VERSION ""

NS_ :

BS_:

BU_: CVC_I MHU TBOX FCAM_I MRR SRR_RL SRR_RR SRR_FL SRR_FR DUMMY_ECU ADCU_I AMP HUD

BO_ 1866 FCAM_Arbitration_Result: 8 FCAM_I
 SG_ CRC_FCAM_Arbitration_Result : 7|8@0+ (1,0) [0|255] ""  MHU,ADCU_I
 SG_ ALIVE_FCAM_Arbitration_Result : 11|4@0+ (1,0) [0|15] ""  MHU,ADCU_I
 SG_ FCAM_Arbitration_Log_Result : 15|4@0+ (1,0) [0|15] ""  MHU,ADCU_I
 SG_ FCAM_Arbitration_Lat_Result : 23|4@0+ (1,0) [0|15] ""  MHU,ADCU_I
 SG_ FCAM_Arbi_Fb : 19|4@0+ (1,0) [0|15] ""  MHU,ADCU_I
 SG_ FCAM_Acore_Diag : 31|4@0+ (1,0) [0|15] ""  MHU,ADCU_I
 SG_ FCAM_Rcore_Diag : 27|4@0+ (1,0) [0|15] ""  MHU,ADCU_I
 SG_ FCAM_Feature_Diag : 39|4@0+ (1,0) [0|15] ""  MHU,ADCU_I
 SG_ FCAM_ErrFCAM_SnSr_Diag : 35|4@0+ (1,0) [0|15] ""  MHU,ADCU_I
 SG_ FCAM_ErrFCAM_Feature_Diag : 47|4@0+ (1,0) [0|15] ""  MHU,ADCU_I
 SG_ FCAM_AACC_Arbitrator_Result : 43|1@0+ (1,0) [0|1] ""  ADCU_I
 SG_ FCAM_AEB_Arbitrator_Result : 42|1@0+ (1,0) [0|1] ""  ADCU_I
 SG_ FCAM_FCTB_Arbitrator_Result : 41|1@0+ (1,0) [0|1] ""  ADCU_I
 SG_ FCAM_ACPE_Arbitrator_Result : 40|1@0+ (1,0) [0|1] ""  ADCU_I
 SG_ FCAM_LCC_Arbitrator_Result : 48|1@0+ (1,0) [0|1] ""  ADCU_I
 SG_ FCAM_NOP_Arbitrator_Result : 49|1@0+ (1,0) [0|1] ""  ADCU_I
 SG_ FCAM_HWAPlus_Arbitrator_Result : 50|1@0+ (1,0) [0|1] ""  ADCU_I
 SG_ FCAM_LKA_Arbitrator_Result : 51|1@0+ (1,0) [0|1] ""  ADCU_I
 SG_ FCAM_ELKA_Arbitrator_Result : 52|1@0+ (1,0) [0|1] ""  ADCU_I
 SG_ FCAM_ESA_Arbitrator_Result : 53|1@0+ (1,0) [0|1] ""  ADCU_I
 SG_ FCAM_Arbitrator_Reserve_1 : 54|1@0+ (1,0) [0|1] ""  ADCU_I
 SG_ FCAM_Arbitrator_Reserve_2 : 55|1@0+ (1,0) [0|1] ""  ADCU_I

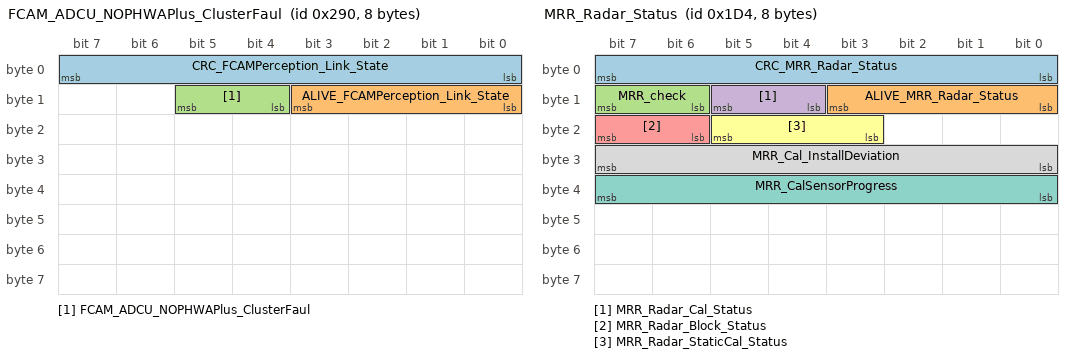
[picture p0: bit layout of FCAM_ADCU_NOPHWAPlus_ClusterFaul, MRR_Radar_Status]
BO_ 656 FCAM_ADCU_NOPHWAPlus_ClusterFaul: 8 FCAM_I
 SG_ CRC_FCAMPerception_Link_State : 7|8@0+ (1,0) [0|255] ""  MHU,ADCU_I
 SG_ ALIVE_FCAMPerception_Link_State : 11|4@0+ (1,0) [0|15] ""  MHU,ADCU_I
 SG_ FCAM_ADCU_NOPHWAPlus_ClusterFaul : 13|2@0+ (1,0) [0|3] ""  MHU,ADCU_I

BO_ 1970 FCAM_Synchronization_Req: 8 FCAM_I
 SG_ FCAM_I_Req_RandomData : 7|24@0+ (1,0) [0|16777215] ""  CVC_I
 SG_ FCAM_I_Req_MAC : 31|40@0+ (1,0) [0|1099511627775] ""  CVC_I

BO_ 468 MRR_Radar_Status: 8 MRR
 SG_ CRC_MRR_Radar_Status : 7|8@0+ (1,0) [0|255] ""  MHU,FCAM_I
 SG_ ALIVE_MRR_Radar_Status : 11|4@0+ (1,0) [0|15] ""  MHU,FCAM_I
 SG_ MRR_check : 15|2@0+ (1,0) [0|3] ""  MHU,FCAM_I
 SG_ MRR_Radar_Cal_Status : 13|2@0+ (1,0) [0|3] ""  MHU,FCAM_I
 SG_ MRR_Radar_Block_Status : 23|2@0+ (1,0) [0|3] ""  MHU,FCAM_I
 SG_ MRR_Radar_StaticCal_Status : 21|3@0+ (1,0) [0|7] ""  MHU,FCAM_I
 SG_ MRR_CalSensorProgress : 39|8@0+ (0.4,0) [0|100] "%"  MHU,FCAM_I
 SG_ MRR_Cal_InstallDeviation : 31|8@0+ (0.1,-12.8) [-12.8|12.7] "deg"  MHU,FCAM_I

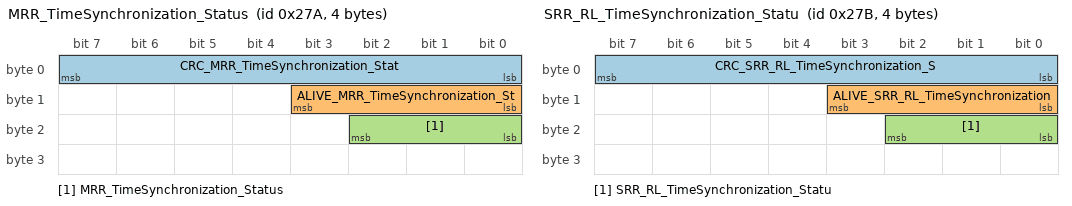
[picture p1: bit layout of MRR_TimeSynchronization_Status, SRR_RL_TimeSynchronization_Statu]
BO_ 634 MRR_TimeSynchronization_Status: 4 MRR
 SG_ CRC_MRR_TimeSynchronization_Stat : 7|8@0+ (1,0) [0|255] ""  FCAM_I,SRR_RL,SRR_RR,SRR_FL,SRR_FR,ADCU_I
 SG_ ALIVE_MRR_TimeSynchronization_St : 11|4@0+ (1,0) [0|15] ""  FCAM_I,SRR_RL,SRR_RR,SRR_FL,SRR_FR,ADCU_I
 SG_ MRR_TimeSynchronization_Status : 18|3@0+ (1,0) [0|4] ""  FCAM_I,SRR_RL,SRR_RR,SRR_FL,SRR_FR,ADCU_I

BO_ 635 SRR_RL_TimeSynchronization_Statu: 4 SRR_RL
 SG_ CRC_SRR_RL_TimeSynchronization_S : 7|8@0+ (1,0) [0|255] ""  FCAM_I,MRR,SRR_RR,SRR_FL,SRR_FR,ADCU_I
 SG_ ALIVE_SRR_RL_TimeSynchronization : 11|4@0+ (1,0) [0|15] ""  FCAM_I,MRR,SRR_RR,SRR_FL,SRR_FR,ADCU_I
 SG_ SRR_RL_TimeSynchronization_Statu : 18|3@0+ (1,0) [0|4] ""  FCAM_I,MRR,SRR_RR,SRR_FL,SRR_FR,ADCU_I

BO_ 831 SRR_RL_ObjList: 64 SRR_RL
 SG_ CRC_SRR_RL_ObjList : 7|8@0+ (1,0) [0|255] ""  MHU
 SG_ ALIVE_SRR_RL_ObjList : 11|4@0+ (1,0) [0|15] ""  MHU
 SG_ RL_Devtimestamp : 23|32@0+ (1,0) [0|4294967295] ""  MHU
 SG_ RL_Obj1_ID : 55|8@0+ (1,0) [0|255] ""  MHU
 SG_ RL_Obj1_DistLong : 63|13@0+ (0.2,-500) [-500|1138.2] ""  MHU
 SG_ RL_Obj1_DislLat : 66|11@0+ (0.2,-204.6) [-204.6|204.8] ""  MHU
 SG_ RL_Obj1_VrelLong : 87|10@0+ (0.25,-128) [-128|127.75] ""  MHU
 SG_ RL_Ob1j_DynProp : 93|3@0+ (1,0) [0|7] ""  MHU
 SG_ RL_Obj1_VrelLat : 90|9@0+ (0.25,-64) [-64|63.75] ""  MHU
 SG_ RL_Obj1_RCS : 97|8@0+ (0.5,-64) [-64|63.5] ""  MHU
 SG_ RL_Obj1_MeasState : 105|3@0+ (1,0) [0|7] ""  MHU
 SG_ RL_Obj1_ProbOfExist : 118|3@0+ (1,0) [0|7] ""  MHU
 SG_ RL_Obj1_ArelLong : 115|11@0+ (0.01,-10) [-10|10.47] ""  MHU
 SG_ RL_Obj1j_Class : 120|3@0+ (1,0) [0|7] ""  MHU
 SG_ RL_Obj1_ArelLat : 133|9@0+ (0.01,-2.5) [-2.5|2.61] ""  MHU
 SG_ RL_Obj1_Length : 151|8@0+ (0.2,0) [0|51] ""  MHU
 SG_ RL_Obj1_Width : 159|8@0+ (0.2,0) [0|51] ""  MHU
 SG_ RL_Obj2_ID : 167|8@0+ (1,0) [0|255] ""  MHU
 SG_ RL_Obj2_DistLong : 175|13@0+ (0.2,-500) [-500|1138.2] ""  MHU
 SG_ RL_Obj2_DislLat : 178|11@0+ (0.2,-204.6) [-204.6|204.8] ""  MHU
 SG_ RL_Obj2_VrelLong : 199|10@0+ (0.25,-128) [-128|127.75] ""  MHU
 SG_ RL_Obj2_DynProp : 205|3@0+ (1,0) [0|7] ""  MHU
 SG_ RL_Obj2_VrelLat : 202|9@0+ (0.25,-64) [-64|63.75] ""  MHU
 SG_ RL_Obj2_RCS : 223|8@0+ (0.5,-64) [-64|63.5] ""  MHU
 SG_ RL_Obj2_MeasState : 231|3@0+ (1,0) [0|7] ""  MHU
 SG_ RL_Obj2_ProbOfExist : 228|3@0+ (1,0) [0|7] ""  MHU
 SG_ RL_Obj2_ArelLong : 225|11@0+ (0.01,-10) [-10|10.47] ""  MHU
 SG_ RL_Obj2j_Class : 246|3@0+ (1,0) [0|7] ""  MHU
 SG_ RL_Obj2_ArelLat : 243|9@0+ (0.01,-2.5) [-2.5|2.61] ""  MHU
 SG_ RL_Obj2_Length : 263|8@0+ (0.2,0) [0|51] ""  MHU
 SG_ RL_Obj2_Width : 271|8@0+ (0.2,0) [0|51] ""  MHU
 SG_ RL_Obj3_ID : 279|8@0+ (1,0) [0|255] ""  MHU
 SG_ RL_Obj3_DistLong : 287|13@0+ (0.2,-500) [-500|1138.2] ""  MHU
 SG_ RL_Obj3_DislLat : 290|11@0+ (0.2,-204.6) [-204.6|204.8] ""  MHU
 SG_ RL_Obj3_VrelLong : 311|10@0+ (0.25,-128) [-128|127.75] ""  MHU
 SG_ RL_Obj3_DynProp : 250|3@0+ (1,0) [0|7] ""  MHU
 SG_ RL_Obj3_VrelLat : 327|9@0+ (0.25,-64) [-64|63.75] ""  MHU
 SG_ RL_Obj3_RCS : 359|8@0+ (0.5,-64) [-64|63.5] ""  MHU
 SG_ RL_Obj3_MeasState : 317|3@0+ (1,0) [0|7] ""  MHU
 SG_ RL_Obj3_ProbOfExist : 314|3@0+ (1,0) [0|7] ""  MHU
 SG_ RL_Obj3_ArelLong : 334|11@0+ (0.01,-10) [-10|10.47] ""  MHU
 SG_ RL_Obj3j_Class : 339|3@0+ (1,0) [0|7] ""  MHU
 SG_ RL_Obj3_ArelLat : 336|9@0+ (0.01,-2.5) [-2.5|2.61] ""  MHU
 SG_ RL_Obj3_Length : 367|8@0+ (0.2,0) [0|51] ""  MHU
 SG_ RL_Obj3_Width : 375|8@0+ (0.2,0) [0|51] ""  MHU
 SG_ RL_Obj4_ID : 383|8@0+ (1,0) [0|255] ""  MHU
 SG_ RL_Obj4_DistLong : 391|13@0+ (0.2,-500) [-500|1138.2] ""  MHU
 SG_ RL_Obj4_DislLat : 394|11@0+ (0.2,-204.6) [-204.6|204.8] ""  MHU
 SG_ RL_Obj4_VrelLong : 415|10@0+ (0.25,-128) [-128|127.75] ""  MHU
 SG_ RL_Obj4_DynProp : 421|3@0+ (1,0) [0|7] ""  MHU
 SG_ RL_Obj4_VrelLat : 418|9@0+ (0.25,-64) [-64|63.75] ""  MHU
 SG_ RL_Obj4_RCS : 439|8@0+ (0.5,-64) [-64|63.5] ""  MHU
 SG_ RL_Obj4_MeasState : 447|3@0+ (1,0) [0|7] ""  MHU
 SG_ RL_Obj4_ProbOfExist : 444|3@0+ (1,0) [0|7] ""  MHU
 SG_ RL_Obj4_ArelLong : 441|11@0+ (0.01,-10) [-10|10.47] ""  MHU
 SG_ RL_Obj4j_Class : 462|3@0+ (1,0) [0|7] ""  MHU
 SG_ RL_Obj4_ArelLat : 459|9@0+ (0.01,-2.5) [-2.5|2.61] ""  MHU
 SG_ RL_Obj4_Length : 479|8@0+ (0.2,0) [0|51] ""  MHU
 SG_ RL_Obj4_Width : 487|8@0+ (0.2,0) [0|51] ""  MHU

BO_ 307 SRR_RR_BSD_RCTA_DOW: 32 SRR_RR
 SG_ CRC_SRR_RR_BSD_RCTA_DOW : 7|8@0+ (1,0) [0|255] ""  CVC_I,MHU,FCAM_I,ADCU_I
 SG_ ALIVE_SRR_RR_BSD_RCTA_DOW : 11|4@0+ (1,0) [0|15] ""  CVC_I,MHU,FCAM_I,ADCU_I
 SG_ SRR_RR_BSD_check : 19|2@0+ (1,0) [0|3] ""  CVC_I,MHU,FCAM_I,ADCU_I
 SG_ SRR_RR_BSD_state : 22|3@0+ (1,0) [0|7] ""  CVC_I,MHU,FCAM_I,ADCU_I
 SG_ SRR_RR_BSD_AudChime_Feed : 23|1@0+ (1,0) [0|1] ""  CVC_I,MHU,FCAM_I,ADCU_I
 SG_ SRR_RR_BSD_IndLeft : 25|2@0+ (1,0) [0|3] ""  CVC_I,MHU,FCAM_I,ADCU_I
 SG_ SRR_RR_BSD_IndRight : 27|2@0+ (1,0) [0|3] ""  CVC_I,MHU,FCAM_I,ADCU_I
 SG_ SRR_RR_BSD_SndWarn : 29|2@0+ (1,0) [0|3] ""  CVC_I,MHU,FCAM_I,ADCU_I
 SG_ SRR_RR_BSD_Mode_Feed : 30|1@0+ (1,0) [0|1] ""  CVC_I,MHU,FCAM_I,ADCU_I
 SG_ SRR_RR_BSD_sens_Feed : 33|2@0+ (1,0) [0|3] ""  CVC_I,MHU,FCAM_I,ADCU_I
 SG_ SRR_RR_RCTA_IndRight : 39|2@0+ (1,0) [0|3] ""  CVC_I,MHU,FCAM_I,ADCU_I
 SG_ SRR_RR_RCTA_IndLeft : 17|2@0+ (1,0) [0|3] ""  CVC_I,MHU,FCAM_I,ADCU_I
 SG_ SRR_RR_RCTA_sens_Feed : 37|2@0+ (1,0) [0|3] ""  CVC_I,MHU,FCAM_I,ADCU_I
 SG_ SRR_RR_RCTA_state : 63|3@0+ (1,0) [0|7] ""  CVC_I,MHU,FCAM_I,ADCU_I
 SG_ SRR_RR_RCTA_SndWarn : 35|2@0+ (1,0) [0|3] ""  CVC_I,MHU,FCAM_I,ADCU_I
 SG_ SRR_RR_RCTA_Mode_Feed : 13|2@0+ (1,0) [0|3] ""  CVC_I,MHU,FCAM_I,ADCU_I
 SG_ SRR_RR_RCTA_check : 47|2@0+ (1,0) [0|3] ""  CVC_I,MHU,FCAM_I,ADCU_I
 SG_ SRR_RR_DOW_SndWarn : 50|2@0+ (1,0) [0|3] ""  CVC_I,MHU,FCAM_I,ADCU_I
 SG_ SRR_RR_DOW_WarnRight : 52|2@0+ (1,0) [0|3] ""  CVC_I,MHU,FCAM_I,ADCU_I
 SG_ SRR_RR_DOW_WarnLeft : 54|2@0+ (1,0) [0|3] ""  CVC_I,MHU,FCAM_I,ADCU_I
 SG_ SRR_RR_DOW_check : 40|2@0+ (1,0) [0|3] ""  CVC_I,MHU,FCAM_I,ADCU_I
 SG_ SRR_RR_DOW_state : 45|3@0+ (1,0) [0|7] ""  CVC_I,MHU,FCAM_I,ADCU_I
 SG_ SRR_RR_DOW_Mode_Feed : 42|2@0+ (1,0) [0|3] ""  CVC_I,MHU,FCAM_I,ADCU_I
 SG_ SRR_RR_Right_block : 15|2@0+ (1,0) [0|3] ""  CVC_I,MHU,FCAM_I,ADCU_I
 SG_ SRR_RR_Left_block : 60|2@0+ (1,0) [0|3] ""  CVC_I,MHU,FCAM_I,ADCU_I
 SG_ Obj_ID_RL : 71|8@0+ (1,0) [0|255] ""  CVC_I,MHU,FCAM_I,ADCU_I
 SG_ Obj_Class_RL : 79|3@0+ (1,0) [0|7] ""  CVC_I,MHU,FCAM_I,ADCU_I
 SG_ Obj_OrientationAngle_RL : 76|10@0+ (0.4,-180) [-180|229.2] "deg"  CVC_I,MHU,FCAM_I,ADCU_I
 SG_ Obj_DistLong_RL : 82|13@0+ (0.2,-500) [-500|1138.2] "m"  CVC_I,MHU,FCAM_I,ADCU_I
 SG_ Obj_DislLat_RL : 101|11@0+ (0.2,-204.6) [-204.6|204.8] "m"  CVC_I,MHU,FCAM_I,ADCU_I
 SG_ Obj_VrelLong_RL : 106|10@0+ (0.25,-128) [-128|127.75] "m/s"  CVC_I,MHU,FCAM_I,ADCU_I
 SG_ Obj_VrelLat_RL : 112|9@0+ (0.25,-64) [-64|63.75] "m/s"  CVC_I,MHU,FCAM_I,ADCU_I
 SG_ Obj_ID_RR : 135|8@0+ (1,0) [0|255] ""  CVC_I,MHU,FCAM_I,ADCU_I
 SG_ Obj_Class_RR : 143|3@0+ (1,0) [0|7] ""  CVC_I,MHU,FCAM_I,ADCU_I
 SG_ Obj_OrientationAngle_RR : 140|10@0+ (0.4,-180) [-180|229.2] "deg"  CVC_I,MHU,FCAM_I,ADCU_I
 SG_ Obj_DistLong_RR : 146|13@0+ (0.2,-500) [-500|1138.2] "m"  CVC_I,MHU,FCAM_I,ADCU_I
 SG_ Obj_DislLat_RR : 165|11@0+ (0.2,-204.6) [-204.6|204.8] "m"  CVC_I,MHU,FCAM_I,ADCU_I
 SG_ Obj_VrelLong_RR : 170|10@0+ (0.25,-128) [-128|127.75] "m/s"  CVC_I,MHU,FCAM_I,ADCU_I
 SG_ Obj_VrelLat_RR : 176|9@0+ (0.25,-64) [-64|63.75] "m/s"  CVC_I,MHU,FCAM_I,ADCU_I
 SG_ SRR_RR_RCTB_Mode_Feed : 193|2@0+ (1,0) [0|3] ""  CVC_I,MHU,FCAM_I,ADCU_I,HUD
 SG_ SRR_RR_RCTB_State : 58|3@0+ (1,0) [0|7] ""  CVC_I,MHU,FCAM_I,ADCU_I,HUD
 SG_ SRR_RR_RCTB_Check : 197|2@0+ (1,0) [0|3] ""  CVC_I,MHU,FCAM_I,ADCU_I,HUD
 SG_ SRR_RR_RCTB_Braking_Flag : 199|2@0+ (1,0) [0|3] ""  CVC_I,MHU,FCAM_I,ADCU_I,HUD
 SG_ SRR_RR_RCTB_Braking_Deceleration : 215|8@0+ (0.1,-6.5) [-6.5|6.5] "m/s2"  CVC_I,MHU,FCAM_I,ADCU_I,HUD
 SG_ SRR_RR_CollisionObjID : 223|8@0+ (1,0) [0|255] ""  CVC_I,MHU,FCAM_I,ADCU_I

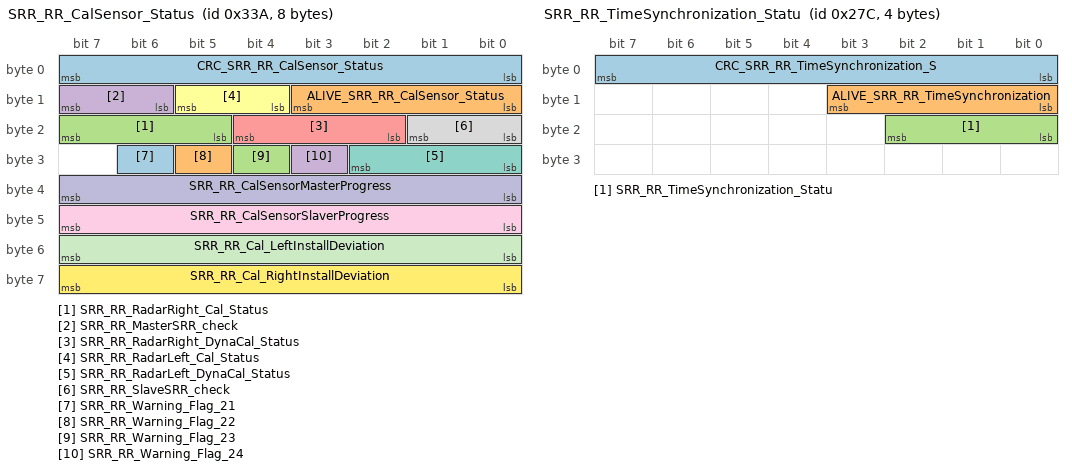
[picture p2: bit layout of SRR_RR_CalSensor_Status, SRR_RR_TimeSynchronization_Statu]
BO_ 826 SRR_RR_CalSensor_Status: 8 SRR_RR
 SG_ CRC_SRR_RR_CalSensor_Status : 7|8@0+ (1,0) [0|255] ""  CVC_I,MHU,FCAM_I,ADCU_I
 SG_ ALIVE_SRR_RR_CalSensor_Status : 11|4@0+ (1,0) [0|15] ""  CVC_I,MHU,FCAM_I,ADCU_I
 SG_ SRR_RR_RadarRight_Cal_Status : 23|3@0+ (1,0) [0|7] ""  CVC_I,MHU,FCAM_I,ADCU_I
 SG_ SRR_RR_MasterSRR_check : 15|2@0+ (1,0) [0|3] ""  CVC_I,MHU,FCAM_I,ADCU_I
 SG_ SRR_RR_RadarRight_DynaCal_Status : 20|3@0+ (1,0) [0|7] ""  CVC_I,MHU,ADCU_I
 SG_ SRR_RR_RadarLeft_Cal_Status : 13|2@0+ (1,0) [0|3] ""  CVC_I,MHU,FCAM_I,ADCU_I
 SG_ SRR_RR_RadarLeft_DynaCal_Status : 26|3@0+ (1,0) [0|7] ""  CVC_I,MHU,ADCU_I
 SG_ SRR_RR_SlaveSRR_check : 17|2@0+ (1,0) [0|3] ""  CVC_I,MHU,ADCU_I
 SG_ SRR_RR_CalSensorSlaverProgress : 47|8@0+ (0.4,0) [0|100] "%"  CVC_I,MHU,ADCU_I
 SG_ SRR_RR_CalSensorMasterProgress : 39|8@0+ (0.4,0) [0|100] "%"  CVC_I,MHU,ADCU_I
 SG_ SRR_RR_Cal_LeftInstallDeviation : 55|8@0+ (0.1,-12.8) [-12.8|12.7] "deg"  CVC_I,MHU,ADCU_I
 SG_ SRR_RR_Cal_RightInstallDeviation : 63|8@0+ (0.1,-12.8) [-12.8|12.7] "deg"  CVC_I,MHU,ADCU_I
 SG_ SRR_RR_Warning_Flag_21 : 30|1@0+ (1,0) [0|1] ""  CVC_I,MHU
 SG_ SRR_RR_Warning_Flag_22 : 29|1@0+ (1,0) [0|1] ""  CVC_I,MHU
 SG_ SRR_RR_Warning_Flag_23 : 28|1@0+ (1,0) [0|1] ""  CVC_I,MHU
 SG_ SRR_RR_Warning_Flag_24 : 27|1@0+ (1,0) [0|1] ""  CVC_I,MHU

BO_ 636 SRR_RR_TimeSynchronization_Statu: 4 SRR_RR
 SG_ CRC_SRR_RR_TimeSynchronization_S : 7|8@0+ (1,0) [0|255] ""  FCAM_I,MRR,SRR_RL,SRR_FL,SRR_FR,ADCU_I
 SG_ ALIVE_SRR_RR_TimeSynchronization : 11|4@0+ (1,0) [0|15] ""  FCAM_I,MRR,SRR_RL,SRR_FL,SRR_FR,ADCU_I
 SG_ SRR_RR_TimeSynchronization_Statu : 18|3@0+ (1,0) [0|4] ""  FCAM_I,MRR,SRR_RL,SRR_FL,SRR_FR,ADCU_I

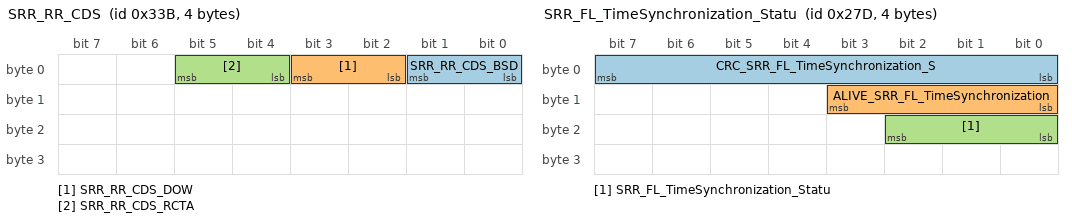
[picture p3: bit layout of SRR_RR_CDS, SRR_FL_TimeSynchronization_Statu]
BO_ 827 SRR_RR_CDS: 4 SRR_RR
 SG_ SRR_RR_CDS_BSD : 1|2@0+ (1,0) [0|3] ""  MHU,FCAM_I,ADCU_I
 SG_ SRR_RR_CDS_DOW : 3|2@0+ (1,0) [0|3] ""  MHU,FCAM_I,ADCU_I
 SG_ SRR_RR_CDS_RCTA : 5|2@0+ (1,0) [0|3] ""  MHU,FCAM_I,ADCU_I

BO_ 830 SRR_RR_ObjList: 64 SRR_RR
 SG_ CRC_SRR_RR_ObjList : 7|8@0+ (1,0) [0|255] ""  MHU
 SG_ ALIVE_SRR_RR_ObjList : 11|4@0+ (1,0) [0|15] ""  MHU
 SG_ RR_Devtimestamp : 23|32@0+ (1,0) [0|4294967295] ""  MHU
 SG_ RR_Obj1_ID : 55|8@0+ (1,0) [0|255] ""  MHU
 SG_ RR_Obj1_DistLong : 63|13@0+ (0.2,-500) [-500|1138.2] ""  MHU
 SG_ RR_Obj1_DislLat : 66|11@0+ (0.2,-204.6) [-204.6|204.8] ""  MHU
 SG_ RR_Obj1_VrelLong : 87|10@0+ (0.25,-128) [-128|127.75] ""  MHU
 SG_ RR_Obj1_DynProp : 93|3@0+ (1,0) [0|7] ""  MHU
 SG_ RR_Obj1_VrelLat : 90|9@0+ (0.25,-64) [-64|63.75] ""  MHU
 SG_ RR_Obj1_RCS : 97|8@0+ (0.5,-64) [-64|63.5] ""  MHU
 SG_ RR_Obj1_MeasState : 105|3@0+ (1,0) [0|7] ""  MHU
 SG_ RR_Obj1_ProbOfExist : 118|3@0+ (1,0) [0|7] ""  MHU
 SG_ RR_Obj1_ArelLong : 115|11@0+ (0.01,-10) [-10|10.47] ""  MHU
 SG_ RR_Obj1j_Class : 120|3@0+ (1,0) [0|7] ""  MHU
 SG_ RR_Obj1_ArelLat : 133|9@0+ (0.01,-2.5) [-2.5|2.61] ""  MHU
 SG_ RR_Obj1_Length : 151|8@0+ (0.2,0) [0|51] ""  MHU
 SG_ RR_Obj1_Width : 159|8@0+ (0.2,0) [0|51] ""  MHU
 SG_ RR_Obj2_ID : 167|8@0+ (1,0) [0|255] ""  MHU
 SG_ RR_Obj2_DistLong : 175|13@0+ (0.2,-500) [-500|1138.2] ""  MHU
 SG_ RR_Obj2_DislLat : 178|11@0+ (0.2,-204.6) [-204.6|204.8] ""  MHU
 SG_ RR_Obj2_VrelLong : 199|10@0+ (0.25,-128) [-128|127.75] ""  MHU
 SG_ RR_Obj2_DynProp : 205|3@0+ (1,0) [0|7] ""  MHU
 SG_ RR_Obj2_VrelLat : 202|9@0+ (0.25,-64) [-64|63.75] ""  MHU
 SG_ RR_Obj2_RCS : 223|8@0+ (0.5,-64) [-64|63.5] ""  MHU
 SG_ RR_Obj2_MeasState : 231|3@0+ (1,0) [0|7] ""  MHU
 SG_ RR_Obj2_ProbOfExist : 228|3@0+ (1,0) [0|7] ""  MHU
 SG_ RR_Obj2_ArelLong : 225|11@0+ (0.01,-10) [-10|10.47] ""  MHU
 SG_ RR_Obj2j_Class : 246|3@0+ (1,0) [0|7] ""  MHU
 SG_ RR_Obj2_ArelLat : 243|9@0+ (0.01,-2.5) [-2.5|2.61] ""  MHU
 SG_ RR_Obj2_Length : 263|8@0+ (0.2,0) [0|51] ""  MHU
 SG_ RR_Obj2_Width : 271|8@0+ (0.2,0) [0|51] ""  MHU
 SG_ RR_Obj3_ID : 279|8@0+ (1,0) [0|255] ""  MHU
 SG_ RR_Obj3_DistLong : 287|13@0+ (0.2,-500) [-500|1138.2] ""  MHU
 SG_ RR_Obj3_DislLat : 290|11@0+ (0.2,-204.6) [-204.6|204.8] ""  MHU
 SG_ RR_Obj3_VrelLong : 311|10@0+ (0.25,-128) [-128|127.75] ""  MHU
 SG_ RR_Obj3_DynProp : 250|3@0+ (1,0) [0|7] ""  MHU
 SG_ RR_Obj3_VrelLat : 327|9@0+ (0.25,-64) [-64|63.75] ""  MHU
 SG_ RR_Obj3_RCS : 359|8@0+ (0.5,-64) [-64|63.5] ""  MHU
 SG_ RR_Obj3_MeasState : 317|3@0+ (1,0) [0|7] ""  MHU
 SG_ RR_Obj3_ProbOfExist : 314|3@0+ (1,0) [0|7] ""  MHU
 SG_ RR_Obj3_ArelLong : 334|11@0+ (0.01,-10) [-10|10.47] ""  MHU
 SG_ RR_Obj3j_Class : 339|3@0+ (1,0) [0|7] ""  MHU
 SG_ RR_Obj3_ArelLat : 336|9@0+ (0.01,-2.5) [-2.5|2.61] ""  MHU
 SG_ RR_Obj3_Length : 367|8@0+ (0.2,0) [0|51] ""  MHU
 SG_ RR_Obj3_Width : 375|8@0+ (0.2,0) [0|51] ""  MHU
 SG_ RR_Obj4_ID : 383|8@0+ (1,0) [0|255] ""  MHU
 SG_ RR_Obj4_DistLong : 391|13@0+ (0.2,-500) [-500|1138.2] ""  MHU
 SG_ RR_Obj4_DislLat : 394|11@0+ (0.2,-204.6) [-204.6|204.8] ""  MHU
 SG_ RR_Obj4_VrelLong : 415|10@0+ (0.25,-128) [-128|127.75] ""  MHU
 SG_ RR_Obj4_DynProp : 421|3@0+ (1,0) [0|7] ""  MHU
 SG_ RR_Obj4_VrelLat : 418|9@0+ (0.25,-64) [-64|63.75] ""  MHU
 SG_ RR_Obj4_RCS : 439|8@0+ (0.5,-64) [-64|63.5] ""  MHU
 SG_ RR_Obj4_MeasState : 447|3@0+ (1,0) [0|7] ""  MHU
 SG_ RR_Obj4_ProbOfExist : 444|3@0+ (1,0) [0|7] ""  MHU
 SG_ RR_Obj4_ArelLong : 441|11@0+ (0.01,-10) [-10|10.47] ""  MHU
 SG_ RR_Obj4j_Class : 462|3@0+ (1,0) [0|7] ""  MHU
 SG_ RR_Obj4_ArelLat : 459|9@0+ (0.01,-2.5) [-2.5|2.61] ""  MHU
 SG_ RR_Obj4_Length : 479|8@0+ (0.2,0) [0|51] ""  MHU
 SG_ RR_Obj4_Width : 487|8@0+ (0.2,0) [0|51] ""  MHU

BO_ 637 SRR_FL_TimeSynchronization_Statu: 4 SRR_FL
 SG_ CRC_SRR_FL_TimeSynchronization_S : 7|8@0+ (1,0) [0|255] ""  FCAM_I,MRR,SRR_RL,SRR_RR,SRR_FR,ADCU_I
 SG_ ALIVE_SRR_FL_TimeSynchronization : 11|4@0+ (1,0) [0|15] ""  FCAM_I,MRR,SRR_RL,SRR_RR,SRR_FR,ADCU_I
 SG_ SRR_FL_TimeSynchronization_Statu : 18|3@0+ (1,0) [0|4] ""  FCAM_I,MRR,SRR_RL,SRR_RR,SRR_FR,ADCU_I

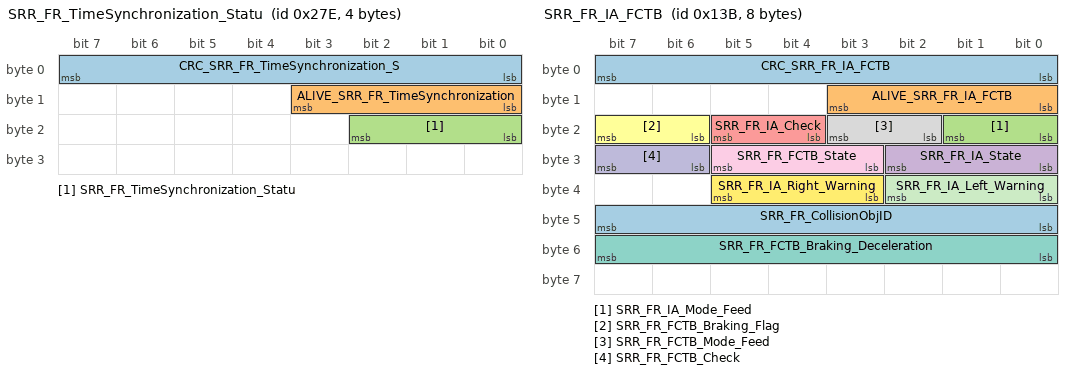
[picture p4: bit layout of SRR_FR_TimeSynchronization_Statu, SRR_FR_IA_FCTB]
BO_ 638 SRR_FR_TimeSynchronization_Statu: 4 SRR_FR
 SG_ CRC_SRR_FR_TimeSynchronization_S : 7|8@0+ (1,0) [0|255] ""  FCAM_I,MRR,SRR_RL,SRR_RR,SRR_FL,ADCU_I
 SG_ ALIVE_SRR_FR_TimeSynchronization : 11|4@0+ (1,0) [0|15] ""  FCAM_I,MRR,SRR_RL,SRR_RR,SRR_FL,ADCU_I
 SG_ SRR_FR_TimeSynchronization_Statu : 18|3@0+ (1,0) [0|4] ""  FCAM_I,MRR,SRR_RL,SRR_RR,SRR_FL,ADCU_I

BO_ 315 SRR_FR_IA_FCTB: 8 SRR_FR
 SG_ CRC_SRR_FR_IA_FCTB : 7|8@0+ (1,0) [0|255] ""  CVC_I,MHU,FCAM_I,ADCU_I,HUD
 SG_ ALIVE_SRR_FR_IA_FCTB : 11|4@0+ (1,0) [0|15] ""  CVC_I,MHU,FCAM_I,ADCU_I,HUD
 SG_ SRR_FR_IA_Mode_Feed : 17|2@0+ (1,0) [0|3] ""  CVC_I,MHU,FCAM_I,ADCU_I,HUD
 SG_ SRR_FR_IA_State : 26|3@0+ (1,0) [0|7] ""  CVC_I,MHU,FCAM_I,ADCU_I,HUD
 SG_ SRR_FR_IA_Check : 21|2@0+ (1,0) [0|3] ""  CVC_I,MHU,FCAM_I,ADCU_I,HUD
 SG_ SRR_FR_FCTB_Braking_Flag : 23|2@0+ (1,0) [0|3] ""  CVC_I,MHU,FCAM_I,ADCU_I,HUD
 SG_ SRR_FR_FCTB_Braking_Deceleration : 55|8@0+ (0.1,-6.5) [-6.5|6.5] "m/s2"  CVC_I,MHU,FCAM_I,ADCU_I,HUD
 SG_ SRR_FR_FCTB_Mode_Feed : 19|2@0+ (1,0) [0|3] ""  CVC_I,MHU,FCAM_I,ADCU_I,HUD
 SG_ SRR_FR_FCTB_State : 29|3@0+ (1,0) [0|7] ""  CVC_I,MHU,FCAM_I,ADCU_I,HUD
 SG_ SRR_FR_FCTB_Check : 31|2@0+ (1,0) [0|3] ""  CVC_I,MHU,FCAM_I,ADCU_I,HUD
 SG_ SRR_FR_IA_Left_Warning : 34|3@0+ (1,0) [0|7] ""  CVC_I,MHU,FCAM_I,ADCU_I,HUD
 SG_ SRR_FR_IA_Right_Warning : 37|3@0+ (1,0) [0|7] ""  CVC_I,MHU,FCAM_I,ADCU_I,HUD
 SG_ SRR_FR_CollisionObjID : 47|8@0+ (1,0) [0|255] ""  CVC_I,MHU,FCAM_I,ADCU_I,HUD

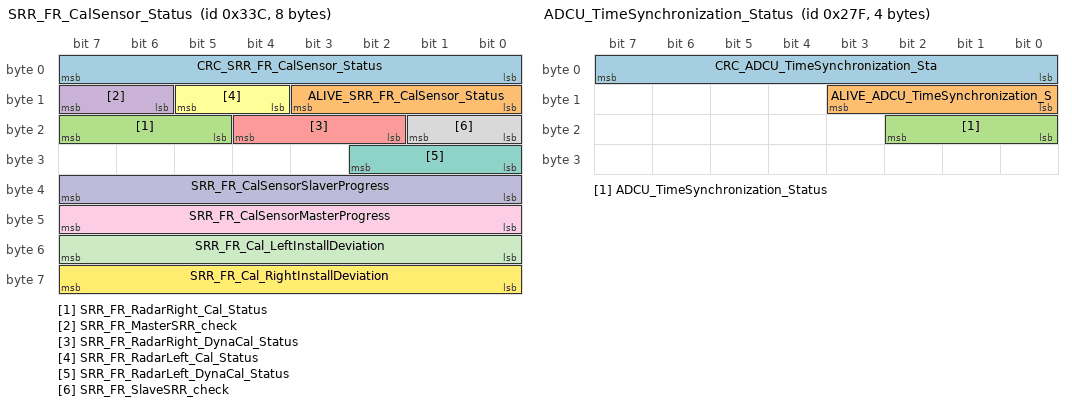
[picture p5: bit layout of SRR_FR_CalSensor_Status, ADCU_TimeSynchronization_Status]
BO_ 828 SRR_FR_CalSensor_Status: 8 SRR_FR
 SG_ CRC_SRR_FR_CalSensor_Status : 7|8@0+ (1,0) [0|255] ""  CVC_I,MHU,FCAM_I,ADCU_I
 SG_ ALIVE_SRR_FR_CalSensor_Status : 11|4@0+ (1,0) [0|15] ""  CVC_I,MHU,FCAM_I,ADCU_I
 SG_ SRR_FR_RadarRight_Cal_Status : 23|3@0+ (1,0) [0|7] ""  CVC_I,MHU,FCAM_I,ADCU_I
 SG_ SRR_FR_MasterSRR_check : 15|2@0+ (1,0) [0|3] ""  CVC_I,MHU,FCAM_I,ADCU_I
 SG_ SRR_FR_RadarRight_DynaCal_Status : 20|3@0+ (1,0) [0|7] ""  CVC_I,MHU,ADCU_I
 SG_ SRR_FR_RadarLeft_Cal_Status : 13|2@0+ (1,0) [0|3] ""  CVC_I,MHU,FCAM_I,ADCU_I
 SG_ SRR_FR_RadarLeft_DynaCal_Status : 26|3@0+ (1,0) [0|7] ""  CVC_I,MHU,ADCU_I
 SG_ SRR_FR_SlaveSRR_check : 17|2@0+ (1,0) [0|3] ""  CVC_I,MHU,ADCU_I
 SG_ SRR_FR_CalSensorMasterProgress : 47|8@0+ (0.4,0) [0|100] "%"  CVC_I,MHU,ADCU_I
 SG_ SRR_FR_CalSensorSlaverProgress : 39|8@0+ (0.4,0) [0|100] "%"  CVC_I,MHU,ADCU_I
 SG_ SRR_FR_Cal_LeftInstallDeviation : 55|8@0+ (0.1,-12.8) [-12.8|12.7] "deg"  CVC_I,MHU
 SG_ SRR_FR_Cal_RightInstallDeviation : 63|8@0+ (0.1,-12.8) [-12.8|12.7] "deg"  CVC_I,MHU

BO_ 639 ADCU_TimeSynchronization_Status: 4 ADCU_I
 SG_ CRC_ADCU_TimeSynchronization_Sta : 7|8@0+ (1,0) [0|255] ""  FCAM_I,MRR,SRR_RL,SRR_RR,SRR_FL,SRR_FR
 SG_ ALIVE_ADCU_TimeSynchronization_S : 11|4@0+ (1,0) [0|15] ""  FCAM_I,MRR,SRR_RL,SRR_RR,SRR_FL,SRR_FR
 SG_ ADCU_TimeSynchronization_Status : 18|3@0+ (1,0) [0|4] ""  FCAM_I,MRR,SRR_RL,SRR_RR,SRR_FL,SRR_FR

BO_ 543 ADCU_AEB_FCW: 12 ADCU_I
 SG_ CRC_ADCU_AEB_FCW : 7|8@0+ (1,0) [0|255] ""  MHU
 SG_ ALIVE_ADCU_AEB_FCW : 11|4@0+ (1,0) [0|15] ""  MHU
 SG_ ADCU_AEB_Warning : 13|2@0+ (1,0) [0|3] ""  MHU
 SG_ ADCU_AEB_State : 16|3@0+ (1,0) [0|7] ""  MHU
 SG_ ADCU_AEB_Mode_Feed : 23|2@0+ (1,0) [0|3] ""  MHU
 SG_ ADCU_AEB_check : 15|2@0+ (1,0) [0|3] ""  MHU
 SG_ ADCU_FCW_Mode_Feed : 21|1@0+ (1,0) [0|1] ""  MHU
 SG_ ADCU_FCW_Sens_Feed : 20|2@0+ (1,0) [0|3] ""  MHU
 SG_ ADCU_FCW_state : 18|2@0+ (1,0) [0|3] ""  MHU
 SG_ ADCU_FCW_check : 41|2@0+ (1,0) [0|3] ""  MHU
 SG_ ADCU_FCW_warning : 43|2@0+ (1,0) [0|3] ""  MHU
 SG_ ADCU_CV_AEB_Alert : 28|1@0+ (1,0) [0|1] ""  MHU
 SG_ ADCU_CV_FCW_Alert : 27|1@0+ (1,0) [0|1] ""  MHU
 SG_ ADCU_CV_PartialAEB_Alert : 26|1@0+ (1,0) [0|1] ""  MHU
 SG_ ADCU_CV_PreFill_Alert : 25|1@0+ (1,0) [0|1] ""  MHU
 SG_ ADCU_VD_AEB_Alert : 32|1@0+ (1,0) [0|1] ""  MHU
 SG_ ADCU_VD_DBS_Alert : 33|1@0+ (1,0) [0|1] ""  MHU
 SG_ ADCU_VD_EGOTAP_AEB_Alert : 34|1@0+ (1,0) [0|1] ""  MHU
 SG_ ADCU_VD_FCW_Alert : 35|1@0+ (1,0) [0|1] ""  MHU
 SG_ ADCU_VD_HeadOn_AEB_Alert : 36|1@0+ (1,0) [0|1] ""  MHU
 SG_ ADCU_VD_PartialAEB_Alert : 37|1@0+ (1,0) [0|1] ""  MHU
 SG_ ADCU_VD_Prefill_Alert : 38|1@0+ (1,0) [0|1] ""  MHU
 SG_ ADCU_VRU_AEB_Alert : 24|1@0+ (1,0) [0|1] ""  MHU
 SG_ ADCU_VRU_FCW_Alert : 39|1@0+ (1,0) [0|1] ""  MHU
 SG_ ADCU_VRU_PreFill_Alert : 29|1@0+ (1,0) [0|1] ""  MHU
 SG_ ADCU_Fusion_TTC : 55|16@0+ (1,0) [0|65535] "ms"  MHU
 SG_ ADCU_AB_TTC : 71|16@0+ (1,0) [0|65535] "ms"  MHU
 SG_ ADCU_AEB_Trigger_Source : 45|2@0+ (1,0) [0|3] ""  MHU
 SG_ ADCU_FCW_Trigger_Source : 47|2@0+ (1,0) [0|3] ""  MHU

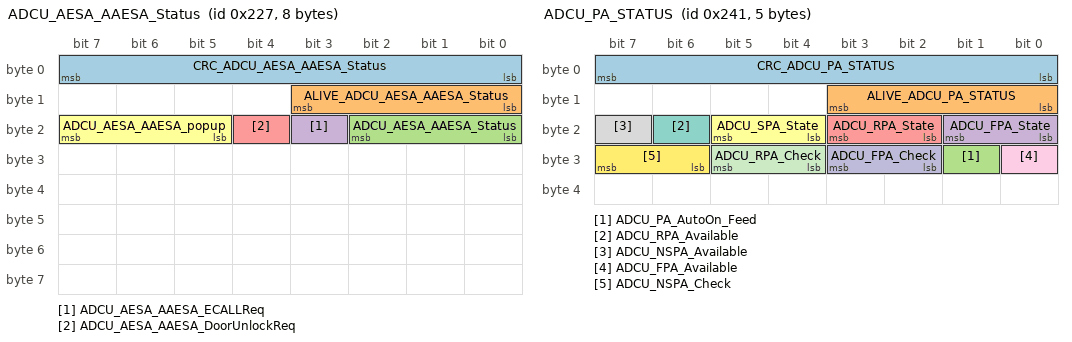
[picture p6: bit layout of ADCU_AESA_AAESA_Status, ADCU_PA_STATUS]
BO_ 551 ADCU_AESA_AAESA_Status: 8 ADCU_I
 SG_ CRC_ADCU_AESA_AAESA_Status : 7|8@0+ (1,0) [0|255] ""  CVC_I,MHU,TBOX
 SG_ ALIVE_ADCU_AESA_AAESA_Status : 11|4@0+ (1,0) [0|15] ""  CVC_I,MHU,TBOX
 SG_ ADCU_AESA_AAESA_Status : 18|3@0+ (1,0) [0|4] ""  CVC_I,MHU,TBOX
 SG_ ADCU_AESA_AAESA_ECALLReq : 19|1@0+ (1,0) [0|1] ""  CVC_I,MHU,TBOX
 SG_ ADCU_AESA_AAESA_DoorUnlockReq : 20|1@0+ (1,0) [0|1] ""  CVC_I,MHU,TBOX
 SG_ ADCU_AESA_AAESA_popup : 23|3@0+ (1,0) [0|6] ""  CVC_I,MHU,TBOX

BO_ 552 ADCU_ESA: 4 ADCU_I
 SG_ ESA_Freespace : 17|2@0+ (1,0) [0|3] ""  FCAM_I

BO_ 556 ADCU_FCAM_NOP_Status: 12 ADCU_I
 SG_ CRC_ADCU_FCAM_NOP_Status : 7|8@0+ (1,0) [0|255] ""  CVC_I,MHU,FCAM_I
 SG_ ALIVE_ADCU_FCAM_NOP_Status : 11|4@0+ (1,0) [0|15] ""  CVC_I,MHU,FCAM_I
 SG_ ADCU_FCAM_ALCA_state : 15|4@0+ (1,0) [0|15] ""  MHU,FCAM_I
 SG_ ADCU_NOP_check : 17|2@0+ (1,0) [0|3] ""  CVC_I,MHU,FCAM_I
 SG_ ADCU_NOP_state : 23|4@0+ (1,0) [0|15] ""  CVC_I,MHU,FCAM_I
 SG_ ADCU_NOP_ICON_Feed : 47|3@0+ (1,0) [0|7] ""  CVC_I,MHU,FCAM_I
 SG_ ADCU_NOP_txtpopup : 28|5@0+ (1,0) [0|31] ""  CVC_I,MHU,FCAM_I
 SG_ ADCU_NOP_Warning : 31|2@0+ (1,0) [0|3] ""  CVC_I,MHU,FCAM_I
 SG_ ADCU_NOP_AAESA_textpopup : 34|3@0+ (1,0) [0|7] ""  CVC_I,MHU,FCAM_I
 SG_ ADCU_NOP_TOR : 37|3@0+ (1,0) [0|7] ""  CVC_I,MHU,FCAM_I
 SG_ ADCU_eyesoff_Warning_Mode_2 : 42|3@0+ (1,0) [0|7] ""  CVC_I,MHU,FCAM_I
 SG_ ADCU_EOD : 43|1@0+ (1,0) [0|1] ""  CVC_I,MHU,FCAM_I
 SG_ ADCU_NOP_Mode_Feed : 19|2@0+ (1,0) [0|3] ""  CVC_I,MHU
 SG_ ADCU_NOP_Type_Feed : 39|2@0+ (1,0) [0|3] ""  CVC_I,MHU
 SG_ ADCU_DCA_Alert : 50|3@0+ (1,0) [0|7] ""  CVC_I,MHU
 SG_ ADCU_AAESA_Status : 53|3@0+ (1,0) [0|7] ""  CVC_I,MHU,FCAM_I
 SG_ ADCU_HWA_ALCA_Status : 63|4@0+ (1,0) [0|10] ""  CVC_I,MHU,FCAM_I
 SG_ ADCU_NOP_ALCA_Status : 59|4@0+ (1,0) [0|10] ""  CVC_I,MHU,FCAM_I
 SG_ ADCU_ALC_Mode_feed : 71|2@0+ (1,0) [0|3] ""  CVC_I,MHU,FCAM_I
 SG_ ADCU_ALC_txtpopup : 69|4@0+ (1,0) [0|15] ""  CVC_I,MHU,FCAM_I
 SG_ ADCU_AESA_popup : 65|3@0+ (1,0) [0|7] ""  CVC_I,MHU,FCAM_I
 SG_ ADCU_ALC_Mode_Gaze_Feed : 55|2@0+ (1,0) [0|3] ""  CVC_I,MHU,FCAM_I
 SG_ ADCU_ALC_Mode_Recommend_Feed : 78|2@0+ (1,0) [0|3] ""  CVC_I,MHU,FCAM_I
 SG_ ADCU_ALC_ICON_Feed : 76|4@0+ (1,0) [0|15] ""  CVC_I,MHU,FCAM_I
 SG_ ADCU_FCAM_NOP_ODD_Sts : 87|2@0+ (1,0) [0|3] ""  MHU,FCAM_I
 SG_ ADCU_FCAM_ALCA_TurnIndicatorReq : 85|3@0+ (1,0) [0|4] ""  CVC_I,MHU,FCAM_I
 SG_ ADCU_FCAM_ALCA_textpopup : 95|4@0+ (1,0) [0|15] ""  MHU,FCAM_I

BO_ 577 ADCU_PA_STATUS: 5 ADCU_I
 SG_ CRC_ADCU_PA_STATUS : 7|8@0+ (1,0) [0|255] ""  MHU
 SG_ ALIVE_ADCU_PA_STATUS : 11|4@0+ (1,0) [0|15] ""  MHU
 SG_ ADCU_PA_AutoOn_Feed : 25|1@0+ (1,0) [0|1] ""  MHU
 SG_ ADCU_FPA_State : 17|2@0+ (1,0) [0|3] ""  MHU
 SG_ ADCU_RPA_State : 19|2@0+ (1,0) [0|3] ""  MHU
 SG_ ADCU_SPA_State : 21|2@0+ (1,0) [0|3] ""  MHU
 SG_ ADCU_RPA_Available : 22|1@0+ (1,0) [0|1] ""  MHU
 SG_ ADCU_NSPA_Available : 23|1@0+ (1,0) [0|1] ""  MHU
 SG_ ADCU_FPA_Available : 24|1@0+ (1,0) [0|1] ""  MHU
 SG_ ADCU_FPA_Check : 27|2@0+ (1,0) [0|3] ""  MHU
 SG_ ADCU_RPA_Check : 29|2@0+ (1,0) [0|3] ""  MHU
 SG_ ADCU_NSPA_Check : 31|2@0+ (1,0) [0|3] ""  MHU

BO_ 579 ADCU_PA_FPA: 12 ADCU_I
 SG_ CRC_ADCU_PA_FPA : 7|8@0+ (1,0) [0|255] ""  MHU
 SG_ ALIVE_ADCU_PA_FPA : 11|4@0+ (1,0) [0|15] ""  MHU
 SG_ ADCU_FPA_AlertFIL : 18|3@0+ (1,0) [0|7] ""  MHU
 SG_ ADCU_FPA_AlertFOL : 21|3@0+ (1,0) [0|7] ""  MHU
 SG_ ADCU_FPA_AlertFIR : 26|3@0+ (1,0) [0|7] ""  MHU
 SG_ ADCU_FPA_AlertFOR : 29|3@0+ (1,0) [0|7] ""  MHU
 SG_ ADCU_FPA_AlertFSL : 34|3@0+ (1,0) [0|7] ""  MHU
 SG_ ADCU_FPA_AlertFSR : 37|3@0+ (1,0) [0|7] ""  MHU
 SG_ ADCU_FPA_DistFIL : 47|8@0+ (1,0) [0|255] ""  MHU
 SG_ ADCU_FPA_DistFOL : 55|8@0+ (1,0) [0|255] ""  MHU
 SG_ ADCU_FPA_DistFIR : 63|8@0+ (1,0) [0|255] ""  MHU
 SG_ ADCU_FPA_DistFOR : 71|8@0+ (1,0) [0|255] ""  MHU
 SG_ ADCU_FPA_DistFSL : 79|8@0+ (1,0) [0|255] ""  MHU
 SG_ ADCU_FPA_DistFSR : 87|8@0+ (1,0) [0|255] ""  MHU
 SG_ ADCU_FPA_ChimeReqFIL : 22|1@0+ (1,0) [0|1] ""  MHU
 SG_ ADCU_FPA_ChimeReqFOL : 23|1@0+ (1,0) [0|1] ""  MHU
 SG_ ADCU_FPA_ChimeReqFIR : 30|1@0+ (1,0) [0|1] ""  MHU
 SG_ ADCU_FPA_ChimeReqFOR : 31|1@0+ (1,0) [0|1] ""  MHU
 SG_ ADCU_FPA_ChimeReqFSL : 38|1@0+ (1,0) [0|1] ""  MHU
 SG_ ADCU_FPA_ChimeReqFSR : 39|1@0+ (1,0) [0|1] ""  MHU

BO_ 580 ADCU_PA_RPA: 12 ADCU_I
 SG_ CRC_ADCU_PA_RPA : 7|8@0+ (1,0) [0|255] ""  MHU
 SG_ ALIVE_ADCU_PA_RPA : 11|4@0+ (1,0) [0|15] ""  MHU
 SG_ ADCU_RPA_AlertRIL : 18|3@0+ (1,0) [0|7] ""  MHU
 SG_ ADCU_RPA_AlertROL : 21|3@0+ (1,0) [0|7] ""  MHU
 SG_ ADCU_RPA_AlertRIR : 26|3@0+ (1,0) [0|7] ""  MHU
 SG_ ADCU_RPA_AlertROR : 29|3@0+ (1,0) [0|7] ""  MHU
 SG_ ADCU_RPA_AlertRSL : 34|3@0+ (1,0) [0|7] ""  MHU
 SG_ ADCU_RPA_AlertRSR : 37|3@0+ (1,0) [0|7] ""  MHU
 SG_ ADCU_RPA_DistRIL : 47|8@0+ (1,0) [0|255] ""  MHU
 SG_ ADCU_RPA_DistROL : 55|8@0+ (1,0) [0|255] ""  MHU
 SG_ ADCU_RPA_DistRIR : 63|8@0+ (1,0) [0|255] ""  MHU
 SG_ ADCU_RPA_DistROR : 71|8@0+ (1,0) [0|255] ""  MHU
 SG_ ADCU_RPA_DistRSL : 79|8@0+ (1,0) [0|255] ""  MHU
 SG_ ADCU_RPA_DistRSR : 87|8@0+ (1,0) [0|255] ""  MHU
 SG_ ADCU_RPA_ChimeReqRIL : 22|1@0+ (1,0) [0|1] ""  MHU
 SG_ ADCU_RPA_ChimeReqROL : 23|1@0+ (1,0) [0|1] ""  MHU
 SG_ ADCU_RPA_ChimeReqRIR : 30|1@0+ (1,0) [0|1] ""  MHU
 SG_ ADCU_RPA_ChimeReqROR : 31|1@0+ (1,0) [0|1] ""  MHU
 SG_ ADCU_RPA_ChimeReqRSL : 38|1@0+ (1,0) [0|1] ""  MHU
 SG_ ADCU_RPA_ChimeReqRSR : 39|1@0+ (1,0) [0|1] ""  MHU

BO_ 582 ADCU_PA_NSPA: 16 ADCU_I
 SG_ CRC_ADCU_PA_NSPA : 7|8@0+ (1,0) [0|255] ""  MHU
 SG_ ALIVE_ADCU_PA_NSPA : 11|4@0+ (1,0) [0|15] ""  MHU
 SG_ ADCU_NSPA_AlertFSL1 : 18|3@0+ (1,0) [0|7] ""  MHU
 SG_ ADCU_NSPA_AlertFSL2 : 21|3@0+ (1,0) [0|7] ""  MHU
 SG_ ADCU_NSPA_AlertFSR1 : 26|3@0+ (1,0) [0|7] ""  MHU
 SG_ ADCU_NSPA_AlertFSR2 : 29|3@0+ (1,0) [0|7] ""  MHU
 SG_ ADCU_NSPA_AlertRSL1 : 34|3@0+ (1,0) [0|7] ""  MHU
 SG_ ADCU_NSPA_AlertRSL2 : 37|3@0+ (1,0) [0|7] ""  MHU
 SG_ ADCU_NSPA_AlertRSR1 : 42|3@0+ (1,0) [0|7] ""  MHU
 SG_ ADCU_NSPA_AlertRSR2 : 45|3@0+ (1,0) [0|7] ""  MHU
 SG_ ADCU_NSPA_DistFSL1 : 55|8@0+ (1,0) [0|255] ""  MHU
 SG_ ADCU_NSPA_DistFSL2 : 63|8@0+ (1,0) [0|255] ""  MHU
 SG_ ADCU_NSPA_DistFSR1 : 71|8@0+ (1,0) [0|255] ""  MHU
 SG_ ADCU_NSPA_DistFSR2 : 79|8@0+ (1,0) [0|255] ""  MHU
 SG_ ADCU_NSPA_DistRSL1 : 87|8@0+ (1,0) [0|255] ""  MHU
 SG_ ADCU_NSPA_DistRSL2 : 95|8@0+ (1,0) [0|255] ""  MHU
 SG_ ADCU_NSPA_DistRSR1 : 103|8@0+ (1,0) [0|255] ""  MHU
 SG_ ADCU_NSPA_DistRSR2 : 111|8@0+ (1,0) [0|255] ""  MHU
 SG_ ADCU_NSPA_ChimeReqFSL1 : 22|1@0+ (1,0) [0|1] ""  MHU
 SG_ ADCU_NSPA_ChimeReqFSL2 : 23|1@0+ (1,0) [0|1] ""  MHU
 SG_ ADCU_NSPA_ChimeReqFSR1 : 30|1@0+ (1,0) [0|1] ""  MHU
 SG_ ADCU_NSPA_ChimeReqFSR2 : 31|1@0+ (1,0) [0|1] ""  MHU
 SG_ ADCU_NSPA_ChimeReqRSL1 : 38|1@0+ (1,0) [0|1] ""  MHU
 SG_ ADCU_NSPA_ChimeReqRSL2 : 39|1@0+ (1,0) [0|1] ""  MHU
 SG_ ADCU_NSPA_ChimeReqRSR1 : 46|1@0+ (1,0) [0|1] ""  MHU
 SG_ ADCU_NSPA_ChimeReqRSR2 : 47|1@0+ (1,0) [0|1] ""  MHU

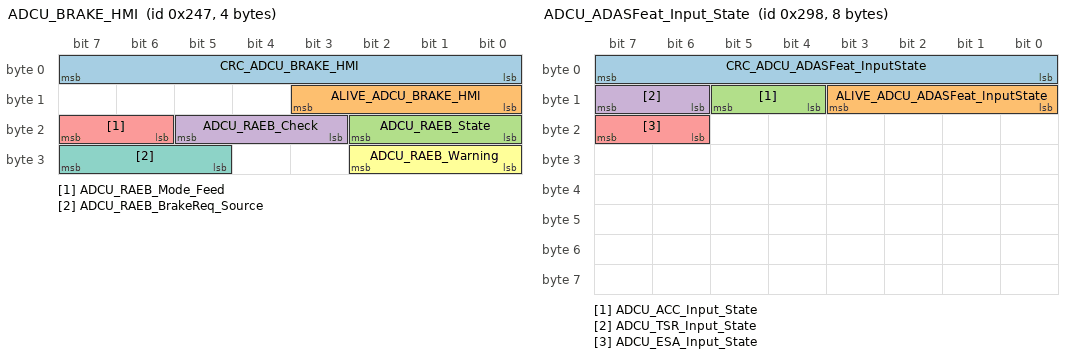
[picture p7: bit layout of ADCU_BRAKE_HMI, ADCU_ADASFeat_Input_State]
BO_ 583 ADCU_BRAKE_HMI: 4 ADCU_I
 SG_ CRC_ADCU_BRAKE_HMI : 7|8@0+ (1,0) [0|255] ""  CVC_I,MHU,FCAM_I
 SG_ ALIVE_ADCU_BRAKE_HMI : 11|4@0+ (1,0) [0|15] ""  CVC_I,MHU,FCAM_I
 SG_ ADCU_RAEB_State : 18|3@0+ (1,0) [0|7] ""  MHU
 SG_ ADCU_RAEB_Check : 21|3@0+ (1,0) [0|7] ""  MHU
 SG_ ADCU_RAEB_Mode_Feed : 23|2@0+ (1,0) [0|3] ""  MHU
 SG_ ADCU_RAEB_Warning : 26|3@0+ (1,0) [0|7] ""  MHU
 SG_ ADCU_RAEB_BrakeReq_Source : 31|3@0+ (1,0) [0|7] ""  CVC_I,MHU,FCAM_I

BO_ 605 ADCU_DrvPark_St: 8 ADCU_I
 SG_ ADCU_Driving_Parking_state : 23|4@0+ (1,0) [0|15] ""  FCAM_I

BO_ 664 ADCU_ADASFeat_Input_State: 8 ADCU_I
 SG_ CRC_ADCU_ADASFeat_InputState : 7|8@0+ (1,0) [0|255] ""  MHU,FCAM_I
 SG_ ALIVE_ADCU_ADASFeat_InputState : 11|4@0+ (1,0) [0|15] ""  MHU,FCAM_I
 SG_ ADCU_ACC_Input_State : 13|2@0+ (1,0) [0|3] ""  MHU,FCAM_I
 SG_ ADCU_TSR_Input_State : 15|2@0+ (1,0) [0|3] ""  MHU,FCAM_I
 SG_ ADCU_ESA_Input_State : 23|2@0+ (1,0) [0|3] ""  MHU,FCAM_I

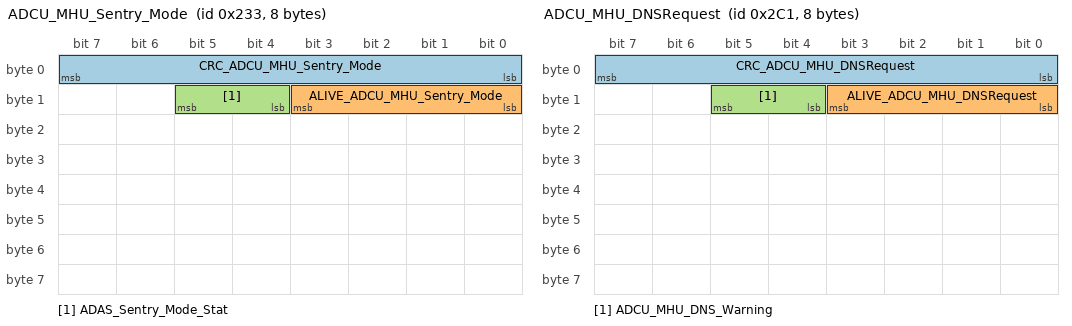
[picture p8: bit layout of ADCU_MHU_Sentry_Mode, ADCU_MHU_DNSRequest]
BO_ 563 ADCU_MHU_Sentry_Mode: 8 ADCU_I
 SG_ CRC_ADCU_MHU_Sentry_Mode : 7|8@0+ (1,0) [0|255] ""  MHU
 SG_ ALIVE_ADCU_MHU_Sentry_Mode : 11|4@0+ (1,0) [0|15] ""  MHU
 SG_ ADAS_Sentry_Mode_Stat : 13|2@0+ (1,0) [0|3] ""  MHU

BO_ 705 ADCU_MHU_DNSRequest: 8 ADCU_I
 SG_ CRC_ADCU_MHU_DNSRequest : 7|8@0+ (1,0) [0|255] ""  MHU
 SG_ ALIVE_ADCU_MHU_DNSRequest : 11|4@0+ (1,0) [0|15] ""  MHU
 SG_ ADCU_MHU_DNS_Warning : 13|2@0+ (1,0) [0|3] ""  MHU

BO_ 586 ADCU_ACPE_CMD: 16 ADCU_I
 SG_ CRC_ADCU_ACPE_CMD : 7|8@0+ (1,0) [0|255] ""  CVC_I,MHU,FCAM_I
 SG_ ALIVE_ADCU_ACPE_CMD : 11|4@0+ (1,0) [0|15] ""  CVC_I,MHU,FCAM_I
 SG_ ADCU_ACPE_PowerCommand : 18|3@0+ (1,0) [0|7] ""  CVC_I,MHU,FCAM_I
 SG_ ADCU_ACPE_BrakeCommand : 21|2@0+ (1,0) [0|3] ""  CVC_I,MHU,FCAM_I
 SG_ ADCU_ACPE_Available : 23|2@0+ (1,0) [0|3] ""  CVC_I,MHU,FCAM_I
 SG_ ADCU_ACPE_FuncActive : 19|1@0+ (1,0) [0|1] ""  CVC_I,MHU,FCAM_I
 SG_ ADCU_ACPE_HMICommand : 26|3@0+ (1,0) [0|7] ""  CVC_I,MHU,FCAM_I
 SG_ ADCU_ACPE_State : 29|3@0+ (1,0) [0|7] ""  CVC_I,MHU,FCAM_I
 SG_ ADCU_ACPE_Setting_Feed : 31|2@0+ (1,0) [0|3] ""  CVC_I,MHU,FCAM_I
 SG_ ADCU_ACPE_Sens_Feed : 33|2@0+ (1,0) [0|3] ""  CVC_I,MHU,FCAM_I
 SG_ ADCU_ACPE_Check : 36|3@0+ (1,0) [0|7] ""  CVC_I,MHU,FCAM_I
 SG_ ADCU_ACPE_TargetDeccel : 47|8@0+ (0.1,-6.5) [-6.5|6.5] "m/s2"  CVC_I,MHU,FCAM_I
 SG_ ACPE_FrontControler_Operate : 55|3@0+ (1,0) [0|7] ""  CVC_I,MHU,FCAM_I
 SG_ ACPE_RearControler_Operate : 52|3@0+ (1,0) [0|7] ""  CVC_I,MHU,FCAM_I

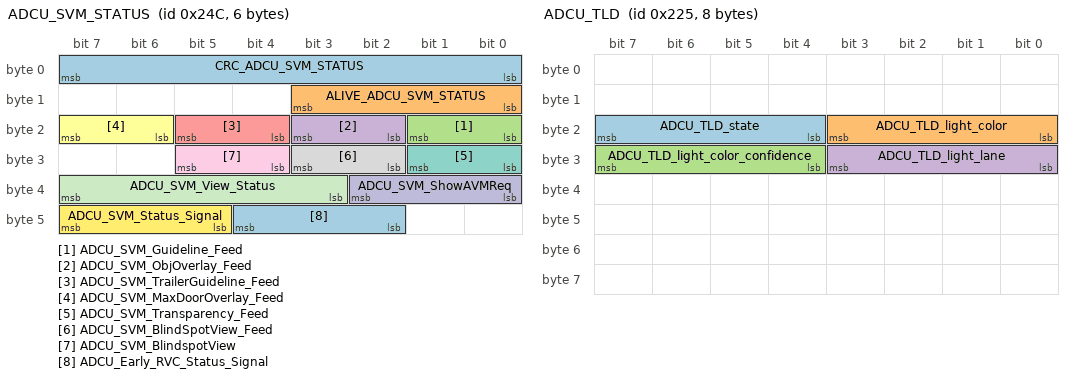
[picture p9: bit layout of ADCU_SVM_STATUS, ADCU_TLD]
BO_ 588 ADCU_SVM_STATUS: 6 ADCU_I
 SG_ CRC_ADCU_SVM_STATUS : 7|8@0+ (1,0) [0|255] ""  MHU
 SG_ ALIVE_ADCU_SVM_STATUS : 11|4@0+ (1,0) [0|14] ""  MHU
 SG_ ADCU_SVM_Guideline_Feed : 17|2@0+ (1,0) [0|3] ""  MHU
 SG_ ADCU_SVM_ObjOverlay_Feed : 19|2@0+ (1,0) [0|3] ""  MHU
 SG_ ADCU_SVM_TrailerGuideline_Feed : 21|2@0+ (1,0) [0|3] ""  MHU
 SG_ ADCU_SVM_MaxDoorOverlay_Feed : 23|2@0+ (1,0) [0|3] ""  MHU
 SG_ ADCU_SVM_Transparency_Feed : 25|2@0+ (1,0) [0|3] ""  MHU
 SG_ ADCU_SVM_BlindSpotView_Feed : 27|2@0+ (1,0) [0|3] ""  MHU
 SG_ ADCU_SVM_BlindspotView : 29|2@0+ (1,0) [0|3] ""  MHU
 SG_ ADCU_SVM_ShowAVMReq : 34|3@0+ (1,0) [0|7] ""  MHU
 SG_ ADCU_SVM_View_Status : 39|5@0+ (1,0) [0|31] ""  MHU
 SG_ ADCU_SVM_Status_Signal : 47|3@0+ (1,0) [0|7] ""  MHU
 SG_ ADCU_Early_RVC_Status_Signal : 44|3@0+ (1,0) [0|7] ""  MHU

BO_ 602 ADCU_SYS_HEALTH: 12 ADCU_I
 SG_ CRC_ADCU_SYS_HEALTH : 7|8@0+ (1,0) [0|255] ""  CVC_I,MHU,FCAM_I
 SG_ ALIVE_ADCU_SYS_HEALTH : 11|4@0+ (1,0) [0|15] ""  CVC_I,MHU,FCAM_I
 SG_ ADCU_SVM_FrontCam_Check : 17|2@0+ (1,0) [0|3] ""  CVC_I,MHU,FCAM_I
 SG_ ADCU_SVM_RearCam_Check : 19|2@0+ (1,0) [0|3] ""  CVC_I,MHU,FCAM_I
 SG_ ADCU_SVM_LeftCamera_Check : 21|2@0+ (1,0) [0|3] ""  CVC_I,MHU,FCAM_I
 SG_ ADCU_SVM_RightCamera_Check : 23|2@0+ (1,0) [0|3] ""  CVC_I,MHU,FCAM_I
 SG_ ADCU_TopRearCamera_Check : 25|2@0+ (1,0) [0|3] ""  CVC_I,MHU,FCAM_I
 SG_ ADCU_USS_FIL_Check : 27|2@0+ (1,0) [0|3] ""  CVC_I,MHU,FCAM_I
 SG_ ADCU_USS_FIR_Check : 29|2@0+ (1,0) [0|3] ""  CVC_I,MHU,FCAM_I
 SG_ ADCU_USS_FOL_Check : 31|2@0+ (1,0) [0|3] ""  CVC_I,MHU,FCAM_I
 SG_ ADCU_USS_FOR_Check : 33|2@0+ (1,0) [0|3] ""  CVC_I,MHU,FCAM_I
 SG_ ADCU_USS_FSL_Check : 35|2@0+ (1,0) [0|3] ""  CVC_I,MHU,FCAM_I
 SG_ ADCU_USS_FSR_Check : 37|2@0+ (1,0) [0|3] ""  CVC_I,MHU,FCAM_I
 SG_ ADCU_USS_RIL_Check : 39|2@0+ (1,0) [0|3] ""  CVC_I,MHU,FCAM_I
 SG_ ADCU_USS_RIR_Check : 41|2@0+ (1,0) [0|3] ""  CVC_I,MHU,FCAM_I
 SG_ ADCU_USS_ROL_Check : 43|2@0+ (1,0) [0|3] ""  CVC_I,MHU,FCAM_I
 SG_ ADCU_USS_ROR_Check : 45|2@0+ (1,0) [0|3] ""  CVC_I,MHU,FCAM_I
 SG_ ADCU_USS_RSL_Check : 47|2@0+ (1,0) [0|3] ""  CVC_I,MHU,FCAM_I
 SG_ ADCU_USS_RSR_Check : 49|2@0+ (1,0) [0|3] ""  CVC_I,MHU,FCAM_I
 SG_ ADCU_SVM_GMSL_Check : 51|2@0+ (1,0) [0|3] ""  CVC_I,MHU,FCAM_I
 SG_ ADCU_OS_Check : 54|3@0+ (1,0) [0|7] ""  CVC_I,MHU,FCAM_I
 SG_ ADCU_ERROR_CODE : 63|32@0+ (1,0) [0|4294967295] ""  CVC_I,MHU,FCAM_I
 SG_ ADCU_ErrFCAM_SnSr_Diag : 95|4@0+ (1,0) [0|15] ""  CVC_I,MHU,FCAM_I
 SG_ ADCU_ErrFCAM_Feature_Diag : 91|4@0+ (1,0) [0|15] ""  CVC_I,MHU,FCAM_I

BO_ 549 ADCU_TLD: 8 ADCU_I
 SG_ ADCU_TLD_state : 23|4@0+ (1,0) [0|15] ""  MHU,FCAM_I
 SG_ ADCU_TLD_light_color : 19|4@0+ (1,0) [0|15] ""  MHU,FCAM_I
 SG_ ADCU_TLD_light_color_confidence : 31|4@0+ (0.1,0) [0|1] ""  MHU,FCAM_I
 SG_ ADCU_TLD_light_lane : 27|4@0+ (1,0) [0|15] ""  MHU,FCAM_I

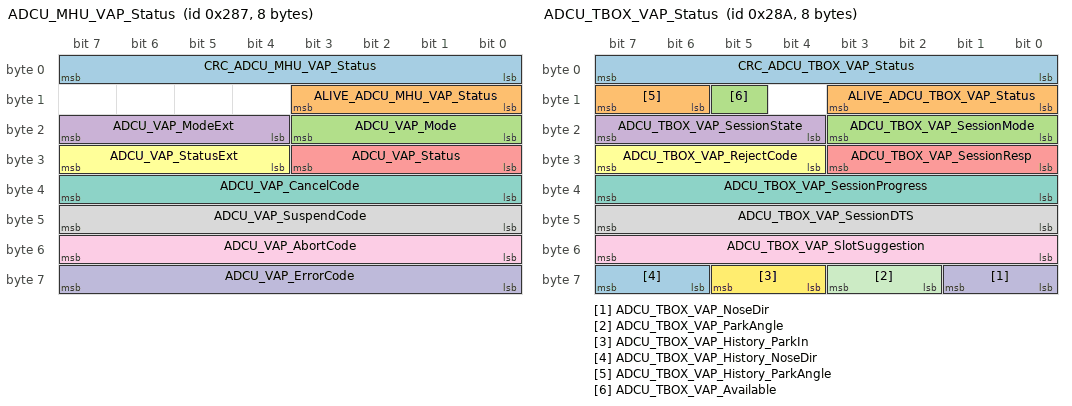
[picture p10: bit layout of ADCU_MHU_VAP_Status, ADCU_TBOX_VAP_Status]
BO_ 647 ADCU_MHU_VAP_Status: 8 ADCU_I
 SG_ CRC_ADCU_MHU_VAP_Status : 7|8@0+ (1,0) [0|255] ""  MHU,TBOX
 SG_ ALIVE_ADCU_MHU_VAP_Status : 11|4@0+ (1,0) [0|15] ""  MHU,TBOX
 SG_ ADCU_VAP_Mode : 19|4@0+ (1,0) [0|15] ""  MHU,TBOX
 SG_ ADCU_VAP_ModeExt : 23|4@0+ (1,0) [0|15] ""  MHU,TBOX
 SG_ ADCU_VAP_Status : 27|4@0+ (1,0) [0|15] ""  MHU,TBOX
 SG_ ADCU_VAP_StatusExt : 31|4@0+ (1,0) [0|15] ""  MHU,TBOX
 SG_ ADCU_VAP_CancelCode : 39|8@0+ (1,0) [0|255] ""  MHU,TBOX
 SG_ ADCU_VAP_SuspendCode : 47|8@0+ (1,0) [0|255] ""  MHU,TBOX
 SG_ ADCU_VAP_AbortCode : 55|8@0+ (1,0) [0|255] ""  MHU,TBOX
 SG_ ADCU_VAP_ErrorCode : 63|8@0+ (1,0) [0|255] ""  MHU,TBOX

BO_ 648 ADCU_MHU_VAP_ControlResp: 12 ADCU_I
 SG_ CRC_ADCU_MHU_VAP_ControlResp : 7|8@0+ (1,0) [0|255] ""  MHU
 SG_ ALIVE_ADCU_MHU_VAP_ControlResp : 11|4@0+ (1,0) [0|15] ""  MHU
 SG_ ADCU_MHU_VAP_SessionMode : 19|4@0+ (1,0) [0|15] ""  MHU
 SG_ ADCU_MHU_VAP_SessionState : 23|4@0+ (1,0) [0|15] ""  MHU
 SG_ ADCU_MHU_VAP_SessionResp : 27|4@0+ (1,0) [0|15] ""  MHU
 SG_ ADCU_MHU_VAP_RejectCode : 31|4@0+ (1,0) [0|15] ""  MHU
 SG_ ADCU_MHU_VAP_SessionProgress : 39|8@0+ (0.5,0) [0|100] "%"  MHU
 SG_ ADCU_MHU_VAP_SessionDTS : 47|8@0+ (5,0) [0|1275] "cm"  MHU
 SG_ ADCU_MHU_VAP_SlotSuggestion : 55|8@0+ (1,0) [0|255] ""  MHU
 SG_ ADCU_MHU_VAP_NoseDir : 57|2@0+ (1,0) [0|3] ""  MHU
 SG_ ADCU_MHU_VAP_ParkAngle : 59|2@0+ (1,0) [0|3] ""  MHU
 SG_ ADCU_MHU_VAP_History_ParkIn : 61|2@0+ (1,0) [0|3] ""  MHU
 SG_ ADCU_MHU_VAP_History_NoseDir : 63|2@0+ (1,0) [0|3] ""  MHU
 SG_ ADCU_MHU_VAP_History_ParkAngle : 83|2@0+ (1,0) [0|3] ""  MHU
 SG_ ADCU_MHU_VAP_History_DropOff : 71|10@0+ (1,0) [0|1023] ""  MHU
 SG_ ADCU_MHU_VAP_History_PathDist : 77|10@0+ (0.5,0) [0|511] "meter"  MHU
 SG_ ADCU_MHU_VAP_Available : 80|1@0+ (1,0) [0|1] ""  MHU

BO_ 650 ADCU_TBOX_VAP_Status: 8 ADCU_I
 SG_ CRC_ADCU_TBOX_VAP_Status : 7|8@0+ (1,0) [0|255] ""  TBOX
 SG_ ALIVE_ADCU_TBOX_VAP_Status : 11|4@0+ (1,0) [0|15] ""  TBOX
 SG_ ADCU_TBOX_VAP_SessionMode : 19|4@0+ (1,0) [0|15] ""  TBOX
 SG_ ADCU_TBOX_VAP_SessionState : 23|4@0+ (1,0) [0|15] ""  TBOX
 SG_ ADCU_TBOX_VAP_SessionResp : 27|4@0+ (1,0) [0|15] ""  TBOX
 SG_ ADCU_TBOX_VAP_RejectCode : 31|4@0+ (1,0) [0|15] ""  TBOX
 SG_ ADCU_TBOX_VAP_SessionProgress : 39|8@0+ (0.5,0) [0|100] "%"  TBOX
 SG_ ADCU_TBOX_VAP_SessionDTS : 47|8@0+ (5,0) [0|1275] "cm"  TBOX
 SG_ ADCU_TBOX_VAP_SlotSuggestion : 55|8@0+ (1,0) [0|255] ""  TBOX
 SG_ ADCU_TBOX_VAP_NoseDir : 57|2@0+ (1,0) [0|3] ""  TBOX
 SG_ ADCU_TBOX_VAP_ParkAngle : 59|2@0+ (1,0) [0|3] ""  TBOX
 SG_ ADCU_TBOX_VAP_History_ParkIn : 61|2@0+ (1,0) [0|3] ""  TBOX
 SG_ ADCU_TBOX_VAP_History_NoseDir : 63|2@0+ (1,0) [0|3] ""  TBOX
 SG_ ADCU_TBOX_VAP_History_ParkAngle : 15|2@0+ (1,0) [0|3] ""  TBOX
 SG_ ADCU_TBOX_VAP_Available : 13|1@0+ (1,0) [0|1] ""  TBOX

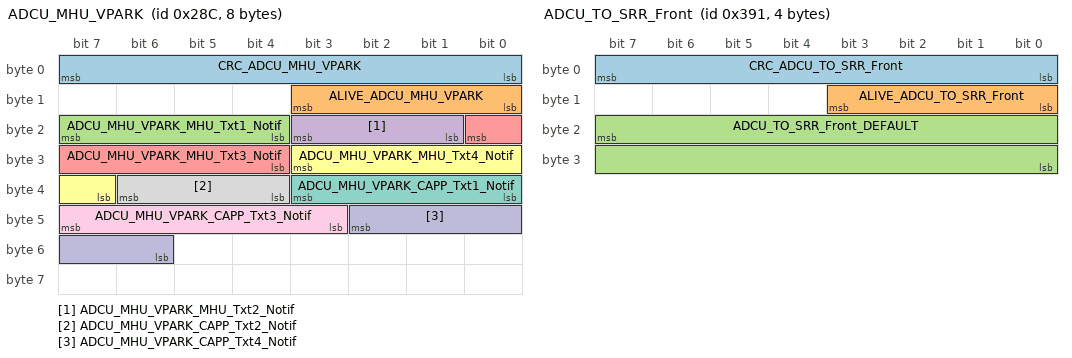
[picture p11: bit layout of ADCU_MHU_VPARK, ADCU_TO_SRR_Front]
BO_ 652 ADCU_MHU_VPARK: 8 ADCU_I
 SG_ CRC_ADCU_MHU_VPARK : 7|8@0+ (1,0) [0|255] ""  CVC_I,MHU
 SG_ ALIVE_ADCU_MHU_VPARK : 11|4@0+ (1,0) [0|15] ""  CVC_I,MHU
 SG_ ADCU_MHU_VPARK_MHU_Txt1_Notif : 23|4@0+ (1,0) [0|15] ""  CVC_I,MHU
 SG_ ADCU_MHU_VPARK_MHU_Txt2_Notif : 19|3@0+ (1,0) [0|7] ""  CVC_I,MHU
 SG_ ADCU_MHU_VPARK_MHU_Txt3_Notif : 16|5@0+ (1,0) [0|31] ""  CVC_I,MHU
 SG_ ADCU_MHU_VPARK_MHU_Txt4_Notif : 27|5@0+ (1,0) [0|31] ""  CVC_I,MHU
 SG_ ADCU_MHU_VPARK_CAPP_Txt1_Notif : 35|4@0+ (1,0) [0|15] ""  CVC_I,MHU
 SG_ ADCU_MHU_VPARK_CAPP_Txt2_Notif : 38|3@0+ (1,0) [0|7] ""  CVC_I,MHU
 SG_ ADCU_MHU_VPARK_CAPP_Txt3_Notif : 47|5@0+ (1,0) [0|31] ""  CVC_I,MHU
 SG_ ADCU_MHU_VPARK_CAPP_Txt4_Notif : 42|5@0+ (1,0) [0|31] ""  CVC_I,MHU

BO_ 913 ADCU_TO_SRR_Front: 4 ADCU_I
 SG_ CRC_ADCU_TO_SRR_Front : 7|8@0+ (1,0) [0|255] ""  SRR_FL,SRR_FR
 SG_ ALIVE_ADCU_TO_SRR_Front : 11|4@0+ (1,0) [0|15] ""  SRR_FL,SRR_FR
 SG_ ADCU_TO_SRR_Front_DEFAULT : 23|16@0+ (1,0) [0|65535] ""  SRR_FL,SRR_FR

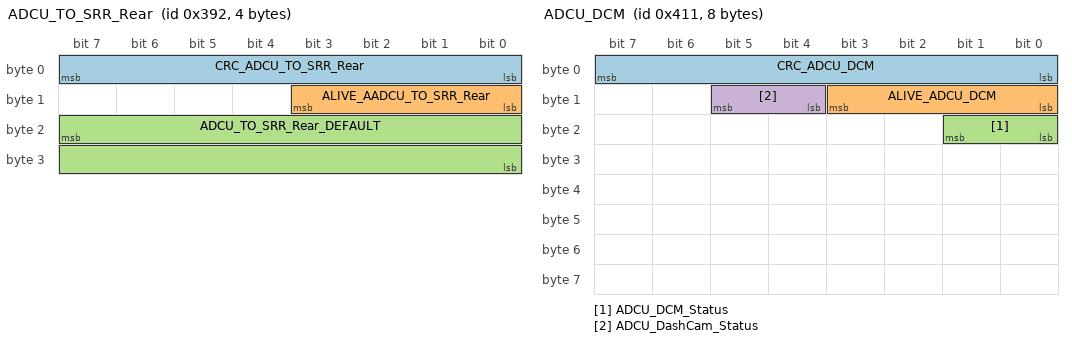
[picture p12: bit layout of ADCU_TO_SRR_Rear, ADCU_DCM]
BO_ 914 ADCU_TO_SRR_Rear: 4 ADCU_I
 SG_ CRC_ADCU_TO_SRR_Rear : 7|8@0+ (1,0) [0|255] ""  SRR_RL,SRR_RR
 SG_ ALIVE_AADCU_TO_SRR_Rear : 11|4@0+ (1,0) [0|15] ""  SRR_RL,SRR_RR
 SG_ ADCU_TO_SRR_Rear_DEFAULT : 23|16@0+ (1,0) [0|65535] ""  SRR_RL,SRR_RR

BO_ 1041 ADCU_DCM: 8 ADCU_I
 SG_ CRC_ADCU_DCM : 7|8@0+ (1,0) [0|255] ""  CVC_I,MHU
 SG_ ALIVE_ADCU_DCM : 11|4@0+ (1,0) [0|15] ""  CVC_I,MHU
 SG_ ADCU_DCM_Status : 17|2@0+ (1,0) [0|3] ""  CVC_I,MHU
 SG_ ADCU_DashCam_Status : 13|2@0+ (1,0) [0|3] ""  CVC_I

CM_ SG_ 1866 CRC_FCAM_Arbitration_Result "Checksum";
CM_ SG_ 1866 ALIVE_FCAM_Arbitration_Result "Alive Counter";
CM_ SG_ 1866 FCAM_Arbitration_Log_Result "longitudinal arbitration  result";
CM_ SG_ 1866 FCAM_Arbitration_Lat_Result "lateral arbitration result";
CM_ SG_ 1866 FCAM_Arbi_Fb "FCAM_Arbitrator_Feedback";
CM_ SG_ 1866 FCAM_Acore_Diag "A Core Diagnostics";
CM_ SG_ 1866 FCAM_Rcore_Diag "R Core Diagnostics";
CM_ SG_ 1866 FCAM_Feature_Diag "Error Signal Module";
CM_ SG_ 1866 FCAM_ErrFCAM_SnSr_Diag "FCAM (sensor related)";
CM_ SG_ 1866 FCAM_ErrFCAM_Feature_Diag "FCAM (feature related)";
CM_ SG_ 1866 FCAM_AACC_Arbitrator_Result "arbitrate output which feature's command";
CM_ SG_ 1866 FCAM_AEB_Arbitrator_Result "arbitrate output which feature's command";
CM_ SG_ 1866 FCAM_FCTB_Arbitrator_Result "arbitrate output which feature's command";
CM_ SG_ 1866 FCAM_ACPE_Arbitrator_Result "arbitrate output which feature's command";
CM_ SG_ 1866 FCAM_LCC_Arbitrator_Result "arbitrate output which feature's command";
CM_ SG_ 1866 FCAM_NOP_Arbitrator_Result "arbitrate output which feature's command";
CM_ SG_ 1866 FCAM_HWAPlus_Arbitrator_Result "arbitrate output which feature's command";
CM_ SG_ 1866 FCAM_LKA_Arbitrator_Result "arbitrate output which feature's command";
CM_ SG_ 1866 FCAM_ELKA_Arbitrator_Result "arbitrate output which feature's command";
CM_ SG_ 1866 FCAM_ESA_Arbitrator_Result "arbitrate output which feature's command";
CM_ SG_ 1866 FCAM_Arbitrator_Reserve_1 "reserved";
CM_ SG_ 1866 FCAM_Arbitrator_Reserve_2 "reserved";
CM_ SG_ 656 CRC_FCAMPerception_Link_State "Checksum";
CM_ SG_ 656 ALIVE_FCAMPerception_Link_State "Alive Counter";
CM_ SG_ 656 FCAM_ADCU_NOPHWAPlus_ClusterFaul "indicate fault";
CM_ SG_ 468 CRC_MRR_Radar_Status "Checksum";
CM_ SG_ 468 ALIVE_MRR_Radar_Status "Rolling_CounterRolling_Counter";
CM_ SG_ 468 MRR_check "Master Corner radar Check";
CM_ SG_ 468 MRR_Radar_Cal_Status "MRR calibration Status";
CM_ SG_ 468 MRR_Radar_Block_Status "MRR Block Status";
CM_ SG_ 468 MRR_Radar_StaticCal_Status "MRR static calibration status";
CM_ SG_ 468 MRR_CalSensorProgress "MRR radar calibration progress when get in";
CM_ SG_ 468 MRR_Cal_InstallDeviation "MRR radar install angle deviation  from auto calibration";
CM_ SG_ 634 CRC_MRR_TimeSynchronization_Stat "Checksum";
CM_ SG_ 634 ALIVE_MRR_TimeSynchronization_St "Rolling_Counter";
CM_ SG_ 634 MRR_TimeSynchronization_Status "MRR Radar TimeSynchronization_Status";
CM_ SG_ 635 CRC_SRR_RL_TimeSynchronization_S "Checksum";
CM_ SG_ 635 ALIVE_SRR_RL_TimeSynchronization "Rolling_Counter";
CM_ SG_ 635 SRR_RL_TimeSynchronization_Statu "SRR_RL Radar TimeSynchronization_Status";
CM_ SG_ 831 CRC_SRR_RL_ObjList "Checksum";
CM_ SG_ 831 RL_Devtimestamp "Latency";
CM_ SG_ 831 RL_Obj1_ID "This target ID - Rear Left SRR";
CM_ SG_ 831 RL_Obj1_DistLong "This ID target is a decomposition of the distance from the radar in the x-direction - Rear Left SRR";
CM_ SG_ 831 RL_Obj1_DislLat "Distance decomposition of this ID target from the radar in the y-direction - Rear Left SRR";
CM_ SG_ 831 RL_Obj1_VrelLong "This ID target distance radar x-direction velocity decomposition quantity - Rear Left SRR";
CM_ SG_ 831 RL_Ob1j_DynProp "Motion Status - Rear Left SRR";
CM_ SG_ 831 RL_Obj1_VrelLat "This ID target distance from the radar y-direction velocity decomposition quantity - Rear Left SRR";
CM_ SG_ 831 RL_Obj1_RCS "RCS of This Target ID - Rear Left SRR";
CM_ SG_ 831 RL_Obj1_MeasState "This Target ID is in Valid Tracking State - Rear Left SRR";
CM_ SG_ 831 RL_Obj1_ProbOfExist "Target Existence Probability (for this ID) - Rear Left SRR";
CM_ SG_ 831 RL_Obj1_ArelLong "Relative longitudinal acceleration, in m/s2  - Rear Left SRR";
CM_ SG_ 831 RL_Obj1j_Class "Estimated type of object - Rear Left SRR";
CM_ SG_ 831 RL_Obj1_ArelLat "Relative lateral acceleration in m/s2  - Rear Left SRR";
CM_ SG_ 831 RL_Obj1_Length "Size Length - Rear Left SRR";
CM_ SG_ 831 RL_Obj1_Width "Size Width - Rear Left SRR";
CM_ SG_ 831 RL_Obj2_ID "This target ID - Rear Left SRR";
CM_ SG_ 831 RL_Obj2_DistLong "This ID target is a decomposition of the distance from the radar in the x-direction - Rear Left SRR";
CM_ SG_ 831 RL_Obj2_DislLat "Distance decomposition of this ID target from the radar in the y-direction - Rear Left SRR";
CM_ SG_ 831 RL_Obj2_VrelLong "This ID target distance radar x-direction velocity decomposition quantity - Rear Left SRR";
CM_ SG_ 831 RL_Obj2_DynProp "Motion Status - Rear Left SRR";
CM_ SG_ 831 RL_Obj2_VrelLat "This ID target distance from the radar y-direction velocity decomposition quantity - Rear Left SRR";
CM_ SG_ 831 RL_Obj2_RCS "RCS of This Target ID - Rear Left SRR";
CM_ SG_ 831 RL_Obj2_MeasState "This Target ID is in Valid Tracking State - Rear Left SRR";
CM_ SG_ 831 RL_Obj2_ProbOfExist "Target Existence Probability (for this ID) - Rear Left SRR";
CM_ SG_ 831 RL_Obj2_ArelLong "Relative longitudinal acceleration, in m/s2  - Rear Left SRR";
CM_ SG_ 831 RL_Obj2j_Class "Estimated type of object - Rear Left SRR";
CM_ SG_ 831 RL_Obj2_ArelLat "Relative lateral acceleration in m/s2  - Rear Left SRR";
CM_ SG_ 831 RL_Obj2_Length "Size Length - Rear Left SRR";
CM_ SG_ 831 RL_Obj2_Width "Size Width - Rear Left SRR";
CM_ SG_ 831 RL_Obj3_ID "This target ID - Rear Left SRR";
CM_ SG_ 831 RL_Obj3_DistLong "This ID target is a decomposition of the distance from the radar in the x-direction - Rear Left SRR";
CM_ SG_ 831 RL_Obj3_DislLat "Distance decomposition of this ID target from the radar in the y-direction - Rear Left SRR";
CM_ SG_ 831 RL_Obj3_VrelLong "This ID target distance radar x-direction velocity decomposition quantity - Rear Left SRR";
CM_ SG_ 831 RL_Obj3_DynProp "Motion Status - Rear Left SRR";
CM_ SG_ 831 RL_Obj3_VrelLat "This ID target distance from the radar y-direction velocity decomposition quantity - Rear Left SRR";
CM_ SG_ 831 RL_Obj3_RCS "RCS of This Target ID - Rear Left SRR";
CM_ SG_ 831 RL_Obj3_MeasState "This Target ID is in Valid Tracking State - Rear Left SRR";
CM_ SG_ 831 RL_Obj3_ProbOfExist "Target Existence Probability (for this ID) - Rear Left SRR";
CM_ SG_ 831 RL_Obj3_ArelLong "Relative longitudinal acceleration, in m/s2  - Rear Left SRR";
CM_ SG_ 831 RL_Obj3j_Class "Estimated type of object - Rear Left SRR";
CM_ SG_ 831 RL_Obj3_ArelLat "Relative lateral acceleration in m/s2  - Rear Left SRR";
CM_ SG_ 831 RL_Obj3_Length "Size Length - Rear Left SRR";
CM_ SG_ 831 RL_Obj3_Width "Size Width - Rear Left SRR";
CM_ SG_ 831 RL_Obj4_ID "This target ID - Rear Left SRR";
CM_ SG_ 831 RL_Obj4_DistLong "This ID target is a decomposition of the distance from the radar in the x-direction - Rear Left SRR";
CM_ SG_ 831 RL_Obj4_DislLat "Distance decomposition of this ID target from the radar in the y-direction - Rear Left SRR";
CM_ SG_ 831 RL_Obj4_VrelLong "This ID target distance radar x-direction velocity decomposition quantity - Rear Left SRR";
CM_ SG_ 831 RL_Obj4_DynProp "Motion Status - Rear Left SRR";
CM_ SG_ 831 RL_Obj4_VrelLat "This ID target distance from the radar y-direction velocity decomposition quantity - Rear Left SRR";
CM_ SG_ 831 RL_Obj4_RCS "RCS of This Target ID - Rear Left SRR";
CM_ SG_ 831 RL_Obj4_MeasState "This Target ID is in Valid Tracking State - Rear Left SRR";
CM_ SG_ 831 RL_Obj4_ProbOfExist "Target Existence Probability (for this ID) - Rear Left SRR";
CM_ SG_ 831 RL_Obj4_ArelLong "Relative longitudinal acceleration, in m/s2  - Rear Left SRR";
CM_ SG_ 831 RL_Obj4j_Class "Estimated type of object - Rear Left SRR";
CM_ SG_ 831 RL_Obj4_ArelLat "Relative lateral acceleration in m/s2  - Rear Left SRR";
CM_ SG_ 831 RL_Obj4_Length "Size Length - Rear Left SRR";
CM_ SG_ 831 RL_Obj4_Width "Size Width - Rear Left SRR";
CM_ BO_ 307 "SRR_RR Blind Sport Detection";
CM_ SG_ 307 CRC_SRR_RR_BSD_RCTA_DOW "Checksum";
CM_ SG_ 307 ALIVE_SRR_RR_BSD_RCTA_DOW "Alive Counter";
CM_ SG_ 307 SRR_RR_BSD_check "Blind Sport Detection Check";
CM_ SG_ 307 SRR_RR_BSD_state "Blind Sport Detection State Feedback";
CM_ SG_ 307 SRR_RR_BSD_AudChime_Feed "Blind Sport Detection Audible Chime Feedback";
CM_ SG_ 307 SRR_RR_BSD_IndLeft "Left Blind Sport Detection Warning";
CM_ SG_ 307 SRR_RR_BSD_IndRight "Right Blind Sport Detection Warning";
CM_ SG_ 307 SRR_RR_BSD_SndWarn "Rear Blind Sport Detection warning sound en disable";
CM_ SG_ 307 SRR_RR_BSD_Mode_Feed "Blind Sport Detection On Off Feedback";
CM_ SG_ 307 SRR_RR_BSD_sens_Feed "Blind Sport Detection sensitivity Feedback";
CM_ SG_ 307 SRR_RR_RCTA_IndRight "Right Rear Cross Traffic Alert (RCTA) System Warning";
CM_ SG_ 307 SRR_RR_RCTA_IndLeft "Left Rear Cross Traffic Alert (RCTA) System Warning";
CM_ SG_ 307 SRR_RR_RCTA_sens_Feed "Rear Cross Traffic Alert  Warning Sensitivity Feedback";
CM_ SG_ 307 SRR_RR_RCTA_state "Rear Cross Traffic Alert  Warning State";
CM_ SG_ 307 SRR_RR_RCTA_SndWarn "Rear Cross Traffic Alert warning sound en disable";
CM_ SG_ 307 SRR_RR_RCTA_Mode_Feed "Rear Cross Traffic Alert  Warning On Off Feedback";
CM_ SG_ 307 SRR_RR_RCTA_check "Rear Cross Traffic Alert Check";
CM_ SG_ 307 SRR_RR_DOW_SndWarn "Door Open Sound Warning en disable";
CM_ SG_ 307 SRR_RR_DOW_WarnRight "Right Door Open Warning";
CM_ SG_ 307 SRR_RR_DOW_WarnLeft "Left Door Open Warning";
CM_ SG_ 307 SRR_RR_DOW_check "Door Opening Warning Check";
CM_ SG_ 307 SRR_RR_DOW_state "Door Open Warning State";
CM_ SG_ 307 SRR_RR_DOW_Mode_Feed "Door Open Warning Mode select Feedback";
CM_ SG_ 307 SRR_RR_Right_block "Rear Right Radar Blockage state";
CM_ SG_ 307 SRR_RR_Left_block "Rear Left Radar Blockage state";
CM_ SG_ 307 Obj_ID_RL "This target ID";
CM_ SG_ 307 Obj_Class_RL "Estimated type of object";
CM_ SG_ 307 Obj_OrientationAngle_RL "azimuth";
CM_ SG_ 307 Obj_DistLong_RL "This ID target is a decomposition of the distance from the radar in the x-direction.";
CM_ SG_ 307 Obj_DislLat_RL "Distance decomposition of this ID target from the radar in the y-direction.";
CM_ SG_ 307 Obj_VrelLong_RL "This ID target distance radar x-direction velocity decomposition quantity";
CM_ SG_ 307 Obj_VrelLat_RL "This ID target distance from the radar y-direction velocity decomposition quantity";
CM_ SG_ 307 Obj_ID_RR "This target ID";
CM_ SG_ 307 Obj_Class_RR "Estimated type of object";
CM_ SG_ 307 Obj_OrientationAngle_RR "azimuth";
CM_ SG_ 307 Obj_DistLong_RR "This ID target is a decomposition of the distance from the radar in the x-direction.";
CM_ SG_ 307 Obj_DislLat_RR "Distance decomposition of this ID target from the radar in the y-direction.";
CM_ SG_ 307 Obj_VrelLong_RR "This ID target distance radar x-direction velocity decomposition quantity";
CM_ SG_ 307 Obj_VrelLat_RR "This ID target distance from the radar y-direction velocity decomposition quantity";
CM_ SG_ 307 SRR_RR_RCTB_Mode_Feed "Intersection Assist State  Mode select";
CM_ SG_ 307 SRR_RR_RCTB_State "Intersection Assist State";
CM_ SG_ 307 SRR_RR_RCTB_Check "Intersection Assist State Check";
CM_ SG_ 307 SRR_RR_RCTB_Braking_Flag "RCTB brake request flag";
CM_ SG_ 307 SRR_RR_RCTB_Braking_Deceleration "RCTB brake request deceleration";
CM_ SG_ 307 SRR_RR_CollisionObjID "Rear radar collision object";
CM_ SG_ 826 CRC_SRR_RR_CalSensor_Status "Checksum";
CM_ SG_ 826 ALIVE_SRR_RR_CalSensor_Status "Rolling_Counter";
CM_ SG_ 826 SRR_RR_RadarRight_Cal_Status "SRR rear right calibration Status";
CM_ SG_ 826 SRR_RR_MasterSRR_check "Master Corner radar Check";
CM_ SG_ 826 SRR_RR_RadarRight_DynaCal_Status "SRR rear right dynamic calibration status";
CM_ SG_ 826 SRR_RR_RadarLeft_Cal_Status "SRR rear left calibration Status";
CM_ SG_ 826 SRR_RR_RadarLeft_DynaCal_Status "SRR rear left dynamic calibration status";
CM_ SG_ 826 SRR_RR_SlaveSRR_check "Slave Corner radar Check";
CM_ SG_ 826 SRR_RR_CalSensorSlaverProgress "Slaver(Left) radar calibration progress when get in";
CM_ SG_ 826 SRR_RR_CalSensorMasterProgress "Master(Right) radar calibration progress when get in";
CM_ SG_ 826 SRR_RR_Cal_LeftInstallDeviation "left radar install angle deviation  from auto calibration";
CM_ SG_ 826 SRR_RR_Cal_RightInstallDeviation "right radar install angle deviation  from auto calibration";
CM_ SG_ 636 CRC_SRR_RR_TimeSynchronization_S "Checksum";
CM_ SG_ 636 ALIVE_SRR_RR_TimeSynchronization "Rolling_Counter";
CM_ SG_ 636 SRR_RR_TimeSynchronization_Statu "SRR_RR Radar TimeSynchronization_Status";
CM_ SG_ 827 SRR_RR_CDS_BSD "Blind Spot Detection CDS";
CM_ SG_ 827 SRR_RR_CDS_DOW "Door Open Warning CDS";
CM_ SG_ 827 SRR_RR_CDS_RCTA "Rear Cross Traffic Alert CDS";
CM_ SG_ 830 CRC_SRR_RR_ObjList "Checksum";
CM_ SG_ 830 RR_Devtimestamp "Latency";
CM_ SG_ 830 RR_Obj1_ID "This target ID - Rear Left SRR";
CM_ SG_ 830 RR_Obj1_DistLong "This ID target is a decomposition of the distance from the radar in the x-direction - Rear Left SRR";
CM_ SG_ 830 RR_Obj1_DislLat "Distance decomposition of this ID target from the radar in the y-direction - Rear Left SRR";
CM_ SG_ 830 RR_Obj1_VrelLong "This ID target distance radar x-direction velocity decomposition quantity - Rear Left SRR";
CM_ SG_ 830 RR_Obj1_DynProp "Motion Status - Rear Left SRR";
CM_ SG_ 830 RR_Obj1_VrelLat "This ID target distance from the radar y-direction velocity decomposition quantity - Rear Left SRR";
CM_ SG_ 830 RR_Obj1_RCS "RCS of This Target ID - Rear Left SRR";
CM_ SG_ 830 RR_Obj1_MeasState "This Target ID is in Valid Tracking State - Rear Left SRR";
CM_ SG_ 830 RR_Obj1_ProbOfExist "Target Existence Probability (for this ID) - Rear Left SRR";
CM_ SG_ 830 RR_Obj1_ArelLong "Relative longitudinal acceleration, in m/s2  - Rear Left SRR";
CM_ SG_ 830 RR_Obj1j_Class "Estimated type of object - Rear Left SRR";
CM_ SG_ 830 RR_Obj1_ArelLat "Relative lateral acceleration in m/s2  - Rear Left SRR";
CM_ SG_ 830 RR_Obj1_Length "Size Length - Rear Left SRR";
CM_ SG_ 830 RR_Obj1_Width "Size Width - Rear Left SRR";
CM_ SG_ 830 RR_Obj2_ID "This target ID - Rear Left SRR";
CM_ SG_ 830 RR_Obj2_DistLong "This ID target is a decomposition of the distance from the radar in the x-direction - Rear Left SRR";
CM_ SG_ 830 RR_Obj2_DislLat "Distance decomposition of this ID target from the radar in the y-direction - Rear Left SRR";
CM_ SG_ 830 RR_Obj2_VrelLong "This ID target distance radar x-direction velocity decomposition quantity - Rear Left SRR";
CM_ SG_ 830 RR_Obj2_DynProp "Motion Status - Rear Left SRR";
CM_ SG_ 830 RR_Obj2_VrelLat "This ID target distance from the radar y-direction velocity decomposition quantity - Rear Left SRR";
CM_ SG_ 830 RR_Obj2_RCS "RCS of This Target ID - Rear Left SRR";
CM_ SG_ 830 RR_Obj2_MeasState "This Target ID is in Valid Tracking State - Rear Left SRR";
CM_ SG_ 830 RR_Obj2_ProbOfExist "Target Existence Probability (for this ID) - Rear Left SRR";
CM_ SG_ 830 RR_Obj2_ArelLong "Relative longitudinal acceleration, in m/s2  - Rear Left SRR";
CM_ SG_ 830 RR_Obj2j_Class "Estimated type of object - Rear Left SRR";
CM_ SG_ 830 RR_Obj2_ArelLat "Relative lateral acceleration in m/s2  - Rear Left SRR";
CM_ SG_ 830 RR_Obj2_Length "Size Length - Rear Left SRR";
CM_ SG_ 830 RR_Obj2_Width "Size Width - Rear Left SRR";
CM_ SG_ 830 RR_Obj3_ID "This target ID - Rear Left SRR";
CM_ SG_ 830 RR_Obj3_DistLong "This ID target is a decomposition of the distance from the radar in the x-direction - Rear Left SRR";
CM_ SG_ 830 RR_Obj3_DislLat "Distance decomposition of this ID target from the radar in the y-direction - Rear Left SRR";
CM_ SG_ 830 RR_Obj3_VrelLong "This ID target distance radar x-direction velocity decomposition quantity - Rear Left SRR";
CM_ SG_ 830 RR_Obj3_DynProp "Motion Status - Rear Left SRR";
CM_ SG_ 830 RR_Obj3_VrelLat "This ID target distance from the radar y-direction velocity decomposition quantity - Rear Left SRR";
CM_ SG_ 830 RR_Obj3_RCS "RCS of This Target ID - Rear Left SRR";
CM_ SG_ 830 RR_Obj3_MeasState "This Target ID is in Valid Tracking State - Rear Left SRR";
CM_ SG_ 830 RR_Obj3_ProbOfExist "Target Existence Probability (for this ID) - Rear Left SRR";
CM_ SG_ 830 RR_Obj3_ArelLong "Relative longitudinal acceleration, in m/s2  - Rear Left SRR";
CM_ SG_ 830 RR_Obj3j_Class "Estimated type of object - Rear Left SRR";
CM_ SG_ 830 RR_Obj3_ArelLat "Relative lateral acceleration in m/s2  - Rear Left SRR";
CM_ SG_ 830 RR_Obj3_Length "Size Length - Rear Left SRR";
CM_ SG_ 830 RR_Obj3_Width "Size Width - Rear Left SRR";
CM_ SG_ 830 RR_Obj4_ID "This target ID - Rear Left SRR";
CM_ SG_ 830 RR_Obj4_DistLong "This ID target is a decomposition of the distance from the radar in the x-direction - Rear Left SRR";
CM_ SG_ 830 RR_Obj4_DislLat "Distance decomposition of this ID target from the radar in the y-direction - Rear Left SRR";
CM_ SG_ 830 RR_Obj4_VrelLong "This ID target distance radar x-direction velocity decomposition quantity - Rear Left SRR";
CM_ SG_ 830 RR_Obj4_DynProp "Motion Status - Rear Left SRR";
CM_ SG_ 830 RR_Obj4_VrelLat "This ID target distance from the radar y-direction velocity decomposition quantity - Rear Left SRR";
CM_ SG_ 830 RR_Obj4_RCS "RCS of This Target ID - Rear Left SRR";
CM_ SG_ 830 RR_Obj4_MeasState "This Target ID is in Valid Tracking State - Rear Left SRR";
CM_ SG_ 830 RR_Obj4_ProbOfExist "Target Existence Probability (for this ID) - Rear Left SRR";
CM_ SG_ 830 RR_Obj4_ArelLong "Relative longitudinal acceleration, in m/s2  - Rear Left SRR";
CM_ SG_ 830 RR_Obj4j_Class "Estimated type of object - Rear Left SRR";
CM_ SG_ 830 RR_Obj4_ArelLat "Relative lateral acceleration in m/s2  - Rear Left SRR";
CM_ SG_ 830 RR_Obj4_Length "Size Length - Rear Left SRR";
CM_ SG_ 830 RR_Obj4_Width "Size Width - Rear Left SRR";
CM_ SG_ 637 CRC_SRR_FL_TimeSynchronization_S "Checksum";
CM_ SG_ 637 ALIVE_SRR_FL_TimeSynchronization "Rolling_Counter";
CM_ SG_ 637 SRR_FL_TimeSynchronization_Statu "SRR_FL Radar TimeSynchronization_Status";
CM_ SG_ 638 CRC_SRR_FR_TimeSynchronization_S "Checksum";
CM_ SG_ 638 ALIVE_SRR_FR_TimeSynchronization "Rolling_Counter";
CM_ SG_ 638 SRR_FR_TimeSynchronization_Statu "SRR_FR Radar TimeSynchronization_Status";
CM_ SG_ 315 CRC_SRR_FR_IA_FCTB "Checksum";
CM_ SG_ 315 ALIVE_SRR_FR_IA_FCTB "Rolling_Counter";
CM_ SG_ 315 SRR_FR_IA_Mode_Feed "Intersection Assist State  Mode select";
CM_ SG_ 315 SRR_FR_IA_State "Intersection Assist State";
CM_ SG_ 315 SRR_FR_IA_Check "Intersection Assist State Check";
CM_ SG_ 315 SRR_FR_FCTB_Braking_Flag "FCTB brake request flag";
CM_ SG_ 315 SRR_FR_FCTB_Braking_Deceleration "FCTB brake request deceleration";
CM_ SG_ 315 SRR_FR_FCTB_Mode_Feed "Intersection Assist State  Mode select";
CM_ SG_ 315 SRR_FR_FCTB_State "Intersection Assist State";
CM_ SG_ 315 SRR_FR_FCTB_Check "Intersection Assist State Check";
CM_ SG_ 315 SRR_FR_IA_Left_Warning "Intersecion assist left warning";
CM_ SG_ 315 SRR_FR_IA_Right_Warning "Intersecion assist right warning";
CM_ SG_ 315 SRR_FR_CollisionObjID "Front radar collision object";
CM_ SG_ 828 CRC_SRR_FR_CalSensor_Status "Checksum";
CM_ SG_ 828 ALIVE_SRR_FR_CalSensor_Status "Rolling_Counter";
CM_ SG_ 828 SRR_FR_RadarRight_Cal_Status "SRR rear right calibration Status";
CM_ SG_ 828 SRR_FR_MasterSRR_check "Master Corner radar Check";
CM_ SG_ 828 SRR_FR_RadarRight_DynaCal_Status "SRR rear right dynamic calibration status";
CM_ SG_ 828 SRR_FR_RadarLeft_Cal_Status "SRR rear left calibration Status";
CM_ SG_ 828 SRR_FR_RadarLeft_DynaCal_Status "SRR rear left dynamic calibration status";
CM_ SG_ 828 SRR_FR_SlaveSRR_check "Slave Corner radar Check";
CM_ SG_ 828 SRR_FR_CalSensorMasterProgress "Master(Right) radar calibration progress when get in";
CM_ SG_ 828 SRR_FR_CalSensorSlaverProgress "Slaver(Left) radar calibration progress when get in";
CM_ SG_ 828 SRR_FR_Cal_LeftInstallDeviation "left radar install angle deviation  from auto calibration";
CM_ SG_ 828 SRR_FR_Cal_RightInstallDeviation "right radar install angle deviation  from auto calibration";
CM_ SG_ 639 CRC_ADCU_TimeSynchronization_Sta "Checksum";
CM_ SG_ 639 ALIVE_ADCU_TimeSynchronization_S "Rolling_Counter";
CM_ SG_ 639 ADCU_TimeSynchronization_Status "ADCU Radar TimeSynchronization_Status";
CM_ BO_ 543 "For redundancy when ADCU controlling AEB when FCAM fail, or switching logic not work, and ADCU sending out AEB flag";
CM_ SG_ 543 CRC_ADCU_AEB_FCW "Checksum";
CM_ SG_ 543 ALIVE_ADCU_AEB_FCW "Alive Counter";
CM_ SG_ 543 ADCU_AEB_Warning "Automatic Emergency Brake Warning Mode";
CM_ SG_ 543 ADCU_AEB_State "Automatic Emergency Brake State";
CM_ SG_ 543 ADCU_AEB_Mode_Feed "AEB Mode feedback";
CM_ SG_ 543 ADCU_AEB_check "Automatic Emergency Brake Check";
CM_ SG_ 543 ADCU_FCW_Mode_Feed "FCW mode feedback";
CM_ SG_ 543 ADCU_FCW_Sens_Feed "FCW sensitivity feedback";
CM_ SG_ 543 ADCU_FCW_state "FCW status";
CM_ SG_ 543 ADCU_FCW_check "Forward Collision Warning Check";
CM_ SG_ 543 ADCU_FCW_warning "Forward Collision Warning Warning popup";
CM_ SG_ 543 ADCU_CV_AEB_Alert "Full AEB braking flag from Vision for crossing usecase";
CM_ SG_ 543 ADCU_CV_FCW_Alert "FCW flag from Visionfor crossing usecase";
CM_ SG_ 543 ADCU_CV_PartialAEB_Alert "Partial AEB braking flag from Visionfor crossing usecase";
CM_ SG_ 543 ADCU_CV_PreFill_Alert "Prefill flag from Visionfor crossing usecase";
CM_ SG_ 543 ADCU_VD_AEB_Alert "Full AEB braking flag from Visionfor preceding usecase";
CM_ SG_ 543 ADCU_VD_DBS_Alert "DBS/EBA flag from Visionforfor preceding usecase";
CM_ SG_ 543 ADCU_VD_EGOTAP_AEB_Alert "AEB flag from Visionfor turn across path use case";
CM_ SG_ 543 ADCU_VD_FCW_Alert "FCW flag from Visionfor for preceding usecase";
CM_ SG_ 543 ADCU_VD_HeadOn_AEB_Alert "Full AEB braking flag from Visionfor headon usecase";
CM_ SG_ 543 ADCU_VD_PartialAEB_Alert "Partial AEB braking flag from Visionfor preceding usecase";
CM_ SG_ 543 ADCU_VD_Prefill_Alert "Prefill flag from Visionfor preceding usecase";
CM_ SG_ 543 ADCU_VRU_AEB_Alert "AEB braking flag from Visionfor VRU usecase";
CM_ SG_ 543 ADCU_VRU_FCW_Alert "FCW flag from Vision for VRU usecase";
CM_ SG_ 543 ADCU_VRU_PreFill_Alert "Prefill flag from Vision for VRU usecase";
CM_ SG_ 543 ADCU_Fusion_TTC "Time to collision from Fusion";
CM_ SG_ 543 ADCU_AB_TTC "Time to collision from AB";
CM_ SG_ 543 ADCU_AEB_Trigger_Source "AEB trigger source (Vision or Fusion)";
CM_ SG_ 543 ADCU_FCW_Trigger_Source "FCW trigger source (Vision or Fusion)";
CM_ SG_ 551 ADCU_AESA_AAESA_Status "The signal will be used to indicate the MRM status";
CM_ SG_ 551 ADCU_AESA_AAESA_ECALLReq "The signal will be used to triggered the ECALL functionality once the AESA or AAESA control is done and the vehicle is brough to stop";
CM_ SG_ 551 ADCU_AESA_AAESA_DoorUnlockReq "The signal will be used to unlock the doors once the AESA or AAESA  control is done and the vehicle is brough to stop";
CM_ SG_ 551 ADCU_AESA_AAESA_popup "AESA_AAESA Popup";
CM_ SG_ 552 ESA_Freespace "This signal describes whether there are freespace in adjacent lane in ESA planned path, no collision risks with overtaking or oncoming vehicles or with VRU.";
CM_ SG_ 556 ADCU_FCAM_ALCA_state "ALCA State Status";
CM_ SG_ 556 ADCU_NOP_check "NOP error check";
CM_ SG_ 556 ADCU_NOP_state "NOP state";
CM_ SG_ 556 ADCU_NOP_ICON_Feed "NOP ICON";
CM_ SG_ 556 ADCU_NOP_txtpopup "NOP popup message";
CM_ SG_ 556 ADCU_NOP_Warning "NOP hauptic warning request";
CM_ SG_ 556 ADCU_NOP_AAESA_textpopup "AESA popup";
CM_ SG_ 556 ADCU_NOP_TOR "NOP take over request";
CM_ SG_ 556 ADCU_NOP_Mode_Feed "Settings Mode for NOP";
CM_ SG_ 556 ADCU_DCA_Alert "Direct Control Alert warning request for R171";
CM_ SG_ 556 ADCU_AAESA_Status "AASEA State";
CM_ SG_ 556 ADCU_HWA_ALCA_Status "HWA_ALCA_Status";
CM_ SG_ 556 ADCU_NOP_ALCA_Status "NOP_ALCA_Status";
CM_ SG_ 556 ADCU_ALC_Mode_feed "ALCA feedback status";
CM_ SG_ 556 ADCU_ALC_txtpopup "ALC Text Popups Based on system states- functional cases";
CM_ SG_ 556 ADCU_AESA_popup "AESA Popup";
CM_ SG_ 556 ADCU_ALC_Mode_Gaze_Feed "ALC subsetting activation via gaze to mirror";
CM_ SG_ 556 ADCU_ALC_Mode_Recommend_Feed "ALC subsetting activation system recommendation";
CM_ SG_ 556 ADCU_ALC_ICON_Feed "ICON Feedback Request for ALC function";
CM_ SG_ 556 ADCU_FCAM_NOP_ODD_Sts "NOP Operation Domain status";
CM_ SG_ 556 ADCU_FCAM_ALCA_TurnIndicatorReq "ALCA Turn Indicator Request";
CM_ SG_ 577 CRC_ADCU_PA_STATUS "Checksum";
CM_ SG_ 577 ALIVE_ADCU_PA_STATUS "Alive countre";
CM_ SG_ 577 ADCU_PA_AutoOn_Feed "This signal indicates the status of Auto Front Parking Assist setting in the Parking ECU";
CM_ SG_ 577 ADCU_FPA_State "State of Front Parking Assist function";
CM_ SG_ 577 ADCU_RPA_State "State of Rear Parking Assist function";
CM_ SG_ 577 ADCU_SPA_State "State of Near Side Parking Assist function";
CM_ SG_ 577 ADCU_RPA_Available "Indicates if Rear Parking Asist function is eqiupped/available or not";
CM_ SG_ 577 ADCU_NSPA_Available "Indicates if Near Side Parking Asist function is eqiupped/available or not";
CM_ SG_ 577 ADCU_FPA_Available "Indicates if Rear  Parking Asist function is eqiupped/available or not";
CM_ SG_ 577 ADCU_FPA_Check "Indicate the heath of Front parking assist function";
CM_ SG_ 577 ADCU_RPA_Check "Indicate the heath of Rear parking assist function";
CM_ SG_ 577 ADCU_NSPA_Check "Indicate the heath of Rear parking assist function";
CM_ SG_ 579 CRC_ADCU_PA_FPA "Checksum";
CM_ SG_ 579 ALIVE_ADCU_PA_FPA "Alive countre";
CM_ SG_ 579 ADCU_FPA_AlertFIL "Front Inner Left Parking Sensors Warnning Display";
CM_ SG_ 579 ADCU_FPA_AlertFOL "Front Outer Left Parking Sensors Warnning Display";
CM_ SG_ 579 ADCU_FPA_AlertFIR "Front Inner Right Parking Sensors Warnning Display";
CM_ SG_ 579 ADCU_FPA_AlertFOR "Front  Outer Right Parking Sensors Warnning Display";
CM_ SG_ 579 ADCU_FPA_AlertFSL "Front Side Left Parking Sensors Warnning Display";
CM_ SG_ 579 ADCU_FPA_AlertFSR "Front Sider Right Parking Sensors Warnning Display";
CM_ SG_ 579 ADCU_FPA_DistFIL "Distance to object";
CM_ SG_ 579 ADCU_FPA_DistFOL "Distance to object";
CM_ SG_ 579 ADCU_FPA_DistFIR "Distance to object";
CM_ SG_ 579 ADCU_FPA_DistFOR "Distance to object";
CM_ SG_ 579 ADCU_FPA_DistFSL "Distance to object";
CM_ SG_ 579 ADCU_FPA_DistFSR "Distance to object";
CM_ SG_ 579 ADCU_FPA_ChimeReqFIL "Request chime for FIL";
CM_ SG_ 579 ADCU_FPA_ChimeReqFOL "Request chime for FOL";
CM_ SG_ 579 ADCU_FPA_ChimeReqFIR "Request chime for FIR";
CM_ SG_ 579 ADCU_FPA_ChimeReqFOR "Request chime for FOR";
CM_ SG_ 579 ADCU_FPA_ChimeReqFSL "Request chime for FSL";
CM_ SG_ 579 ADCU_FPA_ChimeReqFSR "Request chime for FSR";
CM_ SG_ 580 CRC_ADCU_PA_RPA "Checksum";
CM_ SG_ 580 ALIVE_ADCU_PA_RPA "Alive countre";
CM_ SG_ 580 ADCU_RPA_AlertRIL "Rear Inner Left Parking Sensors Warnning Display";
CM_ SG_ 580 ADCU_RPA_AlertROL "Rear Outer Left Parking Sensors Warnning Display";
CM_ SG_ 580 ADCU_RPA_AlertRIR "Rear Inner Right Parking Sensors Warnning Display";
CM_ SG_ 580 ADCU_RPA_AlertROR "Rear  Outer Right Parking Sensors Warnning Display";
CM_ SG_ 580 ADCU_RPA_AlertRSL "Rear Side Left Parking Sensors Warnning Display";
CM_ SG_ 580 ADCU_RPA_AlertRSR "Rear Sider Right Parking Sensors Warnning Display";
CM_ SG_ 580 ADCU_RPA_DistRIL "Distance to object";
CM_ SG_ 580 ADCU_RPA_DistROL "Distance to object";
CM_ SG_ 580 ADCU_RPA_DistRIR "Distance to object";
CM_ SG_ 580 ADCU_RPA_DistROR "Distance to object";
CM_ SG_ 580 ADCU_RPA_DistRSL "Distance to object";
CM_ SG_ 580 ADCU_RPA_DistRSR "Distance to object";
CM_ SG_ 580 ADCU_RPA_ChimeReqRIL "Request chime for FIL";
CM_ SG_ 580 ADCU_RPA_ChimeReqROL "Request chime for FOL";
CM_ SG_ 580 ADCU_RPA_ChimeReqRIR "Request chime for FIR";
CM_ SG_ 580 ADCU_RPA_ChimeReqROR "Request chime for FOR";
CM_ SG_ 580 ADCU_RPA_ChimeReqRSL "Request chime for FSL";
CM_ SG_ 580 ADCU_RPA_ChimeReqRSR "Request chime for FSR";
CM_ SG_ 582 CRC_ADCU_PA_NSPA "Checksum";
CM_ SG_ 582 ALIVE_ADCU_PA_NSPA "Alive countre";
CM_ SG_ 582 ADCU_NSPA_AlertFSL1 "Front Side Left zone1 Parking Sensors Warnning Display";
CM_ SG_ 582 ADCU_NSPA_AlertFSL2 "Front-Side Left zone 2 Parking Sensors Warnning Display";
CM_ SG_ 582 ADCU_NSPA_AlertFSR1 "Front-Side-Right zone1 Parking Sensors Warnning Display";
CM_ SG_ 582 ADCU_NSPA_AlertFSR2 "Front-Side-Right zone 2 Parking Sensors Warnning Display";
CM_ SG_ 582 ADCU_NSPA_AlertRSL1 "Rear-Side-Left zone1 Parking Sensors Warnning Display";
CM_ SG_ 582 ADCU_NSPA_AlertRSL2 "Rear-Side-Left zone 2 Parking Sensors Warnning Display";
CM_ SG_ 582 ADCU_NSPA_AlertRSR1 "Rear-Side -Right zone1 Parking Sensors Warnning Display";
CM_ SG_ 582 ADCU_NSPA_AlertRSR2 "Rear-Side-Right zone 2 Parking Sensors Warnning Display";
CM_ SG_ 582 ADCU_NSPA_DistFSL1 "Distance to object";
CM_ SG_ 582 ADCU_NSPA_DistFSL2 "Distance to object";
CM_ SG_ 582 ADCU_NSPA_DistFSR1 "Distance to object";
CM_ SG_ 582 ADCU_NSPA_DistFSR2 "Distance to object";
CM_ SG_ 582 ADCU_NSPA_DistRSL1 "Distance to object";
CM_ SG_ 582 ADCU_NSPA_DistRSL2 "Distance to object";
CM_ SG_ 582 ADCU_NSPA_DistRSR1 "Distance to object";
CM_ SG_ 582 ADCU_NSPA_DistRSR2 "Distance to object";
CM_ SG_ 582 ADCU_NSPA_ChimeReqFSL1 "Request chime";
CM_ SG_ 582 ADCU_NSPA_ChimeReqFSL2 "Request chime";
CM_ SG_ 582 ADCU_NSPA_ChimeReqFSR1 "Request chime";
CM_ SG_ 582 ADCU_NSPA_ChimeReqFSR2 "Request chime";
CM_ SG_ 582 ADCU_NSPA_ChimeReqRSL1 "Request chime";
CM_ SG_ 582 ADCU_NSPA_ChimeReqRSL2 "Request chime";
CM_ SG_ 582 ADCU_NSPA_ChimeReqRSR1 "Request chime";
CM_ SG_ 582 ADCU_NSPA_ChimeReqRSR2 "Request chime";
CM_ SG_ 583 CRC_ADCU_BRAKE_HMI "Checksum";
CM_ SG_ 583 ALIVE_ADCU_BRAKE_HMI "Alive Counter";
CM_ SG_ 583 ADCU_RAEB_State "ADAS  Rear AEB State";
CM_ SG_ 583 ADCU_RAEB_Check "RAEB function heath check";
CM_ SG_ 583 ADCU_RAEB_Mode_Feed "Rear Automatic Emergency Brake Mode select.";
CM_ SG_ 583 ADCU_RAEB_Warning "Rear Automatic Emergency Brake warning.";
CM_ SG_ 583 ADCU_RAEB_BrakeReq_Source "Function request to trigger Brake request to FAEB ( Front ACPE, FCTB, FAEB)";
CM_ SG_ 605 ADCU_Driving_Parking_state "Driving or Parking status";
CM_ SG_ 664 CRC_ADCU_ADASFeat_InputState "Checksum";
CM_ SG_ 664 ALIVE_ADCU_ADASFeat_InputState "Alive Counter";
CM_ SG_ 664 ADCU_ACC_Input_State "indicate perception failure in ADCU for AACC on FCAM";
CM_ SG_ 664 ADCU_TSR_Input_State "indicate Navi map failure in ADCU for TSR on FCAM";
CM_ SG_ 664 ADCU_ESA_Input_State "indicate perception failure in ADCU for ESA on FCAM";
CM_ SG_ 563 CRC_ADCU_MHU_Sentry_Mode "Checksum";
CM_ SG_ 563 ALIVE_ADCU_MHU_Sentry_Mode "Alive Counter";
CM_ SG_ 563 ADAS_Sentry_Mode_Stat "Sentry mode setting status";
CM_ SG_ 705 CRC_ADCU_MHU_DNSRequest "Checksum";
CM_ SG_ 705 ALIVE_ADCU_MHU_DNSRequest "Alive Counter";
CM_ SG_ 705 ADCU_MHU_DNS_Warning "Departure Notification issued or not.";
CM_ SG_ 586 CRC_ADCU_ACPE_CMD "Checksum";
CM_ SG_ 586 ALIVE_ADCU_ACPE_CMD "Alive Counter";
CM_ SG_ 586 ADCU_ACPE_PowerCommand "ACPE Power control intervence command";
CM_ SG_ 586 ADCU_ACPE_BrakeCommand "ACPE Brake flag intervence to FAEB/Rear AEB ECU";
CM_ SG_ 586 ADCU_ACPE_Available "ACPE function avaibility in ADCU";
CM_ SG_ 586 ADCU_ACPE_FuncActive "ACPE function active state";
CM_ SG_ 586 ADCU_ACPE_HMICommand "ACPE HMI command request to display HMI alert to driver";
CM_ SG_ 586 ADCU_ACPE_State "ACPE State";
CM_ SG_ 586 ADCU_ACPE_Setting_Feed "ACPE Setting feedback from Vehicle ACPE setting request";
CM_ SG_ 586 ADCU_ACPE_Sens_Feed "ACPE Setting Sensitivsity feedback from Vehicle ACPE sensitivsity setting request";
CM_ SG_ 586 ADCU_ACPE_Check "ACPE function heath status";
CM_ SG_ 586 ADCU_ACPE_TargetDeccel "Target Deccel for the ACPE demand";
CM_ SG_ 586 ACPE_FrontControler_Operate "Front ACPE Active status";
CM_ SG_ 586 ACPE_RearControler_Operate "Rear  ACPE Active status";
CM_ SG_ 588 CRC_ADCU_SVM_STATUS "Checksum";
CM_ SG_ 588 ALIVE_ADCU_SVM_STATUS "Alive counter";
CM_ SG_ 588 ADCU_SVM_Guideline_Feed "SVM Dynamic guidline Setting feedback";
CM_ SG_ 588 ADCU_SVM_ObjOverlay_Feed "SVM 3D Obstacle overlay Setting feedback";
CM_ SG_ 588 ADCU_SVM_TrailerGuideline_Feed "SVM Trailer Guidline Setting Feedback";
CM_ SG_ 588 ADCU_SVM_MaxDoorOverlay_Feed "SVM Maximum Door openning overlay Setting feedback";
CM_ SG_ 588 ADCU_SVM_Transparency_Feed "SVM Car transparent Setting Feedback";
CM_ SG_ 588 ADCU_SVM_BlindSpotView_Feed "SVM Auto Blindspot camera  Setting Feedback";
CM_ SG_ 588 ADCU_SVM_BlindspotView "SVM Blindspot View Status/ Request";
CM_ SG_ 588 ADCU_SVM_ShowAVMReq "Request MHU Show SVM/RVC";
CM_ SG_ 588 ADCU_SVM_View_Status "SVM Current View Status/ Request";
CM_ SG_ 588 ADCU_SVM_Status_Signal "SVM Showing stattus/request from ADCU";
CM_ SG_ 588 ADCU_Early_RVC_Status_Signal "Early RVC current status";
CM_ SG_ 602 CRC_ADCU_SYS_HEALTH "Checksum";
CM_ SG_ 602 ALIVE_ADCU_SYS_HEALTH "Alive counter";
CM_ SG_ 602 ADCU_SVM_FrontCam_Check "Front SVM camera Heath";
CM_ SG_ 602 ADCU_SVM_RearCam_Check "Rear SVM camera Heath";
CM_ SG_ 602 ADCU_SVM_LeftCamera_Check "Left SVM camera Heath";
CM_ SG_ 602 ADCU_SVM_RightCamera_Check "Right SVM camera Heath";
CM_ SG_ 602 ADCU_TopRearCamera_Check "Top Rear camera Heath";
CM_ SG_ 602 ADCU_USS_FIL_Check "Front Inner Left USS Heath";
CM_ SG_ 602 ADCU_USS_FIR_Check "Front Inner Right USS Heath";
CM_ SG_ 602 ADCU_USS_FOL_Check "Front Outer Left USS Heath";
CM_ SG_ 602 ADCU_USS_FOR_Check "Front Outer Right USS Heath";
CM_ SG_ 602 ADCU_USS_FSL_Check "Front Side Left USS Heath";
CM_ SG_ 602 ADCU_USS_FSR_Check "Front Side Right USS Heath";
CM_ SG_ 602 ADCU_USS_RIL_Check "Rear Inner Left USS Heath";
CM_ SG_ 602 ADCU_USS_RIR_Check "Rear Inner Right USS Heath";
CM_ SG_ 602 ADCU_USS_ROL_Check "Rear Outer Left USS Heath";
CM_ SG_ 602 ADCU_USS_ROR_Check "Rear Outer Right USS Heath";
CM_ SG_ 602 ADCU_USS_RSL_Check "Rear Side Left USS Heath";
CM_ SG_ 602 ADCU_USS_RSR_Check "Rear Side Right USS Heath";
CM_ SG_ 602 ADCU_SVM_GMSL_Check "MHU ADCU GMSL Link Heath";
CM_ SG_ 602 ADCU_OS_Check "ADCU OS heath";
CM_ SG_ 602 ADCU_ERROR_CODE "ADCU ERROR Code";
CM_ SG_ 602 ADCU_ErrFCAM_SnSr_Diag "ADCU Sensor Error status";
CM_ SG_ 602 ADCU_ErrFCAM_Feature_Diag "ADCU Feature Error Status";
CM_ SG_ 647 CRC_ADCU_MHU_VAP_Status "Checksum";
CM_ SG_ 647 ALIVE_ADCU_MHU_VAP_Status "Alive counter";
CM_ SG_ 648 CRC_ADCU_MHU_VAP_ControlResp "Checksum";
CM_ SG_ 648 ALIVE_ADCU_MHU_VAP_ControlResp "Alive counter";
CM_ SG_ 650 CRC_ADCU_TBOX_VAP_Status "Checksum";
CM_ SG_ 650 ALIVE_ADCU_TBOX_VAP_Status "Alive counter";
CM_ SG_ 652 CRC_ADCU_MHU_VPARK "Checksum";
CM_ SG_ 652 ALIVE_ADCU_MHU_VPARK "Alive counter";
CM_ SG_ 913 CRC_ADCU_TO_SRR_Front "Checksum";
CM_ SG_ 913 ALIVE_ADCU_TO_SRR_Front "Alive Counter";
CM_ SG_ 913 ADCU_TO_SRR_Front_DEFAULT "Send Default value to classification for classification of Radar";
CM_ SG_ 914 CRC_ADCU_TO_SRR_Rear "Checksum";
CM_ SG_ 914 ALIVE_AADCU_TO_SRR_Rear "Alive Counter";
CM_ SG_ 914 ADCU_TO_SRR_Rear_DEFAULT "Send Default value to classification for classification of Radar";
CM_ SG_ 1041 CRC_ADCU_DCM "Checksum";
CM_ SG_ 1041 ALIVE_ADCU_DCM "Alive Counter";
CM_ SG_ 1041 ADCU_DCM_Status "Indicate if there is any fault related to DCM from ADCU";
BA_DEF_ BO_  "DiagRequest" ENUM  "No","Yes";
BA_DEF_ BO_  "DiagResponse" ENUM  "No","Yes";
BA_DEF_ BO_  "DiagState" ENUM  "No","Yes";
BA_DEF_ BO_  "GenMsgCycleTime" INT 0 65535;
BA_DEF_ BO_  "GenMsgCycleTimeFast" INT 0 65535;
BA_DEF_ BO_  "GenMsgDelayTime" INT 0 65535;
BA_DEF_ BO_  "GenMsgILSupport" ENUM  "No","Yes";
BA_DEF_ BO_  "GenMsgNrOfRepetition" INT 0 65535;
BA_DEF_ BO_  "GenMsgSendType" ENUM  "Cyclic","NoMsgSendType","NotUsed","NotUsed","NotUsed","NotUsed","NotUsed","IfActive","NoMsgSendType","NotUsed";
BA_DEF_ BO_  "NmAsrMessage" ENUM  "No","Yes";
BA_DEF_ BO_  "NmMessage" ENUM  "No","Yes";
BA_DEF_ SG_  "GenSigSendType" ENUM  "Cyclic","NoSigSendType","OnWriteWithRepetition","OnChange","OnChangeWithRepetition","IfActive","IfActiveWithRepetition","OnWrite","NotUsed","NotUsed","NotUsed","NotUsed","NotUsed";
BA_DEF_ SG_  "GenSigStartValue" INT 0 2147483647;
BA_DEF_ SG_  "GenSigTimeoutTime_ALL" INT 0 65535;
BA_DEF_ SG_  "InvalidValue" STRING ;
BA_DEF_ SG_  "GenSigInactiveValue" INT 0 2147483647;
BA_DEF_ BO_  "VFrameFormat" ENUM  "StandardCAN","ExtendedCAN","reserved","J1939PG","reserved","reserved","reserved","reserved","reserved","reserved","reserved","reserved","reserved","reserved","StandardCAN_FD","ExtendedCAN_FD";
BA_DEF_ BO_  "CANFD_BRS" ENUM  "0","1";
BA_DEF_ SG_  "SystemSignalLongSymbol" STRING ;
BA_DEF_ BO_  "SystemMessageLongSymbol" STRING ;
BA_DEF_DEF_  "DiagRequest" "No";
BA_DEF_DEF_  "DiagResponse" "No";
BA_DEF_DEF_  "DiagState" "No";
BA_DEF_DEF_  "GenMsgCycleTime" 0;
BA_DEF_DEF_  "GenMsgCycleTimeFast" 0;
BA_DEF_DEF_  "GenMsgDelayTime" 0;
BA_DEF_DEF_  "GenMsgILSupport" "Yes";
BA_DEF_DEF_  "GenMsgNrOfRepetition" 0;
BA_DEF_DEF_  "GenMsgSendType" "Cyclic";
BA_DEF_DEF_  "NmAsrMessage" "No";
BA_DEF_DEF_  "NmMessage" "No";
BA_DEF_DEF_  "GenSigSendType" "Cyclic";
BA_DEF_DEF_  "GenSigStartValue" 0;
BA_DEF_DEF_  "GenSigTimeoutTime_ALL" 0;
BA_DEF_DEF_  "InvalidValue" "";
BA_DEF_DEF_  "GenSigInactiveValue" 0;
BA_DEF_DEF_  "VFrameFormat" "StandardCAN_FD";
BA_DEF_DEF_  "CANFD_BRS" "1";
BA_DEF_DEF_  "SystemSignalLongSymbol" "";
BA_DEF_DEF_  "SystemMessageLongSymbol" "";
BA_ "GenMsgCycleTime" BO_ 1866 50;
BA_ "GenMsgCycleTime" BO_ 656 50;
BA_ "SystemMessageLongSymbol" BO_ 656 "FCAM_ADCU_NOPHWAPlus_ClusterFaultInfo";
BA_ "GenMsgCycleTimeFast" BO_ 1970 50;
BA_ "GenMsgNrOfRepetition" BO_ 1970 2;
BA_ "GenMsgSendType" BO_ 1970 1;
BA_ "GenMsgCycleTime" BO_ 468 100;
BA_ "GenMsgCycleTime" BO_ 634 50;
BA_ "GenMsgNrOfRepetition" BO_ 634 3;
BA_ "GenMsgCycleTime" BO_ 635 50;
BA_ "GenMsgNrOfRepetition" BO_ 635 3;
BA_ "SystemMessageLongSymbol" BO_ 635 "SRR_RL_TimeSynchronization_Status";
BA_ "GenMsgCycleTime" BO_ 831 50;
BA_ "GenMsgCycleTime" BO_ 307 50;
BA_ "GenMsgCycleTimeFast" BO_ 307 15;
BA_ "GenMsgNrOfRepetition" BO_ 307 3;
BA_ "GenMsgCycleTime" BO_ 826 50;
BA_ "GenMsgCycleTime" BO_ 636 50;
BA_ "GenMsgNrOfRepetition" BO_ 636 3;
BA_ "SystemMessageLongSymbol" BO_ 636 "SRR_RR_TimeSynchronization_Status";
BA_ "GenMsgCycleTime" BO_ 827 100;
BA_ "GenMsgNrOfRepetition" BO_ 827 2;
BA_ "GenMsgCycleTime" BO_ 830 50;
BA_ "GenMsgCycleTime" BO_ 637 50;
BA_ "GenMsgNrOfRepetition" BO_ 637 3;
BA_ "SystemMessageLongSymbol" BO_ 637 "SRR_FL_TimeSynchronization_Status";
BA_ "GenMsgCycleTime" BO_ 638 50;
BA_ "GenMsgNrOfRepetition" BO_ 638 3;
BA_ "SystemMessageLongSymbol" BO_ 638 "SRR_FR_TimeSynchronization_Status";
BA_ "GenMsgCycleTime" BO_ 315 20;
BA_ "GenMsgCycleTime" BO_ 828 50;
BA_ "GenMsgCycleTime" BO_ 639 50;
BA_ "GenMsgNrOfRepetition" BO_ 639 3;
BA_ "GenMsgCycleTime" BO_ 543 20;
BA_ "GenMsgCycleTime" BO_ 551 50;
BA_ "GenMsgCycleTime" BO_ 552 50;
BA_ "GenMsgCycleTime" BO_ 556 50;
BA_ "GenMsgCycleTime" BO_ 577 200;
BA_ "GenMsgCycleTime" BO_ 579 100;
BA_ "GenMsgCycleTimeFast" BO_ 579 30;
BA_ "GenMsgNrOfRepetition" BO_ 579 1;
BA_ "GenMsgCycleTime" BO_ 580 100;
BA_ "GenMsgCycleTimeFast" BO_ 580 30;
BA_ "GenMsgNrOfRepetition" BO_ 580 1;
BA_ "GenMsgCycleTime" BO_ 582 100;
BA_ "GenMsgCycleTimeFast" BO_ 582 30;
BA_ "GenMsgNrOfRepetition" BO_ 582 1;
BA_ "GenMsgCycleTime" BO_ 583 200;
BA_ "GenMsgCycleTimeFast" BO_ 583 30;
BA_ "GenMsgNrOfRepetition" BO_ 583 2;
BA_ "GenMsgCycleTime" BO_ 605 50;
BA_ "GenMsgCycleTime" BO_ 664 50;
BA_ "GenMsgCycleTime" BO_ 563 50;
BA_ "GenMsgCycleTime" BO_ 705 100;
BA_ "GenMsgCycleTime" BO_ 586 200;
BA_ "GenMsgCycleTimeFast" BO_ 586 30;
BA_ "GenMsgNrOfRepetition" BO_ 586 2;
BA_ "GenMsgCycleTime" BO_ 588 500;
BA_ "GenMsgCycleTime" BO_ 602 500;
BA_ "GenMsgCycleTime" BO_ 549 50;
BA_ "GenMsgCycleTime" BO_ 647 50;
BA_ "GenMsgCycleTime" BO_ 648 20;
BA_ "GenMsgCycleTime" BO_ 650 50;
BA_ "GenMsgCycleTime" BO_ 652 50;
BA_ "GenMsgCycleTime" BO_ 913 100;
BA_ "GenMsgCycleTime" BO_ 914 100;
BA_ "GenMsgCycleTime" BO_ 1041 20;
BA_ "GenSigTimeoutTime_ALL" SG_ 1866 CRC_FCAM_Arbitration_Result 250;
BA_ "InvalidValue" SG_ 1866 ALIVE_FCAM_Arbitration_Result "Fh";
BA_ "GenSigTimeoutTime_ALL" SG_ 1866 ALIVE_FCAM_Arbitration_Result 250;
BA_ "InvalidValue" SG_ 1866 FCAM_Arbitration_Log_Result "Fh";
BA_ "GenSigTimeoutTime_ALL" SG_ 1866 FCAM_Arbitration_Log_Result 250;
BA_ "InvalidValue" SG_ 1866 FCAM_Arbitration_Lat_Result "Fh";
BA_ "GenSigTimeoutTime_ALL" SG_ 1866 FCAM_Arbitration_Lat_Result 250;
BA_ "InvalidValue" SG_ 1866 FCAM_Arbi_Fb "0h";
BA_ "GenSigTimeoutTime_ALL" SG_ 1866 FCAM_Arbi_Fb 100;
BA_ "InvalidValue" SG_ 1866 FCAM_Acore_Diag "0h";
BA_ "GenSigTimeoutTime_ALL" SG_ 1866 FCAM_Acore_Diag 100;
BA_ "InvalidValue" SG_ 1866 FCAM_Rcore_Diag "0h";
BA_ "GenSigTimeoutTime_ALL" SG_ 1866 FCAM_Rcore_Diag 100;
BA_ "InvalidValue" SG_ 1866 FCAM_Feature_Diag "0h";
BA_ "GenSigTimeoutTime_ALL" SG_ 1866 FCAM_Feature_Diag 100;
BA_ "InvalidValue" SG_ 1866 FCAM_ErrFCAM_SnSr_Diag "0h";
BA_ "GenSigTimeoutTime_ALL" SG_ 1866 FCAM_ErrFCAM_SnSr_Diag 100;
BA_ "InvalidValue" SG_ 1866 FCAM_ErrFCAM_Feature_Diag "0h";
BA_ "GenSigTimeoutTime_ALL" SG_ 1866 FCAM_ErrFCAM_Feature_Diag 100;
BA_ "InvalidValue" SG_ 1866 FCAM_AACC_Arbitrator_Result "0h";
BA_ "GenSigTimeoutTime_ALL" SG_ 1866 FCAM_AACC_Arbitrator_Result 250;
BA_ "InvalidValue" SG_ 1866 FCAM_AEB_Arbitrator_Result "0h";
BA_ "GenSigTimeoutTime_ALL" SG_ 1866 FCAM_AEB_Arbitrator_Result 250;
BA_ "InvalidValue" SG_ 1866 FCAM_FCTB_Arbitrator_Result "0h";
BA_ "GenSigTimeoutTime_ALL" SG_ 1866 FCAM_FCTB_Arbitrator_Result 250;
BA_ "InvalidValue" SG_ 1866 FCAM_ACPE_Arbitrator_Result "0h";
BA_ "GenSigTimeoutTime_ALL" SG_ 1866 FCAM_ACPE_Arbitrator_Result 250;
BA_ "InvalidValue" SG_ 1866 FCAM_LCC_Arbitrator_Result "0h";
BA_ "GenSigTimeoutTime_ALL" SG_ 1866 FCAM_LCC_Arbitrator_Result 250;
BA_ "InvalidValue" SG_ 1866 FCAM_NOP_Arbitrator_Result "0h";
BA_ "GenSigTimeoutTime_ALL" SG_ 1866 FCAM_NOP_Arbitrator_Result 250;
BA_ "InvalidValue" SG_ 1866 FCAM_HWAPlus_Arbitrator_Result "0h";
BA_ "GenSigTimeoutTime_ALL" SG_ 1866 FCAM_HWAPlus_Arbitrator_Result 250;
BA_ "InvalidValue" SG_ 1866 FCAM_LKA_Arbitrator_Result "0h";
BA_ "GenSigTimeoutTime_ALL" SG_ 1866 FCAM_LKA_Arbitrator_Result 250;
BA_ "InvalidValue" SG_ 1866 FCAM_ELKA_Arbitrator_Result "0h";
BA_ "GenSigTimeoutTime_ALL" SG_ 1866 FCAM_ELKA_Arbitrator_Result 250;
BA_ "InvalidValue" SG_ 1866 FCAM_ESA_Arbitrator_Result "0h";
BA_ "GenSigTimeoutTime_ALL" SG_ 1866 FCAM_ESA_Arbitrator_Result 250;
BA_ "InvalidValue" SG_ 1866 FCAM_Arbitrator_Reserve_1 "0h";
BA_ "GenSigTimeoutTime_ALL" SG_ 1866 FCAM_Arbitrator_Reserve_1 250;
BA_ "InvalidValue" SG_ 1866 FCAM_Arbitrator_Reserve_2 "0h";
BA_ "GenSigTimeoutTime_ALL" SG_ 1866 FCAM_Arbitrator_Reserve_2 250;
BA_ "GenSigTimeoutTime_ALL" SG_ 656 CRC_FCAMPerception_Link_State 250;
BA_ "InvalidValue" SG_ 656 ALIVE_FCAMPerception_Link_State "Fh";
BA_ "GenSigTimeoutTime_ALL" SG_ 656 ALIVE_FCAMPerception_Link_State 250;
BA_ "InvalidValue" SG_ 656 FCAM_ADCU_NOPHWAPlus_ClusterFaul "3h";
BA_ "GenSigTimeoutTime_ALL" SG_ 656 FCAM_ADCU_NOPHWAPlus_ClusterFaul 250;
BA_ "SystemSignalLongSymbol" SG_ 656 FCAM_ADCU_NOPHWAPlus_ClusterFaul "FCAM_ADCU_NOPHWAPlus_ClusterFault";
BA_ "GenSigSendType" SG_ 1970 FCAM_I_Req_RandomData 2;
BA_ "GenSigSendType" SG_ 1970 FCAM_I_Req_MAC 2;
BA_ "GenSigTimeoutTime_ALL" SG_ 468 CRC_MRR_Radar_Status 5000;
BA_ "InvalidValue" SG_ 468 ALIVE_MRR_Radar_Status "Fh";
BA_ "GenSigTimeoutTime_ALL" SG_ 468 ALIVE_MRR_Radar_Status 5000;
BA_ "GenSigTimeoutTime_ALL" SG_ 468 MRR_check 5000;
BA_ "GenSigTimeoutTime_ALL" SG_ 468 MRR_Radar_Cal_Status 5000;
BA_ "GenSigTimeoutTime_ALL" SG_ 468 MRR_Radar_Block_Status 5000;
BA_ "GenSigTimeoutTime_ALL" SG_ 468 MRR_Radar_StaticCal_Status 5000;
BA_ "GenSigTimeoutTime_ALL" SG_ 468 MRR_CalSensorProgress 5000;
BA_ "GenSigTimeoutTime_ALL" SG_ 468 MRR_Cal_InstallDeviation 5000;
BA_ "GenSigTimeoutTime_ALL" SG_ 634 CRC_MRR_TimeSynchronization_Stat 250;
BA_ "SystemSignalLongSymbol" SG_ 634 CRC_MRR_TimeSynchronization_Stat "CRC_MRR_TimeSynchronization_Status";
BA_ "InvalidValue" SG_ 634 ALIVE_MRR_TimeSynchronization_St "Fh";
BA_ "GenSigTimeoutTime_ALL" SG_ 634 ALIVE_MRR_TimeSynchronization_St 250;
BA_ "SystemSignalLongSymbol" SG_ 634 ALIVE_MRR_TimeSynchronization_St "ALIVE_MRR_TimeSynchronization_Status";
BA_ "InvalidValue" SG_ 634 MRR_TimeSynchronization_Status "3h";
BA_ "GenSigTimeoutTime_ALL" SG_ 634 MRR_TimeSynchronization_Status 250;
BA_ "GenSigTimeoutTime_ALL" SG_ 635 CRC_SRR_RL_TimeSynchronization_S 250;
BA_ "SystemSignalLongSymbol" SG_ 635 CRC_SRR_RL_TimeSynchronization_S "CRC_SRR_RL_TimeSynchronization_Status";
BA_ "InvalidValue" SG_ 635 ALIVE_SRR_RL_TimeSynchronization "Fh";
BA_ "GenSigTimeoutTime_ALL" SG_ 635 ALIVE_SRR_RL_TimeSynchronization 250;
BA_ "SystemSignalLongSymbol" SG_ 635 ALIVE_SRR_RL_TimeSynchronization "ALIVE_SRR_RL_TimeSynchronization_Status";
BA_ "InvalidValue" SG_ 635 SRR_RL_TimeSynchronization_Statu "3h";
BA_ "GenSigTimeoutTime_ALL" SG_ 635 SRR_RL_TimeSynchronization_Statu 250;
BA_ "SystemSignalLongSymbol" SG_ 635 SRR_RL_TimeSynchronization_Statu "SRR_RL_TimeSynchronization_Status";
BA_ "GenSigTimeoutTime_ALL" SG_ 831 CRC_SRR_RL_ObjList 250;
BA_ "InvalidValue" SG_ 831 ALIVE_SRR_RL_ObjList "Fh";
BA_ "GenSigTimeoutTime_ALL" SG_ 831 ALIVE_SRR_RL_ObjList 250;
BA_ "GenSigTimeoutTime_ALL" SG_ 831 RL_Devtimestamp 250;
BA_ "GenSigStartValue" SG_ 831 RL_Obj1_ID 255;
BA_ "GenSigTimeoutTime_ALL" SG_ 831 RL_Obj1_ID 250;
BA_ "GenSigTimeoutTime_ALL" SG_ 831 RL_Obj1_DistLong 250;
BA_ "GenSigTimeoutTime_ALL" SG_ 831 RL_Obj1_DislLat 250;
BA_ "GenSigTimeoutTime_ALL" SG_ 831 RL_Obj1_VrelLong 250;
BA_ "GenSigStartValue" SG_ 831 RL_Ob1j_DynProp 4;
BA_ "GenSigTimeoutTime_ALL" SG_ 831 RL_Ob1j_DynProp 250;
BA_ "GenSigTimeoutTime_ALL" SG_ 831 RL_Obj1_VrelLat 250;
BA_ "GenSigTimeoutTime_ALL" SG_ 831 RL_Obj1_RCS 250;
BA_ "InvalidValue" SG_ 831 RL_Obj1_MeasState "7h";
BA_ "GenSigStartValue" SG_ 831 RL_Obj1_MeasState 7;
BA_ "GenSigTimeoutTime_ALL" SG_ 831 RL_Obj1_MeasState 250;
BA_ "GenSigTimeoutTime_ALL" SG_ 831 RL_Obj1_ProbOfExist 250;
BA_ "GenSigTimeoutTime_ALL" SG_ 831 RL_Obj1_ArelLong 250;
BA_ "InvalidValue" SG_ 831 RL_Obj1j_Class "7h";
BA_ "GenSigStartValue" SG_ 831 RL_Obj1j_Class 7;
BA_ "GenSigTimeoutTime_ALL" SG_ 831 RL_Obj1j_Class 250;
BA_ "InvalidValue" SG_ 831 RL_Obj1_ArelLat "7h";
BA_ "GenSigTimeoutTime_ALL" SG_ 831 RL_Obj1_ArelLat 250;
BA_ "InvalidValue" SG_ 831 RL_Obj1_Length "7h";
BA_ "GenSigTimeoutTime_ALL" SG_ 831 RL_Obj1_Length 250;
BA_ "InvalidValue" SG_ 831 RL_Obj1_Width "7h";
BA_ "GenSigTimeoutTime_ALL" SG_ 831 RL_Obj1_Width 250;
BA_ "GenSigStartValue" SG_ 831 RL_Obj2_ID 255;
BA_ "GenSigTimeoutTime_ALL" SG_ 831 RL_Obj2_ID 250;
BA_ "GenSigTimeoutTime_ALL" SG_ 831 RL_Obj2_DistLong 250;
BA_ "GenSigTimeoutTime_ALL" SG_ 831 RL_Obj2_DislLat 250;
BA_ "GenSigTimeoutTime_ALL" SG_ 831 RL_Obj2_VrelLong 250;
BA_ "GenSigStartValue" SG_ 831 RL_Obj2_DynProp 4;
BA_ "GenSigTimeoutTime_ALL" SG_ 831 RL_Obj2_DynProp 250;
BA_ "GenSigTimeoutTime_ALL" SG_ 831 RL_Obj2_VrelLat 250;
BA_ "GenSigTimeoutTime_ALL" SG_ 831 RL_Obj2_RCS 250;
BA_ "InvalidValue" SG_ 831 RL_Obj2_MeasState "7h";
BA_ "GenSigStartValue" SG_ 831 RL_Obj2_MeasState 7;
BA_ "GenSigTimeoutTime_ALL" SG_ 831 RL_Obj2_MeasState 250;
BA_ "GenSigTimeoutTime_ALL" SG_ 831 RL_Obj2_ProbOfExist 250;
BA_ "GenSigTimeoutTime_ALL" SG_ 831 RL_Obj2_ArelLong 250;
BA_ "InvalidValue" SG_ 831 RL_Obj2j_Class "7h";
BA_ "GenSigStartValue" SG_ 831 RL_Obj2j_Class 7;
BA_ "GenSigTimeoutTime_ALL" SG_ 831 RL_Obj2j_Class 250;
BA_ "InvalidValue" SG_ 831 RL_Obj2_ArelLat "7h";
BA_ "GenSigTimeoutTime_ALL" SG_ 831 RL_Obj2_ArelLat 250;
BA_ "InvalidValue" SG_ 831 RL_Obj2_Length "7h";
BA_ "GenSigTimeoutTime_ALL" SG_ 831 RL_Obj2_Length 250;
BA_ "InvalidValue" SG_ 831 RL_Obj2_Width "7h";
BA_ "GenSigTimeoutTime_ALL" SG_ 831 RL_Obj2_Width 250;
BA_ "GenSigStartValue" SG_ 831 RL_Obj3_ID 255;
BA_ "GenSigTimeoutTime_ALL" SG_ 831 RL_Obj3_ID 250;
BA_ "GenSigTimeoutTime_ALL" SG_ 831 RL_Obj3_DistLong 250;
BA_ "GenSigTimeoutTime_ALL" SG_ 831 RL_Obj3_DislLat 250;
BA_ "GenSigTimeoutTime_ALL" SG_ 831 RL_Obj3_VrelLong 250;
BA_ "GenSigStartValue" SG_ 831 RL_Obj3_DynProp 4;
BA_ "GenSigTimeoutTime_ALL" SG_ 831 RL_Obj3_DynProp 250;
BA_ "GenSigTimeoutTime_ALL" SG_ 831 RL_Obj3_VrelLat 250;
BA_ "GenSigTimeoutTime_ALL" SG_ 831 RL_Obj3_RCS 250;
BA_ "InvalidValue" SG_ 831 RL_Obj3_MeasState "7h";
BA_ "GenSigStartValue" SG_ 831 RL_Obj3_MeasState 7;
BA_ "GenSigTimeoutTime_ALL" SG_ 831 RL_Obj3_MeasState 250;
BA_ "GenSigTimeoutTime_ALL" SG_ 831 RL_Obj3_ProbOfExist 250;
BA_ "GenSigTimeoutTime_ALL" SG_ 831 RL_Obj3_ArelLong 250;
BA_ "InvalidValue" SG_ 831 RL_Obj3j_Class "7h";
BA_ "GenSigStartValue" SG_ 831 RL_Obj3j_Class 7;
BA_ "GenSigTimeoutTime_ALL" SG_ 831 RL_Obj3j_Class 250;
BA_ "InvalidValue" SG_ 831 RL_Obj3_ArelLat "7h";
BA_ "GenSigTimeoutTime_ALL" SG_ 831 RL_Obj3_ArelLat 250;
BA_ "InvalidValue" SG_ 831 RL_Obj3_Length "7h";
BA_ "GenSigTimeoutTime_ALL" SG_ 831 RL_Obj3_Length 250;
BA_ "InvalidValue" SG_ 831 RL_Obj3_Width "7h";
BA_ "GenSigTimeoutTime_ALL" SG_ 831 RL_Obj3_Width 250;
BA_ "GenSigStartValue" SG_ 831 RL_Obj4_ID 255;
BA_ "GenSigTimeoutTime_ALL" SG_ 831 RL_Obj4_ID 250;
BA_ "GenSigTimeoutTime_ALL" SG_ 831 RL_Obj4_DistLong 250;
BA_ "GenSigTimeoutTime_ALL" SG_ 831 RL_Obj4_DislLat 250;
BA_ "GenSigTimeoutTime_ALL" SG_ 831 RL_Obj4_VrelLong 250;
BA_ "GenSigStartValue" SG_ 831 RL_Obj4_DynProp 4;
BA_ "GenSigTimeoutTime_ALL" SG_ 831 RL_Obj4_DynProp 250;
BA_ "GenSigTimeoutTime_ALL" SG_ 831 RL_Obj4_VrelLat 250;
BA_ "GenSigTimeoutTime_ALL" SG_ 831 RL_Obj4_RCS 250;
BA_ "InvalidValue" SG_ 831 RL_Obj4_MeasState "7h";
BA_ "GenSigStartValue" SG_ 831 RL_Obj4_MeasState 7;
BA_ "GenSigTimeoutTime_ALL" SG_ 831 RL_Obj4_MeasState 250;
BA_ "GenSigTimeoutTime_ALL" SG_ 831 RL_Obj4_ProbOfExist 250;
BA_ "GenSigTimeoutTime_ALL" SG_ 831 RL_Obj4_ArelLong 250;
BA_ "InvalidValue" SG_ 831 RL_Obj4j_Class "7h";
BA_ "GenSigStartValue" SG_ 831 RL_Obj4j_Class 7;
BA_ "GenSigTimeoutTime_ALL" SG_ 831 RL_Obj4j_Class 250;
BA_ "InvalidValue" SG_ 831 RL_Obj4_ArelLat "7h";
BA_ "GenSigTimeoutTime_ALL" SG_ 831 RL_Obj4_ArelLat 250;
BA_ "InvalidValue" SG_ 831 RL_Obj4_Length "7h";
BA_ "GenSigTimeoutTime_ALL" SG_ 831 RL_Obj4_Length 250;
BA_ "InvalidValue" SG_ 831 RL_Obj4_Width "7h";
BA_ "GenSigTimeoutTime_ALL" SG_ 831 RL_Obj4_Width 250;
BA_ "GenSigTimeoutTime_ALL" SG_ 307 CRC_SRR_RR_BSD_RCTA_DOW 500;
BA_ "InvalidValue" SG_ 307 ALIVE_SRR_RR_BSD_RCTA_DOW "Fh";
BA_ "GenSigTimeoutTime_ALL" SG_ 307 ALIVE_SRR_RR_BSD_RCTA_DOW 500;
BA_ "InvalidValue" SG_ 307 SRR_RR_BSD_check "3h";
BA_ "GenSigTimeoutTime_ALL" SG_ 307 SRR_RR_BSD_check 500;
BA_ "GenSigSendType" SG_ 307 SRR_RR_BSD_check 2;
BA_ "InvalidValue" SG_ 307 SRR_RR_BSD_state "7h";
BA_ "GenSigTimeoutTime_ALL" SG_ 307 SRR_RR_BSD_state 500;
BA_ "GenSigSendType" SG_ 307 SRR_RR_BSD_state 2;
BA_ "InvalidValue" SG_ 307 SRR_RR_BSD_AudChime_Feed "0h";
BA_ "GenSigTimeoutTime_ALL" SG_ 307 SRR_RR_BSD_AudChime_Feed 500;
BA_ "GenSigSendType" SG_ 307 SRR_RR_BSD_AudChime_Feed 2;
BA_ "InvalidValue" SG_ 307 SRR_RR_BSD_IndLeft "3h";
BA_ "GenSigTimeoutTime_ALL" SG_ 307 SRR_RR_BSD_IndLeft 500;
BA_ "GenSigSendType" SG_ 307 SRR_RR_BSD_IndLeft 2;
BA_ "InvalidValue" SG_ 307 SRR_RR_BSD_IndRight "3h";
BA_ "GenSigTimeoutTime_ALL" SG_ 307 SRR_RR_BSD_IndRight 500;
BA_ "GenSigSendType" SG_ 307 SRR_RR_BSD_IndRight 2;
BA_ "InvalidValue" SG_ 307 SRR_RR_BSD_SndWarn "0h";
BA_ "GenSigTimeoutTime_ALL" SG_ 307 SRR_RR_BSD_SndWarn 500;
BA_ "GenSigSendType" SG_ 307 SRR_RR_BSD_SndWarn 2;
BA_ "InvalidValue" SG_ 307 SRR_RR_BSD_Mode_Feed "0h";
BA_ "GenSigStartValue" SG_ 307 SRR_RR_BSD_Mode_Feed 1;
BA_ "GenSigTimeoutTime_ALL" SG_ 307 SRR_RR_BSD_Mode_Feed 500;
BA_ "GenSigSendType" SG_ 307 SRR_RR_BSD_Mode_Feed 2;
BA_ "InvalidValue" SG_ 307 SRR_RR_BSD_sens_Feed "3h";
BA_ "GenSigTimeoutTime_ALL" SG_ 307 SRR_RR_BSD_sens_Feed 500;
BA_ "GenSigSendType" SG_ 307 SRR_RR_BSD_sens_Feed 2;
BA_ "InvalidValue" SG_ 307 SRR_RR_RCTA_IndRight "0h";
BA_ "GenSigTimeoutTime_ALL" SG_ 307 SRR_RR_RCTA_IndRight 500;
BA_ "GenSigSendType" SG_ 307 SRR_RR_RCTA_IndRight 2;
BA_ "InvalidValue" SG_ 307 SRR_RR_RCTA_IndLeft "0h";
BA_ "GenSigTimeoutTime_ALL" SG_ 307 SRR_RR_RCTA_IndLeft 500;
BA_ "GenSigSendType" SG_ 307 SRR_RR_RCTA_IndLeft 2;
BA_ "InvalidValue" SG_ 307 SRR_RR_RCTA_sens_Feed "3h";
BA_ "GenSigTimeoutTime_ALL" SG_ 307 SRR_RR_RCTA_sens_Feed 500;
BA_ "GenSigSendType" SG_ 307 SRR_RR_RCTA_sens_Feed 2;
BA_ "InvalidValue" SG_ 307 SRR_RR_RCTA_state "7h";
BA_ "GenSigTimeoutTime_ALL" SG_ 307 SRR_RR_RCTA_state 500;
BA_ "GenSigSendType" SG_ 307 SRR_RR_RCTA_state 2;
BA_ "InvalidValue" SG_ 307 SRR_RR_RCTA_SndWarn "0h";
BA_ "GenSigTimeoutTime_ALL" SG_ 307 SRR_RR_RCTA_SndWarn 500;
BA_ "GenSigSendType" SG_ 307 SRR_RR_RCTA_SndWarn 2;
BA_ "InvalidValue" SG_ 307 SRR_RR_RCTA_Mode_Feed "3h";
BA_ "GenSigTimeoutTime_ALL" SG_ 307 SRR_RR_RCTA_Mode_Feed 500;
BA_ "GenSigSendType" SG_ 307 SRR_RR_RCTA_Mode_Feed 2;
BA_ "InvalidValue" SG_ 307 SRR_RR_RCTA_check "3h";
BA_ "GenSigTimeoutTime_ALL" SG_ 307 SRR_RR_RCTA_check 500;
BA_ "GenSigSendType" SG_ 307 SRR_RR_RCTA_check 2;
BA_ "InvalidValue" SG_ 307 SRR_RR_DOW_SndWarn "0h";
BA_ "GenSigTimeoutTime_ALL" SG_ 307 SRR_RR_DOW_SndWarn 500;
BA_ "GenSigSendType" SG_ 307 SRR_RR_DOW_SndWarn 2;
BA_ "InvalidValue" SG_ 307 SRR_RR_DOW_WarnRight "3h";
BA_ "GenSigTimeoutTime_ALL" SG_ 307 SRR_RR_DOW_WarnRight 500;
BA_ "GenSigSendType" SG_ 307 SRR_RR_DOW_WarnRight 2;
BA_ "InvalidValue" SG_ 307 SRR_RR_DOW_WarnLeft "3h";
BA_ "GenSigTimeoutTime_ALL" SG_ 307 SRR_RR_DOW_WarnLeft 500;
BA_ "GenSigSendType" SG_ 307 SRR_RR_DOW_WarnLeft 2;
BA_ "InvalidValue" SG_ 307 SRR_RR_DOW_check "3h";
BA_ "GenSigTimeoutTime_ALL" SG_ 307 SRR_RR_DOW_check 500;
BA_ "GenSigSendType" SG_ 307 SRR_RR_DOW_check 2;
BA_ "InvalidValue" SG_ 307 SRR_RR_DOW_state "7h";
BA_ "GenSigTimeoutTime_ALL" SG_ 307 SRR_RR_DOW_state 500;
BA_ "GenSigSendType" SG_ 307 SRR_RR_DOW_state 2;
BA_ "InvalidValue" SG_ 307 SRR_RR_DOW_Mode_Feed "3h";
BA_ "GenSigTimeoutTime_ALL" SG_ 307 SRR_RR_DOW_Mode_Feed 500;
BA_ "GenSigSendType" SG_ 307 SRR_RR_DOW_Mode_Feed 2;
BA_ "InvalidValue" SG_ 307 SRR_RR_Right_block "3h";
BA_ "GenSigTimeoutTime_ALL" SG_ 307 SRR_RR_Right_block 500;
BA_ "GenSigSendType" SG_ 307 SRR_RR_Right_block 2;
BA_ "InvalidValue" SG_ 307 SRR_RR_Left_block "3h";
BA_ "GenSigTimeoutTime_ALL" SG_ 307 SRR_RR_Left_block 500;
BA_ "GenSigSendType" SG_ 307 SRR_RR_Left_block 2;
BA_ "InvalidValue" SG_ 307 Obj_ID_RL "FFh";
BA_ "GenSigTimeoutTime_ALL" SG_ 307 Obj_ID_RL 500;
BA_ "GenSigSendType" SG_ 307 Obj_ID_RL 2;
BA_ "InvalidValue" SG_ 307 Obj_Class_RL "7h";
BA_ "GenSigTimeoutTime_ALL" SG_ 307 Obj_Class_RL 500;
BA_ "GenSigSendType" SG_ 307 Obj_Class_RL 2;
BA_ "InvalidValue" SG_ 307 Obj_OrientationAngle_RL "3FFh";
BA_ "GenSigTimeoutTime_ALL" SG_ 307 Obj_OrientationAngle_RL 500;
BA_ "GenSigSendType" SG_ 307 Obj_OrientationAngle_RL 2;
BA_ "InvalidValue" SG_ 307 Obj_DistLong_RL "1FFFh";
BA_ "GenSigTimeoutTime_ALL" SG_ 307 Obj_DistLong_RL 500;
BA_ "GenSigSendType" SG_ 307 Obj_DistLong_RL 2;
BA_ "InvalidValue" SG_ 307 Obj_DislLat_RL "7FFFh";
BA_ "GenSigTimeoutTime_ALL" SG_ 307 Obj_DislLat_RL 500;
BA_ "GenSigSendType" SG_ 307 Obj_DislLat_RL 2;
BA_ "InvalidValue" SG_ 307 Obj_VrelLong_RL "3FFh";
BA_ "GenSigTimeoutTime_ALL" SG_ 307 Obj_VrelLong_RL 500;
BA_ "GenSigSendType" SG_ 307 Obj_VrelLong_RL 2;
BA_ "InvalidValue" SG_ 307 Obj_VrelLat_RL "1FFh";
BA_ "GenSigTimeoutTime_ALL" SG_ 307 Obj_VrelLat_RL 500;
BA_ "GenSigSendType" SG_ 307 Obj_VrelLat_RL 2;
BA_ "InvalidValue" SG_ 307 Obj_ID_RR "FFh";
BA_ "GenSigTimeoutTime_ALL" SG_ 307 Obj_ID_RR 500;
BA_ "GenSigSendType" SG_ 307 Obj_ID_RR 2;
BA_ "InvalidValue" SG_ 307 Obj_Class_RR "7h";
BA_ "GenSigTimeoutTime_ALL" SG_ 307 Obj_Class_RR 500;
BA_ "GenSigSendType" SG_ 307 Obj_Class_RR 2;
BA_ "InvalidValue" SG_ 307 Obj_OrientationAngle_RR "3FFh";
BA_ "GenSigTimeoutTime_ALL" SG_ 307 Obj_OrientationAngle_RR 500;
BA_ "GenSigSendType" SG_ 307 Obj_OrientationAngle_RR 2;
BA_ "InvalidValue" SG_ 307 Obj_DistLong_RR "1FFFh";
BA_ "GenSigTimeoutTime_ALL" SG_ 307 Obj_DistLong_RR 500;
BA_ "GenSigSendType" SG_ 307 Obj_DistLong_RR 2;
BA_ "InvalidValue" SG_ 307 Obj_DislLat_RR "7FFFh";
BA_ "GenSigTimeoutTime_ALL" SG_ 307 Obj_DislLat_RR 500;
BA_ "GenSigSendType" SG_ 307 Obj_DislLat_RR 2;
BA_ "InvalidValue" SG_ 307 Obj_VrelLong_RR "3FFh";
BA_ "GenSigTimeoutTime_ALL" SG_ 307 Obj_VrelLong_RR 500;
BA_ "GenSigSendType" SG_ 307 Obj_VrelLong_RR 2;
BA_ "InvalidValue" SG_ 307 Obj_VrelLat_RR "1FFh";
BA_ "GenSigTimeoutTime_ALL" SG_ 307 Obj_VrelLat_RR 500;
BA_ "GenSigSendType" SG_ 307 Obj_VrelLat_RR 2;
BA_ "InvalidValue" SG_ 307 SRR_RR_RCTB_Mode_Feed "3h";
BA_ "GenSigTimeoutTime_ALL" SG_ 307 SRR_RR_RCTB_Mode_Feed 250;
BA_ "InvalidValue" SG_ 307 SRR_RR_RCTB_State "7h";
BA_ "GenSigTimeoutTime_ALL" SG_ 307 SRR_RR_RCTB_State 250;
BA_ "InvalidValue" SG_ 307 SRR_RR_RCTB_Check "3h";
BA_ "GenSigTimeoutTime_ALL" SG_ 307 SRR_RR_RCTB_Check 250;
BA_ "InvalidValue" SG_ 307 SRR_RR_RCTB_Braking_Flag "3h";
BA_ "GenSigTimeoutTime_ALL" SG_ 307 SRR_RR_RCTB_Braking_Flag 250;
BA_ "InvalidValue" SG_ 307 SRR_RR_RCTB_Braking_Deceleration "FFh";
BA_ "GenSigTimeoutTime_ALL" SG_ 307 SRR_RR_RCTB_Braking_Deceleration 250;
BA_ "InvalidValue" SG_ 307 SRR_RR_CollisionObjID "FFh";
BA_ "GenSigTimeoutTime_ALL" SG_ 307 SRR_RR_CollisionObjID 250;
BA_ "InvalidValue" SG_ 826 ALIVE_SRR_RR_CalSensor_Status "Fh";
BA_ "InvalidValue" SG_ 826 SRR_RR_MasterSRR_check "3h";
BA_ "InvalidValue" SG_ 826 SRR_RR_CalSensorSlaverProgress "FFh";
BA_ "InvalidValue" SG_ 826 SRR_RR_CalSensorMasterProgress "FFh";
BA_ "GenSigTimeoutTime_ALL" SG_ 636 CRC_SRR_RR_TimeSynchronization_S 250;
BA_ "SystemSignalLongSymbol" SG_ 636 CRC_SRR_RR_TimeSynchronization_S "CRC_SRR_RR_TimeSynchronization_Status";
BA_ "InvalidValue" SG_ 636 ALIVE_SRR_RR_TimeSynchronization "Fh";
BA_ "GenSigTimeoutTime_ALL" SG_ 636 ALIVE_SRR_RR_TimeSynchronization 250;
BA_ "SystemSignalLongSymbol" SG_ 636 ALIVE_SRR_RR_TimeSynchronization "ALIVE_SRR_RR_TimeSynchronization_Status";
BA_ "InvalidValue" SG_ 636 SRR_RR_TimeSynchronization_Statu "3h";
BA_ "GenSigTimeoutTime_ALL" SG_ 636 SRR_RR_TimeSynchronization_Statu 250;
BA_ "SystemSignalLongSymbol" SG_ 636 SRR_RR_TimeSynchronization_Statu "SRR_RR_TimeSynchronization_Status";
BA_ "InvalidValue" SG_ 827 SRR_RR_CDS_BSD "3h";
BA_ "GenSigTimeoutTime_ALL" SG_ 827 SRR_RR_CDS_BSD 1000;
BA_ "GenSigSendType" SG_ 827 SRR_RR_CDS_BSD 2;
BA_ "InvalidValue" SG_ 827 SRR_RR_CDS_DOW "3h";
BA_ "GenSigTimeoutTime_ALL" SG_ 827 SRR_RR_CDS_DOW 1000;
BA_ "GenSigSendType" SG_ 827 SRR_RR_CDS_DOW 2;
BA_ "InvalidValue" SG_ 827 SRR_RR_CDS_RCTA "3h";
BA_ "GenSigTimeoutTime_ALL" SG_ 827 SRR_RR_CDS_RCTA 1000;
BA_ "GenSigSendType" SG_ 827 SRR_RR_CDS_RCTA 2;
BA_ "GenSigTimeoutTime_ALL" SG_ 830 CRC_SRR_RR_ObjList 250;
BA_ "InvalidValue" SG_ 830 ALIVE_SRR_RR_ObjList "Fh";
BA_ "GenSigTimeoutTime_ALL" SG_ 830 ALIVE_SRR_RR_ObjList 250;
BA_ "GenSigTimeoutTime_ALL" SG_ 830 RR_Devtimestamp 250;
BA_ "GenSigStartValue" SG_ 830 RR_Obj1_ID 255;
BA_ "GenSigTimeoutTime_ALL" SG_ 830 RR_Obj1_ID 250;
BA_ "GenSigTimeoutTime_ALL" SG_ 830 RR_Obj1_DistLong 250;
BA_ "GenSigTimeoutTime_ALL" SG_ 830 RR_Obj1_DislLat 250;
BA_ "GenSigTimeoutTime_ALL" SG_ 830 RR_Obj1_VrelLong 250;
BA_ "GenSigStartValue" SG_ 830 RR_Obj1_DynProp 4;
BA_ "GenSigTimeoutTime_ALL" SG_ 830 RR_Obj1_DynProp 250;
BA_ "GenSigTimeoutTime_ALL" SG_ 830 RR_Obj1_VrelLat 250;
BA_ "GenSigTimeoutTime_ALL" SG_ 830 RR_Obj1_RCS 250;
BA_ "InvalidValue" SG_ 830 RR_Obj1_MeasState "7h";
BA_ "GenSigStartValue" SG_ 830 RR_Obj1_MeasState 7;
BA_ "GenSigTimeoutTime_ALL" SG_ 830 RR_Obj1_MeasState 250;
BA_ "GenSigTimeoutTime_ALL" SG_ 830 RR_Obj1_ProbOfExist 250;
BA_ "GenSigTimeoutTime_ALL" SG_ 830 RR_Obj1_ArelLong 250;
BA_ "InvalidValue" SG_ 830 RR_Obj1j_Class "7h";
BA_ "GenSigStartValue" SG_ 830 RR_Obj1j_Class 7;
BA_ "GenSigTimeoutTime_ALL" SG_ 830 RR_Obj1j_Class 250;
BA_ "InvalidValue" SG_ 830 RR_Obj1_ArelLat "7h";
BA_ "GenSigTimeoutTime_ALL" SG_ 830 RR_Obj1_ArelLat 250;
BA_ "InvalidValue" SG_ 830 RR_Obj1_Length "7h";
BA_ "GenSigTimeoutTime_ALL" SG_ 830 RR_Obj1_Length 250;
BA_ "InvalidValue" SG_ 830 RR_Obj1_Width "7h";
BA_ "GenSigTimeoutTime_ALL" SG_ 830 RR_Obj1_Width 250;
BA_ "GenSigStartValue" SG_ 830 RR_Obj2_ID 255;
BA_ "GenSigTimeoutTime_ALL" SG_ 830 RR_Obj2_ID 250;
BA_ "GenSigTimeoutTime_ALL" SG_ 830 RR_Obj2_DistLong 250;
BA_ "GenSigTimeoutTime_ALL" SG_ 830 RR_Obj2_DislLat 250;
BA_ "GenSigTimeoutTime_ALL" SG_ 830 RR_Obj2_VrelLong 250;
BA_ "GenSigStartValue" SG_ 830 RR_Obj2_DynProp 4;
BA_ "GenSigTimeoutTime_ALL" SG_ 830 RR_Obj2_DynProp 250;
BA_ "GenSigTimeoutTime_ALL" SG_ 830 RR_Obj2_VrelLat 250;
BA_ "GenSigTimeoutTime_ALL" SG_ 830 RR_Obj2_RCS 250;
BA_ "InvalidValue" SG_ 830 RR_Obj2_MeasState "7h";
BA_ "GenSigStartValue" SG_ 830 RR_Obj2_MeasState 7;
BA_ "GenSigTimeoutTime_ALL" SG_ 830 RR_Obj2_MeasState 250;
BA_ "GenSigTimeoutTime_ALL" SG_ 830 RR_Obj2_ProbOfExist 250;
BA_ "GenSigTimeoutTime_ALL" SG_ 830 RR_Obj2_ArelLong 250;
BA_ "InvalidValue" SG_ 830 RR_Obj2j_Class "7h";
BA_ "GenSigStartValue" SG_ 830 RR_Obj2j_Class 7;
BA_ "GenSigTimeoutTime_ALL" SG_ 830 RR_Obj2j_Class 250;
BA_ "InvalidValue" SG_ 830 RR_Obj2_ArelLat "7h";
BA_ "GenSigTimeoutTime_ALL" SG_ 830 RR_Obj2_ArelLat 250;
BA_ "InvalidValue" SG_ 830 RR_Obj2_Length "7h";
BA_ "GenSigTimeoutTime_ALL" SG_ 830 RR_Obj2_Length 250;
BA_ "InvalidValue" SG_ 830 RR_Obj2_Width "7h";
BA_ "GenSigTimeoutTime_ALL" SG_ 830 RR_Obj2_Width 250;
BA_ "GenSigStartValue" SG_ 830 RR_Obj3_ID 255;
BA_ "GenSigTimeoutTime_ALL" SG_ 830 RR_Obj3_ID 250;
BA_ "GenSigTimeoutTime_ALL" SG_ 830 RR_Obj3_DistLong 250;
BA_ "GenSigTimeoutTime_ALL" SG_ 830 RR_Obj3_DislLat 250;
BA_ "GenSigTimeoutTime_ALL" SG_ 830 RR_Obj3_VrelLong 250;
BA_ "GenSigStartValue" SG_ 830 RR_Obj3_DynProp 4;
BA_ "GenSigTimeoutTime_ALL" SG_ 830 RR_Obj3_DynProp 250;
BA_ "GenSigTimeoutTime_ALL" SG_ 830 RR_Obj3_VrelLat 250;
BA_ "GenSigTimeoutTime_ALL" SG_ 830 RR_Obj3_RCS 250;
BA_ "InvalidValue" SG_ 830 RR_Obj3_MeasState "7h";
BA_ "GenSigStartValue" SG_ 830 RR_Obj3_MeasState 7;
BA_ "GenSigTimeoutTime_ALL" SG_ 830 RR_Obj3_MeasState 250;
BA_ "GenSigTimeoutTime_ALL" SG_ 830 RR_Obj3_ProbOfExist 250;
BA_ "GenSigTimeoutTime_ALL" SG_ 830 RR_Obj3_ArelLong 250;
BA_ "InvalidValue" SG_ 830 RR_Obj3j_Class "7h";
BA_ "GenSigStartValue" SG_ 830 RR_Obj3j_Class 7;
BA_ "GenSigTimeoutTime_ALL" SG_ 830 RR_Obj3j_Class 250;
BA_ "InvalidValue" SG_ 830 RR_Obj3_ArelLat "7h";
BA_ "GenSigTimeoutTime_ALL" SG_ 830 RR_Obj3_ArelLat 250;
BA_ "InvalidValue" SG_ 830 RR_Obj3_Length "7h";
BA_ "GenSigTimeoutTime_ALL" SG_ 830 RR_Obj3_Length 250;
BA_ "InvalidValue" SG_ 830 RR_Obj3_Width "7h";
BA_ "GenSigTimeoutTime_ALL" SG_ 830 RR_Obj3_Width 250;
BA_ "GenSigStartValue" SG_ 830 RR_Obj4_ID 255;
BA_ "GenSigTimeoutTime_ALL" SG_ 830 RR_Obj4_ID 250;
BA_ "GenSigTimeoutTime_ALL" SG_ 830 RR_Obj4_DistLong 250;
BA_ "GenSigTimeoutTime_ALL" SG_ 830 RR_Obj4_DislLat 250;
BA_ "GenSigTimeoutTime_ALL" SG_ 830 RR_Obj4_VrelLong 250;
BA_ "GenSigStartValue" SG_ 830 RR_Obj4_DynProp 4;
BA_ "GenSigTimeoutTime_ALL" SG_ 830 RR_Obj4_DynProp 250;
BA_ "GenSigTimeoutTime_ALL" SG_ 830 RR_Obj4_VrelLat 250;
BA_ "GenSigTimeoutTime_ALL" SG_ 830 RR_Obj4_RCS 250;
BA_ "InvalidValue" SG_ 830 RR_Obj4_MeasState "7h";
BA_ "GenSigStartValue" SG_ 830 RR_Obj4_MeasState 7;
BA_ "GenSigTimeoutTime_ALL" SG_ 830 RR_Obj4_MeasState 250;
BA_ "GenSigTimeoutTime_ALL" SG_ 830 RR_Obj4_ProbOfExist 250;
BA_ "GenSigTimeoutTime_ALL" SG_ 830 RR_Obj4_ArelLong 250;
BA_ "InvalidValue" SG_ 830 RR_Obj4j_Class "7h";
BA_ "GenSigStartValue" SG_ 830 RR_Obj4j_Class 7;
BA_ "GenSigTimeoutTime_ALL" SG_ 830 RR_Obj4j_Class 250;
BA_ "InvalidValue" SG_ 830 RR_Obj4_ArelLat "7h";
BA_ "GenSigTimeoutTime_ALL" SG_ 830 RR_Obj4_ArelLat 250;
BA_ "InvalidValue" SG_ 830 RR_Obj4_Length "7h";
BA_ "GenSigTimeoutTime_ALL" SG_ 830 RR_Obj4_Length 250;
BA_ "InvalidValue" SG_ 830 RR_Obj4_Width "7h";
BA_ "GenSigTimeoutTime_ALL" SG_ 830 RR_Obj4_Width 250;
BA_ "GenSigTimeoutTime_ALL" SG_ 637 CRC_SRR_FL_TimeSynchronization_S 250;
BA_ "SystemSignalLongSymbol" SG_ 637 CRC_SRR_FL_TimeSynchronization_S "CRC_SRR_FL_TimeSynchronization_Status";
BA_ "InvalidValue" SG_ 637 ALIVE_SRR_FL_TimeSynchronization "Fh";
BA_ "GenSigTimeoutTime_ALL" SG_ 637 ALIVE_SRR_FL_TimeSynchronization 250;
BA_ "SystemSignalLongSymbol" SG_ 637 ALIVE_SRR_FL_TimeSynchronization "ALIVE_SRR_FL_TimeSynchronization_Status";
BA_ "InvalidValue" SG_ 637 SRR_FL_TimeSynchronization_Statu "3h";
BA_ "GenSigTimeoutTime_ALL" SG_ 637 SRR_FL_TimeSynchronization_Statu 250;
BA_ "SystemSignalLongSymbol" SG_ 637 SRR_FL_TimeSynchronization_Statu "SRR_FL_TimeSynchronization_Status";
BA_ "GenSigTimeoutTime_ALL" SG_ 638 CRC_SRR_FR_TimeSynchronization_S 250;
BA_ "SystemSignalLongSymbol" SG_ 638 CRC_SRR_FR_TimeSynchronization_S "CRC_SRR_FR_TimeSynchronization_Status";
BA_ "InvalidValue" SG_ 638 ALIVE_SRR_FR_TimeSynchronization "Fh";
BA_ "GenSigTimeoutTime_ALL" SG_ 638 ALIVE_SRR_FR_TimeSynchronization 250;
BA_ "SystemSignalLongSymbol" SG_ 638 ALIVE_SRR_FR_TimeSynchronization "ALIVE_SRR_FR_TimeSynchronization_Status";
BA_ "InvalidValue" SG_ 638 SRR_FR_TimeSynchronization_Statu "3h";
BA_ "GenSigTimeoutTime_ALL" SG_ 638 SRR_FR_TimeSynchronization_Statu 250;
BA_ "SystemSignalLongSymbol" SG_ 638 SRR_FR_TimeSynchronization_Statu "SRR_FR_TimeSynchronization_Status";
BA_ "GenSigTimeoutTime_ALL" SG_ 315 CRC_SRR_FR_IA_FCTB 200;
BA_ "InvalidValue" SG_ 315 ALIVE_SRR_FR_IA_FCTB "Fh";
BA_ "GenSigTimeoutTime_ALL" SG_ 315 ALIVE_SRR_FR_IA_FCTB 200;
BA_ "InvalidValue" SG_ 315 SRR_FR_IA_Mode_Feed "0h";
BA_ "GenSigTimeoutTime_ALL" SG_ 315 SRR_FR_IA_Mode_Feed 200;
BA_ "InvalidValue" SG_ 315 SRR_FR_IA_State "4h";
BA_ "GenSigTimeoutTime_ALL" SG_ 315 SRR_FR_IA_State 200;
BA_ "InvalidValue" SG_ 315 SRR_FR_IA_Check "3h";
BA_ "GenSigTimeoutTime_ALL" SG_ 315 SRR_FR_IA_Check 200;
BA_ "InvalidValue" SG_ 315 SRR_FR_FCTB_Braking_Flag "0h";
BA_ "GenSigTimeoutTime_ALL" SG_ 315 SRR_FR_FCTB_Braking_Flag 200;
BA_ "InvalidValue" SG_ 315 SRR_FR_FCTB_Braking_Deceleration "0h";
BA_ "GenSigTimeoutTime_ALL" SG_ 315 SRR_FR_FCTB_Braking_Deceleration 200;
BA_ "InvalidValue" SG_ 315 SRR_FR_FCTB_Mode_Feed "0h";
BA_ "GenSigTimeoutTime_ALL" SG_ 315 SRR_FR_FCTB_Mode_Feed 200;
BA_ "InvalidValue" SG_ 315 SRR_FR_FCTB_State "4h";
BA_ "GenSigTimeoutTime_ALL" SG_ 315 SRR_FR_FCTB_State 200;
BA_ "InvalidValue" SG_ 315 SRR_FR_FCTB_Check "2h";
BA_ "GenSigTimeoutTime_ALL" SG_ 315 SRR_FR_FCTB_Check 200;
BA_ "InvalidValue" SG_ 315 SRR_FR_IA_Left_Warning "0h";
BA_ "GenSigTimeoutTime_ALL" SG_ 315 SRR_FR_IA_Left_Warning 200;
BA_ "InvalidValue" SG_ 315 SRR_FR_IA_Right_Warning "0h";
BA_ "GenSigTimeoutTime_ALL" SG_ 315 SRR_FR_IA_Right_Warning 200;
BA_ "InvalidValue" SG_ 315 SRR_FR_CollisionObjID "0h";
BA_ "GenSigTimeoutTime_ALL" SG_ 315 SRR_FR_CollisionObjID 100;
BA_ "GenSigTimeoutTime_ALL" SG_ 828 CRC_SRR_FR_CalSensor_Status 200;
BA_ "InvalidValue" SG_ 828 ALIVE_SRR_FR_CalSensor_Status "Fh";
BA_ "GenSigTimeoutTime_ALL" SG_ 828 ALIVE_SRR_FR_CalSensor_Status 200;
BA_ "GenSigTimeoutTime_ALL" SG_ 828 SRR_FR_RadarRight_Cal_Status 200;
BA_ "InvalidValue" SG_ 828 SRR_FR_MasterSRR_check "3h";
BA_ "GenSigTimeoutTime_ALL" SG_ 828 SRR_FR_MasterSRR_check 200;
BA_ "GenSigTimeoutTime_ALL" SG_ 828 SRR_FR_RadarRight_DynaCal_Status 200;
BA_ "GenSigTimeoutTime_ALL" SG_ 828 SRR_FR_RadarLeft_Cal_Status 200;
BA_ "GenSigTimeoutTime_ALL" SG_ 828 SRR_FR_RadarLeft_DynaCal_Status 200;
BA_ "GenSigTimeoutTime_ALL" SG_ 828 SRR_FR_SlaveSRR_check 200;
BA_ "InvalidValue" SG_ 828 SRR_FR_CalSensorMasterProgress "FFh";
BA_ "GenSigTimeoutTime_ALL" SG_ 828 SRR_FR_CalSensorMasterProgress 200;
BA_ "InvalidValue" SG_ 828 SRR_FR_CalSensorSlaverProgress "FFh";
BA_ "GenSigTimeoutTime_ALL" SG_ 828 SRR_FR_CalSensorSlaverProgress 200;
BA_ "GenSigTimeoutTime_ALL" SG_ 828 SRR_FR_Cal_LeftInstallDeviation 200;
BA_ "GenSigTimeoutTime_ALL" SG_ 828 SRR_FR_Cal_RightInstallDeviation 200;
BA_ "GenSigTimeoutTime_ALL" SG_ 639 CRC_ADCU_TimeSynchronization_Sta 250;
BA_ "SystemSignalLongSymbol" SG_ 639 CRC_ADCU_TimeSynchronization_Sta "CRC_ADCU_TimeSynchronization_Status";
BA_ "InvalidValue" SG_ 639 ALIVE_ADCU_TimeSynchronization_S "Fh";
BA_ "GenSigTimeoutTime_ALL" SG_ 639 ALIVE_ADCU_TimeSynchronization_S 250;
BA_ "SystemSignalLongSymbol" SG_ 639 ALIVE_ADCU_TimeSynchronization_S "ALIVE_ADCU_TimeSynchronization_Status";
BA_ "InvalidValue" SG_ 639 ADCU_TimeSynchronization_Status "3h";
BA_ "GenSigTimeoutTime_ALL" SG_ 639 ADCU_TimeSynchronization_Status 250;
BA_ "GenSigTimeoutTime_ALL" SG_ 543 CRC_ADCU_AEB_FCW 500;
BA_ "InvalidValue" SG_ 543 ALIVE_ADCU_AEB_FCW "Fh";
BA_ "GenSigTimeoutTime_ALL" SG_ 543 ALIVE_ADCU_AEB_FCW 500;
BA_ "InvalidValue" SG_ 543 ADCU_AEB_Warning "3h";
BA_ "GenSigTimeoutTime_ALL" SG_ 543 ADCU_AEB_Warning 500;
BA_ "GenSigSendType" SG_ 543 ADCU_AEB_Warning 4;
BA_ "InvalidValue" SG_ 543 ADCU_AEB_State "3h";
BA_ "GenSigStartValue" SG_ 543 ADCU_AEB_State 1;
BA_ "GenSigTimeoutTime_ALL" SG_ 543 ADCU_AEB_State 500;
BA_ "InvalidValue" SG_ 543 ADCU_AEB_Mode_Feed "3h";
BA_ "GenSigStartValue" SG_ 543 ADCU_AEB_Mode_Feed 1;
BA_ "GenSigTimeoutTime_ALL" SG_ 543 ADCU_AEB_Mode_Feed 500;
BA_ "InvalidValue" SG_ 543 ADCU_AEB_check "3h";
BA_ "GenSigTimeoutTime_ALL" SG_ 543 ADCU_AEB_check 500;
BA_ "GenSigStartValue" SG_ 543 ADCU_FCW_Mode_Feed 1;
BA_ "GenSigTimeoutTime_ALL" SG_ 543 ADCU_FCW_Mode_Feed 500;
BA_ "GenSigSendType" SG_ 543 ADCU_FCW_Mode_Feed 2;
BA_ "GenSigStartValue" SG_ 543 ADCU_FCW_Sens_Feed 1;
BA_ "GenSigTimeoutTime_ALL" SG_ 543 ADCU_FCW_Sens_Feed 500;
BA_ "GenSigSendType" SG_ 543 ADCU_FCW_Sens_Feed 2;
BA_ "GenSigStartValue" SG_ 543 ADCU_FCW_state 1;
BA_ "GenSigTimeoutTime_ALL" SG_ 543 ADCU_FCW_state 500;
BA_ "GenSigSendType" SG_ 543 ADCU_FCW_state 2;
BA_ "InvalidValue" SG_ 543 ADCU_FCW_check "3h";
BA_ "GenSigTimeoutTime_ALL" SG_ 543 ADCU_FCW_check 500;
BA_ "GenSigSendType" SG_ 543 ADCU_FCW_check 2;
BA_ "InvalidValue" SG_ 543 ADCU_FCW_warning "3h";
BA_ "GenSigTimeoutTime_ALL" SG_ 543 ADCU_FCW_warning 500;
BA_ "GenSigSendType" SG_ 543 ADCU_FCW_warning 2;
BA_ "GenSigSendType" SG_ 543 ADCU_CV_AEB_Alert 2;
BA_ "GenSigSendType" SG_ 543 ADCU_CV_FCW_Alert 2;
BA_ "GenSigSendType" SG_ 543 ADCU_CV_PartialAEB_Alert 2;
BA_ "GenSigSendType" SG_ 543 ADCU_CV_PreFill_Alert 2;
BA_ "GenSigSendType" SG_ 543 ADCU_VD_AEB_Alert 2;
BA_ "GenSigSendType" SG_ 543 ADCU_VD_DBS_Alert 2;
BA_ "GenSigSendType" SG_ 543 ADCU_VD_EGOTAP_AEB_Alert 2;
BA_ "GenSigSendType" SG_ 543 ADCU_VD_FCW_Alert 2;
BA_ "GenSigSendType" SG_ 543 ADCU_VD_HeadOn_AEB_Alert 2;
BA_ "GenSigSendType" SG_ 543 ADCU_VD_PartialAEB_Alert 2;
BA_ "GenSigSendType" SG_ 543 ADCU_VD_Prefill_Alert 2;
BA_ "GenSigSendType" SG_ 543 ADCU_VRU_AEB_Alert 2;
BA_ "GenSigSendType" SG_ 543 ADCU_VRU_FCW_Alert 2;
BA_ "GenSigSendType" SG_ 543 ADCU_VRU_PreFill_Alert 2;
BA_ "GenSigSendType" SG_ 543 ADCU_Fusion_TTC 2;
BA_ "GenSigSendType" SG_ 543 ADCU_AB_TTC 2;
BA_ "GenSigSendType" SG_ 543 ADCU_AEB_Trigger_Source 2;
BA_ "GenSigSendType" SG_ 543 ADCU_FCW_Trigger_Source 2;
BA_ "GenSigTimeoutTime_ALL" SG_ 551 CRC_ADCU_AESA_AAESA_Status 500;
BA_ "InvalidValue" SG_ 551 ALIVE_ADCU_AESA_AAESA_Status "Fh";
BA_ "GenSigTimeoutTime_ALL" SG_ 551 ALIVE_ADCU_AESA_AAESA_Status 500;
BA_ "GenSigTimeoutTime_ALL" SG_ 551 ADCU_AESA_AAESA_Status 500;
BA_ "GenSigSendType" SG_ 551 ADCU_AESA_AAESA_Status 2;
BA_ "GenSigTimeoutTime_ALL" SG_ 551 ADCU_AESA_AAESA_ECALLReq 500;
BA_ "GenSigSendType" SG_ 551 ADCU_AESA_AAESA_ECALLReq 2;
BA_ "GenSigTimeoutTime_ALL" SG_ 551 ADCU_AESA_AAESA_DoorUnlockReq 500;
BA_ "GenSigSendType" SG_ 551 ADCU_AESA_AAESA_DoorUnlockReq 2;
BA_ "GenSigTimeoutTime_ALL" SG_ 551 ADCU_AESA_AAESA_popup 500;
BA_ "GenSigSendType" SG_ 551 ADCU_AESA_AAESA_popup 2;
BA_ "GenSigTimeoutTime_ALL" SG_ 552 ESA_Freespace 200;
BA_ "GenSigTimeoutTime_ALL" SG_ 556 CRC_ADCU_FCAM_NOP_Status 5000;
BA_ "InvalidValue" SG_ 556 ALIVE_ADCU_FCAM_NOP_Status "Fh";
BA_ "GenSigTimeoutTime_ALL" SG_ 556 ALIVE_ADCU_FCAM_NOP_Status 5000;
BA_ "InvalidValue" SG_ 556 ADCU_FCAM_ALCA_state "0h";
BA_ "GenSigTimeoutTime_ALL" SG_ 556 ADCU_FCAM_ALCA_state 100;
BA_ "InvalidValue" SG_ 556 ADCU_NOP_check "3h";
BA_ "GenSigTimeoutTime_ALL" SG_ 556 ADCU_NOP_check 250;
BA_ "GenSigTimeoutTime_ALL" SG_ 556 ADCU_NOP_state 250;
BA_ "InvalidValue" SG_ 556 ADCU_NOP_ICON_Feed "7h";
BA_ "GenSigTimeoutTime_ALL" SG_ 556 ADCU_NOP_ICON_Feed 250;
BA_ "InvalidValue" SG_ 556 ADCU_NOP_txtpopup "1Fh";
BA_ "GenSigTimeoutTime_ALL" SG_ 556 ADCU_NOP_txtpopup 250;
BA_ "InvalidValue" SG_ 556 ADCU_NOP_Warning "3h";
BA_ "GenSigTimeoutTime_ALL" SG_ 556 ADCU_NOP_Warning 250;
BA_ "InvalidValue" SG_ 556 ADCU_NOP_AAESA_textpopup "7h";
BA_ "GenSigTimeoutTime_ALL" SG_ 556 ADCU_NOP_AAESA_textpopup 250;
BA_ "InvalidValue" SG_ 556 ADCU_NOP_TOR "7h";
BA_ "GenSigTimeoutTime_ALL" SG_ 556 ADCU_NOP_TOR 250;
BA_ "InvalidValue" SG_ 556 ADCU_eyesoff_Warning_Mode_2 "7h";
BA_ "GenSigTimeoutTime_ALL" SG_ 556 ADCU_eyesoff_Warning_Mode_2 250;
BA_ "GenSigTimeoutTime_ALL" SG_ 556 ADCU_EOD 250;
BA_ "InvalidValue" SG_ 556 ADCU_NOP_Mode_Feed "0h";
BA_ "GenSigTimeoutTime_ALL" SG_ 556 ADCU_NOP_Mode_Feed 250;
BA_ "InvalidValue" SG_ 556 ADCU_NOP_Type_Feed "3h";
BA_ "GenSigTimeoutTime_ALL" SG_ 556 ADCU_NOP_Type_Feed 250;
BA_ "InvalidValue" SG_ 556 ADCU_DCA_Alert "7h";
BA_ "GenSigTimeoutTime_ALL" SG_ 556 ADCU_DCA_Alert 250;
BA_ "GenSigTimeoutTime_ALL" SG_ 556 ADCU_AAESA_Status 50;
BA_ "GenSigTimeoutTime_ALL" SG_ 556 ADCU_HWA_ALCA_Status 50;
BA_ "GenSigTimeoutTime_ALL" SG_ 556 ADCU_NOP_ALCA_Status 50;
BA_ "GenSigTimeoutTime_ALL" SG_ 556 ADCU_ALC_Mode_feed 50;
BA_ "GenSigTimeoutTime_ALL" SG_ 556 ADCU_ALC_txtpopup 50;
BA_ "GenSigTimeoutTime_ALL" SG_ 556 ADCU_AESA_popup 50;
BA_ "GenSigTimeoutTime_ALL" SG_ 556 ADCU_ALC_Mode_Gaze_Feed 50;
BA_ "GenSigTimeoutTime_ALL" SG_ 556 ADCU_ALC_Mode_Recommend_Feed 50;
BA_ "GenSigTimeoutTime_ALL" SG_ 556 ADCU_ALC_ICON_Feed 50;
BA_ "InvalidValue" SG_ 556 ADCU_FCAM_NOP_ODD_Sts "3h";
BA_ "GenSigTimeoutTime_ALL" SG_ 556 ADCU_FCAM_NOP_ODD_Sts 100;
BA_ "InvalidValue" SG_ 556 ADCU_FCAM_ALCA_TurnIndicatorReq "4h";
BA_ "GenSigTimeoutTime_ALL" SG_ 556 ADCU_FCAM_ALCA_TurnIndicatorReq 100;
BA_ "InvalidValue" SG_ 556 ADCU_FCAM_ALCA_textpopup "0h";
BA_ "GenSigTimeoutTime_ALL" SG_ 556 ADCU_FCAM_ALCA_textpopup 100;
BA_ "GenSigTimeoutTime_ALL" SG_ 577 CRC_ADCU_PA_STATUS 1000;
BA_ "InvalidValue" SG_ 577 ALIVE_ADCU_PA_STATUS "Fh";
BA_ "GenSigTimeoutTime_ALL" SG_ 577 ALIVE_ADCU_PA_STATUS 1000;
BA_ "GenSigTimeoutTime_ALL" SG_ 577 ADCU_PA_AutoOn_Feed 1000;
BA_ "InvalidValue" SG_ 577 ADCU_FPA_State "3h";
BA_ "GenSigStartValue" SG_ 577 ADCU_FPA_State 3;
BA_ "GenSigTimeoutTime_ALL" SG_ 577 ADCU_FPA_State 1000;
BA_ "InvalidValue" SG_ 577 ADCU_RPA_State "3h";
BA_ "GenSigStartValue" SG_ 577 ADCU_RPA_State 3;
BA_ "GenSigTimeoutTime_ALL" SG_ 577 ADCU_RPA_State 1000;
BA_ "InvalidValue" SG_ 577 ADCU_SPA_State "3h";
BA_ "GenSigStartValue" SG_ 577 ADCU_SPA_State 3;
BA_ "GenSigTimeoutTime_ALL" SG_ 577 ADCU_SPA_State 1000;
BA_ "GenSigTimeoutTime_ALL" SG_ 577 ADCU_RPA_Available 1000;
BA_ "GenSigTimeoutTime_ALL" SG_ 577 ADCU_NSPA_Available 1000;
BA_ "GenSigTimeoutTime_ALL" SG_ 577 ADCU_FPA_Available 1000;
BA_ "InvalidValue" SG_ 577 ADCU_FPA_Check "3h";
BA_ "GenSigStartValue" SG_ 577 ADCU_FPA_Check 3;
BA_ "GenSigTimeoutTime_ALL" SG_ 577 ADCU_FPA_Check 1000;
BA_ "InvalidValue" SG_ 577 ADCU_RPA_Check "3h";
BA_ "GenSigStartValue" SG_ 577 ADCU_RPA_Check 3;
BA_ "GenSigTimeoutTime_ALL" SG_ 577 ADCU_RPA_Check 1000;
BA_ "InvalidValue" SG_ 577 ADCU_NSPA_Check "3h";
BA_ "GenSigStartValue" SG_ 577 ADCU_NSPA_Check 3;
BA_ "GenSigTimeoutTime_ALL" SG_ 577 ADCU_NSPA_Check 1000;
BA_ "GenSigTimeoutTime_ALL" SG_ 579 CRC_ADCU_PA_FPA 500;
BA_ "InvalidValue" SG_ 579 ALIVE_ADCU_PA_FPA "Fh";
BA_ "GenSigTimeoutTime_ALL" SG_ 579 ALIVE_ADCU_PA_FPA 500;
BA_ "InvalidValue" SG_ 579 ADCU_FPA_AlertFIL "7h";
BA_ "GenSigStartValue" SG_ 579 ADCU_FPA_AlertFIL 7;
BA_ "GenSigTimeoutTime_ALL" SG_ 579 ADCU_FPA_AlertFIL 500;
BA_ "GenSigSendType" SG_ 579 ADCU_FPA_AlertFIL 2;
BA_ "InvalidValue" SG_ 579 ADCU_FPA_AlertFOL "7h";
BA_ "GenSigStartValue" SG_ 579 ADCU_FPA_AlertFOL 7;
BA_ "GenSigTimeoutTime_ALL" SG_ 579 ADCU_FPA_AlertFOL 500;
BA_ "GenSigSendType" SG_ 579 ADCU_FPA_AlertFOL 2;
BA_ "InvalidValue" SG_ 579 ADCU_FPA_AlertFIR "7h";
BA_ "GenSigStartValue" SG_ 579 ADCU_FPA_AlertFIR 7;
BA_ "GenSigTimeoutTime_ALL" SG_ 579 ADCU_FPA_AlertFIR 500;
BA_ "GenSigSendType" SG_ 579 ADCU_FPA_AlertFIR 2;
BA_ "InvalidValue" SG_ 579 ADCU_FPA_AlertFOR "7h";
BA_ "GenSigStartValue" SG_ 579 ADCU_FPA_AlertFOR 7;
BA_ "GenSigTimeoutTime_ALL" SG_ 579 ADCU_FPA_AlertFOR 500;
BA_ "GenSigSendType" SG_ 579 ADCU_FPA_AlertFOR 2;
BA_ "InvalidValue" SG_ 579 ADCU_FPA_AlertFSL "7h";
BA_ "GenSigStartValue" SG_ 579 ADCU_FPA_AlertFSL 7;
BA_ "GenSigTimeoutTime_ALL" SG_ 579 ADCU_FPA_AlertFSL 500;
BA_ "GenSigSendType" SG_ 579 ADCU_FPA_AlertFSL 2;
BA_ "InvalidValue" SG_ 579 ADCU_FPA_AlertFSR "7h";
BA_ "GenSigStartValue" SG_ 579 ADCU_FPA_AlertFSR 7;
BA_ "GenSigTimeoutTime_ALL" SG_ 579 ADCU_FPA_AlertFSR 500;
BA_ "GenSigSendType" SG_ 579 ADCU_FPA_AlertFSR 2;
BA_ "InvalidValue" SG_ 579 ADCU_FPA_DistFIL "FFh";
BA_ "GenSigStartValue" SG_ 579 ADCU_FPA_DistFIL 255;
BA_ "GenSigTimeoutTime_ALL" SG_ 579 ADCU_FPA_DistFIL 500;
BA_ "InvalidValue" SG_ 579 ADCU_FPA_DistFOL "FFh";
BA_ "GenSigStartValue" SG_ 579 ADCU_FPA_DistFOL 255;
BA_ "GenSigTimeoutTime_ALL" SG_ 579 ADCU_FPA_DistFOL 500;
BA_ "InvalidValue" SG_ 579 ADCU_FPA_DistFIR "FFh";
BA_ "GenSigStartValue" SG_ 579 ADCU_FPA_DistFIR 255;
BA_ "GenSigTimeoutTime_ALL" SG_ 579 ADCU_FPA_DistFIR 500;
BA_ "InvalidValue" SG_ 579 ADCU_FPA_DistFOR "FFh";
BA_ "GenSigStartValue" SG_ 579 ADCU_FPA_DistFOR 255;
BA_ "GenSigTimeoutTime_ALL" SG_ 579 ADCU_FPA_DistFOR 500;
BA_ "InvalidValue" SG_ 579 ADCU_FPA_DistFSL "FFh";
BA_ "GenSigStartValue" SG_ 579 ADCU_FPA_DistFSL 255;
BA_ "GenSigTimeoutTime_ALL" SG_ 579 ADCU_FPA_DistFSL 500;
BA_ "InvalidValue" SG_ 579 ADCU_FPA_DistFSR "FFh";
BA_ "GenSigStartValue" SG_ 579 ADCU_FPA_DistFSR 255;
BA_ "GenSigTimeoutTime_ALL" SG_ 579 ADCU_FPA_DistFSR 500;
BA_ "GenSigTimeoutTime_ALL" SG_ 579 ADCU_FPA_ChimeReqFIL 500;
BA_ "GenSigTimeoutTime_ALL" SG_ 579 ADCU_FPA_ChimeReqFOL 500;
BA_ "GenSigTimeoutTime_ALL" SG_ 579 ADCU_FPA_ChimeReqFIR 500;
BA_ "GenSigTimeoutTime_ALL" SG_ 579 ADCU_FPA_ChimeReqFOR 500;
BA_ "GenSigTimeoutTime_ALL" SG_ 579 ADCU_FPA_ChimeReqFSL 500;
BA_ "GenSigTimeoutTime_ALL" SG_ 579 ADCU_FPA_ChimeReqFSR 500;
BA_ "GenSigTimeoutTime_ALL" SG_ 580 CRC_ADCU_PA_RPA 500;
BA_ "InvalidValue" SG_ 580 ALIVE_ADCU_PA_RPA "Fh";
BA_ "GenSigTimeoutTime_ALL" SG_ 580 ALIVE_ADCU_PA_RPA 500;
BA_ "InvalidValue" SG_ 580 ADCU_RPA_AlertRIL "7h";
BA_ "GenSigStartValue" SG_ 580 ADCU_RPA_AlertRIL 7;
BA_ "GenSigTimeoutTime_ALL" SG_ 580 ADCU_RPA_AlertRIL 500;
BA_ "GenSigSendType" SG_ 580 ADCU_RPA_AlertRIL 2;
BA_ "InvalidValue" SG_ 580 ADCU_RPA_AlertROL "7h";
BA_ "GenSigStartValue" SG_ 580 ADCU_RPA_AlertROL 7;
BA_ "GenSigTimeoutTime_ALL" SG_ 580 ADCU_RPA_AlertROL 500;
BA_ "GenSigSendType" SG_ 580 ADCU_RPA_AlertROL 2;
BA_ "InvalidValue" SG_ 580 ADCU_RPA_AlertRIR "7h";
BA_ "GenSigStartValue" SG_ 580 ADCU_RPA_AlertRIR 7;
BA_ "GenSigTimeoutTime_ALL" SG_ 580 ADCU_RPA_AlertRIR 500;
BA_ "GenSigSendType" SG_ 580 ADCU_RPA_AlertRIR 2;
BA_ "InvalidValue" SG_ 580 ADCU_RPA_AlertROR "7h";
BA_ "GenSigStartValue" SG_ 580 ADCU_RPA_AlertROR 7;
BA_ "GenSigTimeoutTime_ALL" SG_ 580 ADCU_RPA_AlertROR 500;
BA_ "GenSigSendType" SG_ 580 ADCU_RPA_AlertROR 2;
BA_ "InvalidValue" SG_ 580 ADCU_RPA_AlertRSL "7h";
BA_ "GenSigStartValue" SG_ 580 ADCU_RPA_AlertRSL 7;
BA_ "GenSigTimeoutTime_ALL" SG_ 580 ADCU_RPA_AlertRSL 500;
BA_ "GenSigSendType" SG_ 580 ADCU_RPA_AlertRSL 2;
BA_ "InvalidValue" SG_ 580 ADCU_RPA_AlertRSR "7h";
BA_ "GenSigStartValue" SG_ 580 ADCU_RPA_AlertRSR 7;
BA_ "GenSigTimeoutTime_ALL" SG_ 580 ADCU_RPA_AlertRSR 500;
BA_ "GenSigSendType" SG_ 580 ADCU_RPA_AlertRSR 2;
BA_ "InvalidValue" SG_ 580 ADCU_RPA_DistRIL "FFh";
BA_ "GenSigStartValue" SG_ 580 ADCU_RPA_DistRIL 255;
BA_ "GenSigTimeoutTime_ALL" SG_ 580 ADCU_RPA_DistRIL 500;
BA_ "InvalidValue" SG_ 580 ADCU_RPA_DistROL "FFh";
BA_ "GenSigStartValue" SG_ 580 ADCU_RPA_DistROL 255;
BA_ "GenSigTimeoutTime_ALL" SG_ 580 ADCU_RPA_DistROL 500;
BA_ "InvalidValue" SG_ 580 ADCU_RPA_DistRIR "FFh";
BA_ "GenSigStartValue" SG_ 580 ADCU_RPA_DistRIR 255;
BA_ "GenSigTimeoutTime_ALL" SG_ 580 ADCU_RPA_DistRIR 500;
BA_ "InvalidValue" SG_ 580 ADCU_RPA_DistROR "FFh";
BA_ "GenSigStartValue" SG_ 580 ADCU_RPA_DistROR 255;
BA_ "GenSigTimeoutTime_ALL" SG_ 580 ADCU_RPA_DistROR 500;
BA_ "InvalidValue" SG_ 580 ADCU_RPA_DistRSL "FFh";
BA_ "GenSigStartValue" SG_ 580 ADCU_RPA_DistRSL 255;
BA_ "GenSigTimeoutTime_ALL" SG_ 580 ADCU_RPA_DistRSL 500;
BA_ "InvalidValue" SG_ 580 ADCU_RPA_DistRSR "FFh";
BA_ "GenSigStartValue" SG_ 580 ADCU_RPA_DistRSR 255;
BA_ "GenSigTimeoutTime_ALL" SG_ 580 ADCU_RPA_DistRSR 500;
BA_ "GenSigTimeoutTime_ALL" SG_ 580 ADCU_RPA_ChimeReqRIL 500;
BA_ "GenSigTimeoutTime_ALL" SG_ 580 ADCU_RPA_ChimeReqROL 500;
BA_ "GenSigTimeoutTime_ALL" SG_ 580 ADCU_RPA_ChimeReqRIR 500;
BA_ "GenSigTimeoutTime_ALL" SG_ 580 ADCU_RPA_ChimeReqROR 500;
BA_ "GenSigTimeoutTime_ALL" SG_ 580 ADCU_RPA_ChimeReqRSL 500;
BA_ "GenSigTimeoutTime_ALL" SG_ 580 ADCU_RPA_ChimeReqRSR 500;
BA_ "GenSigTimeoutTime_ALL" SG_ 582 CRC_ADCU_PA_NSPA 500;
BA_ "InvalidValue" SG_ 582 ALIVE_ADCU_PA_NSPA "Fh";
BA_ "GenSigTimeoutTime_ALL" SG_ 582 ALIVE_ADCU_PA_NSPA 500;
BA_ "InvalidValue" SG_ 582 ADCU_NSPA_AlertFSL1 "7h";
BA_ "GenSigStartValue" SG_ 582 ADCU_NSPA_AlertFSL1 7;
BA_ "GenSigTimeoutTime_ALL" SG_ 582 ADCU_NSPA_AlertFSL1 500;
BA_ "GenSigSendType" SG_ 582 ADCU_NSPA_AlertFSL1 2;
BA_ "InvalidValue" SG_ 582 ADCU_NSPA_AlertFSL2 "7h";
BA_ "GenSigStartValue" SG_ 582 ADCU_NSPA_AlertFSL2 7;
BA_ "GenSigTimeoutTime_ALL" SG_ 582 ADCU_NSPA_AlertFSL2 500;
BA_ "GenSigSendType" SG_ 582 ADCU_NSPA_AlertFSL2 2;
BA_ "InvalidValue" SG_ 582 ADCU_NSPA_AlertFSR1 "7h";
BA_ "GenSigStartValue" SG_ 582 ADCU_NSPA_AlertFSR1 7;
BA_ "GenSigTimeoutTime_ALL" SG_ 582 ADCU_NSPA_AlertFSR1 500;
BA_ "GenSigSendType" SG_ 582 ADCU_NSPA_AlertFSR1 2;
BA_ "InvalidValue" SG_ 582 ADCU_NSPA_AlertFSR2 "7h";
BA_ "GenSigStartValue" SG_ 582 ADCU_NSPA_AlertFSR2 7;
BA_ "GenSigTimeoutTime_ALL" SG_ 582 ADCU_NSPA_AlertFSR2 500;
BA_ "GenSigSendType" SG_ 582 ADCU_NSPA_AlertFSR2 2;
BA_ "InvalidValue" SG_ 582 ADCU_NSPA_AlertRSL1 "7h";
BA_ "GenSigStartValue" SG_ 582 ADCU_NSPA_AlertRSL1 7;
BA_ "GenSigTimeoutTime_ALL" SG_ 582 ADCU_NSPA_AlertRSL1 500;
BA_ "GenSigSendType" SG_ 582 ADCU_NSPA_AlertRSL1 2;
BA_ "InvalidValue" SG_ 582 ADCU_NSPA_AlertRSL2 "7h";
BA_ "GenSigStartValue" SG_ 582 ADCU_NSPA_AlertRSL2 7;
BA_ "GenSigTimeoutTime_ALL" SG_ 582 ADCU_NSPA_AlertRSL2 500;
BA_ "GenSigSendType" SG_ 582 ADCU_NSPA_AlertRSL2 2;
BA_ "InvalidValue" SG_ 582 ADCU_NSPA_AlertRSR1 "7h";
BA_ "GenSigStartValue" SG_ 582 ADCU_NSPA_AlertRSR1 7;
BA_ "GenSigTimeoutTime_ALL" SG_ 582 ADCU_NSPA_AlertRSR1 500;
BA_ "GenSigSendType" SG_ 582 ADCU_NSPA_AlertRSR1 2;
BA_ "InvalidValue" SG_ 582 ADCU_NSPA_AlertRSR2 "7h";
BA_ "GenSigStartValue" SG_ 582 ADCU_NSPA_AlertRSR2 7;
BA_ "GenSigTimeoutTime_ALL" SG_ 582 ADCU_NSPA_AlertRSR2 500;
BA_ "GenSigSendType" SG_ 582 ADCU_NSPA_AlertRSR2 2;
BA_ "InvalidValue" SG_ 582 ADCU_NSPA_DistFSL1 "FFh";
BA_ "GenSigStartValue" SG_ 582 ADCU_NSPA_DistFSL1 255;
BA_ "GenSigTimeoutTime_ALL" SG_ 582 ADCU_NSPA_DistFSL1 500;
BA_ "InvalidValue" SG_ 582 ADCU_NSPA_DistFSL2 "FFh";
BA_ "GenSigStartValue" SG_ 582 ADCU_NSPA_DistFSL2 255;
BA_ "GenSigTimeoutTime_ALL" SG_ 582 ADCU_NSPA_DistFSL2 500;
BA_ "InvalidValue" SG_ 582 ADCU_NSPA_DistFSR1 "FFh";
BA_ "GenSigStartValue" SG_ 582 ADCU_NSPA_DistFSR1 255;
BA_ "GenSigTimeoutTime_ALL" SG_ 582 ADCU_NSPA_DistFSR1 500;
BA_ "InvalidValue" SG_ 582 ADCU_NSPA_DistFSR2 "FFh";
BA_ "GenSigStartValue" SG_ 582 ADCU_NSPA_DistFSR2 255;
BA_ "GenSigTimeoutTime_ALL" SG_ 582 ADCU_NSPA_DistFSR2 500;
BA_ "InvalidValue" SG_ 582 ADCU_NSPA_DistRSL1 "FFh";
BA_ "GenSigStartValue" SG_ 582 ADCU_NSPA_DistRSL1 255;
BA_ "GenSigTimeoutTime_ALL" SG_ 582 ADCU_NSPA_DistRSL1 500;
BA_ "InvalidValue" SG_ 582 ADCU_NSPA_DistRSL2 "FFh";
BA_ "GenSigStartValue" SG_ 582 ADCU_NSPA_DistRSL2 255;
BA_ "GenSigTimeoutTime_ALL" SG_ 582 ADCU_NSPA_DistRSL2 500;
BA_ "InvalidValue" SG_ 582 ADCU_NSPA_DistRSR1 "FFh";
BA_ "GenSigStartValue" SG_ 582 ADCU_NSPA_DistRSR1 255;
BA_ "GenSigTimeoutTime_ALL" SG_ 582 ADCU_NSPA_DistRSR1 500;
BA_ "InvalidValue" SG_ 582 ADCU_NSPA_DistRSR2 "FFh";
BA_ "GenSigStartValue" SG_ 582 ADCU_NSPA_DistRSR2 255;
BA_ "GenSigTimeoutTime_ALL" SG_ 582 ADCU_NSPA_DistRSR2 500;
BA_ "GenSigTimeoutTime_ALL" SG_ 582 ADCU_NSPA_ChimeReqFSL1 500;
BA_ "GenSigTimeoutTime_ALL" SG_ 582 ADCU_NSPA_ChimeReqFSL2 500;
BA_ "GenSigTimeoutTime_ALL" SG_ 582 ADCU_NSPA_ChimeReqFSR1 500;
BA_ "GenSigTimeoutTime_ALL" SG_ 582 ADCU_NSPA_ChimeReqFSR2 500;
BA_ "GenSigTimeoutTime_ALL" SG_ 582 ADCU_NSPA_ChimeReqRSL1 500;
BA_ "GenSigTimeoutTime_ALL" SG_ 582 ADCU_NSPA_ChimeReqRSL2 500;
BA_ "GenSigTimeoutTime_ALL" SG_ 582 ADCU_NSPA_ChimeReqRSR1 500;
BA_ "GenSigTimeoutTime_ALL" SG_ 582 ADCU_NSPA_ChimeReqRSR2 500;
BA_ "GenSigTimeoutTime_ALL" SG_ 583 CRC_ADCU_BRAKE_HMI 500;
BA_ "InvalidValue" SG_ 583 ALIVE_ADCU_BRAKE_HMI "Fh";
BA_ "GenSigTimeoutTime_ALL" SG_ 583 ALIVE_ADCU_BRAKE_HMI 500;
BA_ "InvalidValue" SG_ 583 ADCU_RAEB_State "7h";
BA_ "InvalidValue" SG_ 583 ADCU_RAEB_Check "7h";
BA_ "InvalidValue" SG_ 583 ADCU_RAEB_Mode_Feed "3h";
BA_ "GenSigStartValue" SG_ 583 ADCU_RAEB_Mode_Feed 3;
BA_ "InvalidValue" SG_ 583 ADCU_RAEB_Warning "7h";
BA_ "GenSigSendType" SG_ 583 ADCU_RAEB_Warning 2;
BA_ "InvalidValue" SG_ 583 ADCU_RAEB_BrakeReq_Source "7h";
BA_ "GenSigTimeoutTime_ALL" SG_ 583 ADCU_RAEB_BrakeReq_Source 1000;
BA_ "GenSigSendType" SG_ 583 ADCU_RAEB_BrakeReq_Source 2;
BA_ "InvalidValue" SG_ 605 ADCU_Driving_Parking_state "0h";
BA_ "GenSigTimeoutTime_ALL" SG_ 605 ADCU_Driving_Parking_state 100;
BA_ "GenSigTimeoutTime_ALL" SG_ 664 CRC_ADCU_ADASFeat_InputState 250;
BA_ "InvalidValue" SG_ 664 ALIVE_ADCU_ADASFeat_InputState "Fh";
BA_ "GenSigTimeoutTime_ALL" SG_ 664 ALIVE_ADCU_ADASFeat_InputState 250;
BA_ "InvalidValue" SG_ 664 ADCU_ACC_Input_State "3h";
BA_ "GenSigTimeoutTime_ALL" SG_ 664 ADCU_ACC_Input_State 250;
BA_ "InvalidValue" SG_ 664 ADCU_TSR_Input_State "3h";
BA_ "GenSigTimeoutTime_ALL" SG_ 664 ADCU_TSR_Input_State 250;
BA_ "InvalidValue" SG_ 664 ADCU_ESA_Input_State "3h";
BA_ "GenSigTimeoutTime_ALL" SG_ 664 ADCU_ESA_Input_State 250;
BA_ "GenSigTimeoutTime_ALL" SG_ 563 CRC_ADCU_MHU_Sentry_Mode 250;
BA_ "InvalidValue" SG_ 563 ALIVE_ADCU_MHU_Sentry_Mode "Fh";
BA_ "GenSigTimeoutTime_ALL" SG_ 563 ALIVE_ADCU_MHU_Sentry_Mode 250;
BA_ "InvalidValue" SG_ 563 ADAS_Sentry_Mode_Stat "3h";
BA_ "GenSigTimeoutTime_ALL" SG_ 563 ADAS_Sentry_Mode_Stat 250;
BA_ "GenSigTimeoutTime_ALL" SG_ 705 CRC_ADCU_MHU_DNSRequest 250;
BA_ "InvalidValue" SG_ 705 ALIVE_ADCU_MHU_DNSRequest "Fh";
BA_ "GenSigTimeoutTime_ALL" SG_ 705 ALIVE_ADCU_MHU_DNSRequest 250;
BA_ "InvalidValue" SG_ 705 ADCU_MHU_DNS_Warning "3h";
BA_ "GenSigTimeoutTime_ALL" SG_ 705 ADCU_MHU_DNS_Warning 250;
BA_ "GenSigTimeoutTime_ALL" SG_ 586 CRC_ADCU_ACPE_CMD 1000;
BA_ "InvalidValue" SG_ 586 ALIVE_ADCU_ACPE_CMD "Fh";
BA_ "GenSigTimeoutTime_ALL" SG_ 586 ALIVE_ADCU_ACPE_CMD 1000;
BA_ "InvalidValue" SG_ 586 ADCU_ACPE_PowerCommand "7h";
BA_ "GenSigStartValue" SG_ 586 ADCU_ACPE_PowerCommand 7;
BA_ "GenSigTimeoutTime_ALL" SG_ 586 ADCU_ACPE_PowerCommand 1000;
BA_ "GenSigSendType" SG_ 586 ADCU_ACPE_PowerCommand 2;
BA_ "InvalidValue" SG_ 586 ADCU_ACPE_BrakeCommand "3h";
BA_ "GenSigStartValue" SG_ 586 ADCU_ACPE_BrakeCommand 3;
BA_ "GenSigTimeoutTime_ALL" SG_ 586 ADCU_ACPE_BrakeCommand 1000;
BA_ "GenSigSendType" SG_ 586 ADCU_ACPE_BrakeCommand 2;
BA_ "InvalidValue" SG_ 586 ADCU_ACPE_Available "3h";
BA_ "GenSigStartValue" SG_ 586 ADCU_ACPE_Available 3;
BA_ "GenSigTimeoutTime_ALL" SG_ 586 ADCU_ACPE_Available 1000;
BA_ "GenSigSendType" SG_ 586 ADCU_ACPE_Available 2;
BA_ "GenSigTimeoutTime_ALL" SG_ 586 ADCU_ACPE_FuncActive 1000;
BA_ "GenSigSendType" SG_ 586 ADCU_ACPE_FuncActive 2;
BA_ "InvalidValue" SG_ 586 ADCU_ACPE_HMICommand "7h";
BA_ "GenSigStartValue" SG_ 586 ADCU_ACPE_HMICommand 7;
BA_ "GenSigTimeoutTime_ALL" SG_ 586 ADCU_ACPE_HMICommand 1000;
BA_ "GenSigSendType" SG_ 586 ADCU_ACPE_HMICommand 2;
BA_ "InvalidValue" SG_ 586 ADCU_ACPE_State "7h";
BA_ "GenSigStartValue" SG_ 586 ADCU_ACPE_State 7;
BA_ "GenSigTimeoutTime_ALL" SG_ 586 ADCU_ACPE_State 1000;
BA_ "InvalidValue" SG_ 586 ADCU_ACPE_Setting_Feed "3h";
BA_ "GenSigStartValue" SG_ 586 ADCU_ACPE_Setting_Feed 3;
BA_ "GenSigTimeoutTime_ALL" SG_ 586 ADCU_ACPE_Setting_Feed 1000;
BA_ "InvalidValue" SG_ 586 ADCU_ACPE_Sens_Feed "3h";
BA_ "GenSigStartValue" SG_ 586 ADCU_ACPE_Sens_Feed 3;
BA_ "GenSigTimeoutTime_ALL" SG_ 586 ADCU_ACPE_Sens_Feed 1000;
BA_ "InvalidValue" SG_ 586 ADCU_ACPE_Check "7h";
BA_ "GenSigTimeoutTime_ALL" SG_ 586 ADCU_ACPE_Check 1000;
BA_ "InvalidValue" SG_ 586 ADCU_ACPE_TargetDeccel "FFh";
BA_ "GenSigTimeoutTime_ALL" SG_ 586 ADCU_ACPE_TargetDeccel 1000;
BA_ "InvalidValue" SG_ 586 ACPE_FrontControler_Operate "7h";
BA_ "GenSigTimeoutTime_ALL" SG_ 586 ACPE_FrontControler_Operate 1000;
BA_ "InvalidValue" SG_ 586 ACPE_RearControler_Operate "7h";
BA_ "GenSigTimeoutTime_ALL" SG_ 586 ACPE_RearControler_Operate 1000;
BA_ "GenSigTimeoutTime_ALL" SG_ 588 CRC_ADCU_SVM_STATUS 2500;
BA_ "InvalidValue" SG_ 588 ALIVE_ADCU_SVM_STATUS "Fh";
BA_ "GenSigTimeoutTime_ALL" SG_ 588 ALIVE_ADCU_SVM_STATUS 2500;
BA_ "InvalidValue" SG_ 588 ADCU_SVM_Guideline_Feed "3h";
BA_ "GenSigStartValue" SG_ 588 ADCU_SVM_Guideline_Feed 3;
BA_ "GenSigTimeoutTime_ALL" SG_ 588 ADCU_SVM_Guideline_Feed 2500;
BA_ "GenSigSendType" SG_ 588 ADCU_SVM_Guideline_Feed 2;
BA_ "InvalidValue" SG_ 588 ADCU_SVM_ObjOverlay_Feed "3h";
BA_ "GenSigStartValue" SG_ 588 ADCU_SVM_ObjOverlay_Feed 3;
BA_ "GenSigTimeoutTime_ALL" SG_ 588 ADCU_SVM_ObjOverlay_Feed 2500;
BA_ "GenSigSendType" SG_ 588 ADCU_SVM_ObjOverlay_Feed 2;
BA_ "InvalidValue" SG_ 588 ADCU_SVM_TrailerGuideline_Feed "3h";
BA_ "GenSigStartValue" SG_ 588 ADCU_SVM_TrailerGuideline_Feed 3;
BA_ "GenSigTimeoutTime_ALL" SG_ 588 ADCU_SVM_TrailerGuideline_Feed 2500;
BA_ "GenSigSendType" SG_ 588 ADCU_SVM_TrailerGuideline_Feed 2;
BA_ "InvalidValue" SG_ 588 ADCU_SVM_MaxDoorOverlay_Feed "3h";
BA_ "GenSigStartValue" SG_ 588 ADCU_SVM_MaxDoorOverlay_Feed 3;
BA_ "GenSigTimeoutTime_ALL" SG_ 588 ADCU_SVM_MaxDoorOverlay_Feed 2500;
BA_ "GenSigSendType" SG_ 588 ADCU_SVM_MaxDoorOverlay_Feed 2;
BA_ "InvalidValue" SG_ 588 ADCU_SVM_Transparency_Feed "3h";
BA_ "GenSigStartValue" SG_ 588 ADCU_SVM_Transparency_Feed 3;
BA_ "GenSigTimeoutTime_ALL" SG_ 588 ADCU_SVM_Transparency_Feed 2500;
BA_ "GenSigSendType" SG_ 588 ADCU_SVM_Transparency_Feed 2;
BA_ "InvalidValue" SG_ 588 ADCU_SVM_BlindSpotView_Feed "3h";
BA_ "GenSigStartValue" SG_ 588 ADCU_SVM_BlindSpotView_Feed 3;
BA_ "GenSigTimeoutTime_ALL" SG_ 588 ADCU_SVM_BlindSpotView_Feed 2500;
BA_ "GenSigSendType" SG_ 588 ADCU_SVM_BlindSpotView_Feed 2;
BA_ "InvalidValue" SG_ 588 ADCU_SVM_BlindspotView "3h";
BA_ "GenSigStartValue" SG_ 588 ADCU_SVM_BlindspotView 3;
BA_ "GenSigTimeoutTime_ALL" SG_ 588 ADCU_SVM_BlindspotView 2500;
BA_ "GenSigSendType" SG_ 588 ADCU_SVM_BlindspotView 2;
BA_ "InvalidValue" SG_ 588 ADCU_SVM_ShowAVMReq "7h";
BA_ "GenSigStartValue" SG_ 588 ADCU_SVM_ShowAVMReq 7;
BA_ "GenSigTimeoutTime_ALL" SG_ 588 ADCU_SVM_ShowAVMReq 2500;
BA_ "GenSigSendType" SG_ 588 ADCU_SVM_ShowAVMReq 2;
BA_ "InvalidValue" SG_ 588 ADCU_SVM_View_Status "1Fh";
BA_ "GenSigStartValue" SG_ 588 ADCU_SVM_View_Status 31;
BA_ "GenSigTimeoutTime_ALL" SG_ 588 ADCU_SVM_View_Status 2500;
BA_ "GenSigSendType" SG_ 588 ADCU_SVM_View_Status 2;
BA_ "InvalidValue" SG_ 588 ADCU_SVM_Status_Signal "7h";
BA_ "GenSigStartValue" SG_ 588 ADCU_SVM_Status_Signal 7;
BA_ "GenSigTimeoutTime_ALL" SG_ 588 ADCU_SVM_Status_Signal 2500;
BA_ "GenSigSendType" SG_ 588 ADCU_SVM_Status_Signal 2;
BA_ "InvalidValue" SG_ 588 ADCU_Early_RVC_Status_Signal "7h";
BA_ "GenSigStartValue" SG_ 588 ADCU_Early_RVC_Status_Signal 7;
BA_ "GenSigTimeoutTime_ALL" SG_ 588 ADCU_Early_RVC_Status_Signal 2500;
BA_ "GenSigSendType" SG_ 588 ADCU_Early_RVC_Status_Signal 2;
BA_ "GenSigTimeoutTime_ALL" SG_ 602 CRC_ADCU_SYS_HEALTH 2500;
BA_ "InvalidValue" SG_ 602 ALIVE_ADCU_SYS_HEALTH "Fh";
BA_ "GenSigTimeoutTime_ALL" SG_ 602 ALIVE_ADCU_SYS_HEALTH 2500;
BA_ "InvalidValue" SG_ 602 ADCU_SVM_FrontCam_Check "3h";
BA_ "GenSigTimeoutTime_ALL" SG_ 602 ADCU_SVM_FrontCam_Check 2500;
BA_ "InvalidValue" SG_ 602 ADCU_SVM_RearCam_Check "3h";
BA_ "GenSigTimeoutTime_ALL" SG_ 602 ADCU_SVM_RearCam_Check 2500;
BA_ "InvalidValue" SG_ 602 ADCU_SVM_LeftCamera_Check "3h";
BA_ "GenSigTimeoutTime_ALL" SG_ 602 ADCU_SVM_LeftCamera_Check 2500;
BA_ "InvalidValue" SG_ 602 ADCU_SVM_RightCamera_Check "3h";
BA_ "GenSigTimeoutTime_ALL" SG_ 602 ADCU_SVM_RightCamera_Check 2500;
BA_ "InvalidValue" SG_ 602 ADCU_TopRearCamera_Check "3h";
BA_ "GenSigTimeoutTime_ALL" SG_ 602 ADCU_TopRearCamera_Check 2500;
BA_ "InvalidValue" SG_ 602 ADCU_USS_FIL_Check "3h";
BA_ "GenSigTimeoutTime_ALL" SG_ 602 ADCU_USS_FIL_Check 2500;
BA_ "InvalidValue" SG_ 602 ADCU_USS_FIR_Check "3h";
BA_ "GenSigTimeoutTime_ALL" SG_ 602 ADCU_USS_FIR_Check 2500;
BA_ "InvalidValue" SG_ 602 ADCU_USS_FOL_Check "3h";
BA_ "GenSigTimeoutTime_ALL" SG_ 602 ADCU_USS_FOL_Check 2500;
BA_ "InvalidValue" SG_ 602 ADCU_USS_FOR_Check "3h";
BA_ "GenSigTimeoutTime_ALL" SG_ 602 ADCU_USS_FOR_Check 2500;
BA_ "InvalidValue" SG_ 602 ADCU_USS_FSL_Check "3h";
BA_ "GenSigTimeoutTime_ALL" SG_ 602 ADCU_USS_FSL_Check 2500;
BA_ "InvalidValue" SG_ 602 ADCU_USS_FSR_Check "3h";
BA_ "GenSigTimeoutTime_ALL" SG_ 602 ADCU_USS_FSR_Check 2500;
BA_ "InvalidValue" SG_ 602 ADCU_USS_RIL_Check "3h";
BA_ "GenSigTimeoutTime_ALL" SG_ 602 ADCU_USS_RIL_Check 2500;
BA_ "InvalidValue" SG_ 602 ADCU_USS_RIR_Check "3h";
BA_ "GenSigTimeoutTime_ALL" SG_ 602 ADCU_USS_RIR_Check 2500;
BA_ "InvalidValue" SG_ 602 ADCU_USS_ROL_Check "3h";
BA_ "GenSigTimeoutTime_ALL" SG_ 602 ADCU_USS_ROL_Check 2500;
BA_ "InvalidValue" SG_ 602 ADCU_USS_ROR_Check "3h";
BA_ "GenSigTimeoutTime_ALL" SG_ 602 ADCU_USS_ROR_Check 2500;
BA_ "InvalidValue" SG_ 602 ADCU_USS_RSL_Check "3h";
BA_ "GenSigTimeoutTime_ALL" SG_ 602 ADCU_USS_RSL_Check 2500;
BA_ "InvalidValue" SG_ 602 ADCU_USS_RSR_Check "3h";
BA_ "GenSigTimeoutTime_ALL" SG_ 602 ADCU_USS_RSR_Check 2500;
BA_ "InvalidValue" SG_ 602 ADCU_SVM_GMSL_Check "3h";
BA_ "GenSigTimeoutTime_ALL" SG_ 602 ADCU_SVM_GMSL_Check 2500;
BA_ "InvalidValue" SG_ 602 ADCU_OS_Check "7h";
BA_ "GenSigTimeoutTime_ALL" SG_ 602 ADCU_OS_Check 2500;
BA_ "GenSigTimeoutTime_ALL" SG_ 602 ADCU_ERROR_CODE 2500;
BA_ "InvalidValue" SG_ 602 ADCU_ErrFCAM_SnSr_Diag "0h";
BA_ "GenSigTimeoutTime_ALL" SG_ 602 ADCU_ErrFCAM_SnSr_Diag 2500;
BA_ "InvalidValue" SG_ 602 ADCU_ErrFCAM_Feature_Diag "0h";
BA_ "GenSigTimeoutTime_ALL" SG_ 602 ADCU_ErrFCAM_Feature_Diag 2500;
BA_ "InvalidValue" SG_ 549 ADCU_TLD_state "3h";
BA_ "GenSigTimeoutTime_ALL" SG_ 549 ADCU_TLD_state 100;
BA_ "InvalidValue" SG_ 549 ADCU_TLD_light_color "0h";
BA_ "GenSigTimeoutTime_ALL" SG_ 549 ADCU_TLD_light_color 100;
BA_ "InvalidValue" SG_ 549 ADCU_TLD_light_color_confidence "0h";
BA_ "InvalidValue" SG_ 549 ADCU_TLD_light_lane "0h";
BA_ "GenSigTimeoutTime_ALL" SG_ 549 ADCU_TLD_light_lane 100;
BA_ "GenSigTimeoutTime_ALL" SG_ 647 CRC_ADCU_MHU_VAP_Status 200;
BA_ "InvalidValue" SG_ 647 ALIVE_ADCU_MHU_VAP_Status "Fh";
BA_ "GenSigTimeoutTime_ALL" SG_ 647 ALIVE_ADCU_MHU_VAP_Status 200;
BA_ "InvalidValue" SG_ 647 ADCU_VAP_Mode "Fh";
BA_ "GenSigTimeoutTime_ALL" SG_ 647 ADCU_VAP_Mode 200;
BA_ "InvalidValue" SG_ 647 ADCU_VAP_ModeExt "Fh";
BA_ "GenSigTimeoutTime_ALL" SG_ 647 ADCU_VAP_ModeExt 200;
BA_ "InvalidValue" SG_ 647 ADCU_VAP_Status "Fh";
BA_ "GenSigTimeoutTime_ALL" SG_ 647 ADCU_VAP_Status 200;
BA_ "InvalidValue" SG_ 647 ADCU_VAP_StatusExt "Fh";
BA_ "GenSigTimeoutTime_ALL" SG_ 647 ADCU_VAP_StatusExt 200;
BA_ "InvalidValue" SG_ 647 ADCU_VAP_CancelCode "FFh";
BA_ "GenSigTimeoutTime_ALL" SG_ 647 ADCU_VAP_CancelCode 200;
BA_ "InvalidValue" SG_ 647 ADCU_VAP_SuspendCode "FFh";
BA_ "GenSigTimeoutTime_ALL" SG_ 647 ADCU_VAP_SuspendCode 200;
BA_ "InvalidValue" SG_ 647 ADCU_VAP_AbortCode "FFh";
BA_ "GenSigTimeoutTime_ALL" SG_ 647 ADCU_VAP_AbortCode 200;
BA_ "InvalidValue" SG_ 647 ADCU_VAP_ErrorCode "FFh";
BA_ "GenSigTimeoutTime_ALL" SG_ 647 ADCU_VAP_ErrorCode 200;
BA_ "GenSigTimeoutTime_ALL" SG_ 648 CRC_ADCU_MHU_VAP_ControlResp 100;
BA_ "InvalidValue" SG_ 648 ALIVE_ADCU_MHU_VAP_ControlResp "Fh";
BA_ "GenSigTimeoutTime_ALL" SG_ 648 ALIVE_ADCU_MHU_VAP_ControlResp 100;
BA_ "InvalidValue" SG_ 648 ADCU_MHU_VAP_SessionMode "Fh";
BA_ "GenSigTimeoutTime_ALL" SG_ 648 ADCU_MHU_VAP_SessionMode 100;
BA_ "InvalidValue" SG_ 648 ADCU_MHU_VAP_SessionState "Dh";
BA_ "GenSigTimeoutTime_ALL" SG_ 648 ADCU_MHU_VAP_SessionState 100;
BA_ "InvalidValue" SG_ 648 ADCU_MHU_VAP_SessionResp "Fh";
BA_ "GenSigTimeoutTime_ALL" SG_ 648 ADCU_MHU_VAP_SessionResp 100;
BA_ "InvalidValue" SG_ 648 ADCU_MHU_VAP_RejectCode "Fh";
BA_ "GenSigTimeoutTime_ALL" SG_ 648 ADCU_MHU_VAP_RejectCode 100;
BA_ "InvalidValue" SG_ 648 ADCU_MHU_VAP_SessionProgress "FFh";
BA_ "GenSigTimeoutTime_ALL" SG_ 648 ADCU_MHU_VAP_SessionProgress 100;
BA_ "InvalidValue" SG_ 648 ADCU_MHU_VAP_SessionDTS "FFh";
BA_ "GenSigTimeoutTime_ALL" SG_ 648 ADCU_MHU_VAP_SessionDTS 100;
BA_ "InvalidValue" SG_ 648 ADCU_MHU_VAP_SlotSuggestion "FFh";
BA_ "GenSigTimeoutTime_ALL" SG_ 648 ADCU_MHU_VAP_SlotSuggestion 100;
BA_ "InvalidValue" SG_ 648 ADCU_MHU_VAP_NoseDir "3h";
BA_ "GenSigTimeoutTime_ALL" SG_ 648 ADCU_MHU_VAP_NoseDir 100;
BA_ "InvalidValue" SG_ 648 ADCU_MHU_VAP_ParkAngle "0h";
BA_ "GenSigTimeoutTime_ALL" SG_ 648 ADCU_MHU_VAP_ParkAngle 100;
BA_ "InvalidValue" SG_ 648 ADCU_MHU_VAP_History_ParkIn "3h";
BA_ "GenSigTimeoutTime_ALL" SG_ 648 ADCU_MHU_VAP_History_ParkIn 100;
BA_ "InvalidValue" SG_ 648 ADCU_MHU_VAP_History_NoseDir "3h";
BA_ "GenSigTimeoutTime_ALL" SG_ 648 ADCU_MHU_VAP_History_NoseDir 100;
BA_ "InvalidValue" SG_ 648 ADCU_MHU_VAP_History_ParkAngle "0h";
BA_ "GenSigTimeoutTime_ALL" SG_ 648 ADCU_MHU_VAP_History_ParkAngle 100;
BA_ "InvalidValue" SG_ 648 ADCU_MHU_VAP_History_DropOff "3FFh";
BA_ "GenSigTimeoutTime_ALL" SG_ 648 ADCU_MHU_VAP_History_DropOff 100;
BA_ "InvalidValue" SG_ 648 ADCU_MHU_VAP_History_PathDist "3FFh";
BA_ "GenSigTimeoutTime_ALL" SG_ 648 ADCU_MHU_VAP_History_PathDist 100;
BA_ "InvalidValue" SG_ 648 ADCU_MHU_VAP_Available "1h";
BA_ "GenSigTimeoutTime_ALL" SG_ 648 ADCU_MHU_VAP_Available 100;
BA_ "GenSigTimeoutTime_ALL" SG_ 650 CRC_ADCU_TBOX_VAP_Status 100;
BA_ "InvalidValue" SG_ 650 ALIVE_ADCU_TBOX_VAP_Status "Fh";
BA_ "GenSigTimeoutTime_ALL" SG_ 650 ALIVE_ADCU_TBOX_VAP_Status 100;
BA_ "InvalidValue" SG_ 650 ADCU_TBOX_VAP_SessionMode "Fh";
BA_ "GenSigTimeoutTime_ALL" SG_ 650 ADCU_TBOX_VAP_SessionMode 100;
BA_ "InvalidValue" SG_ 650 ADCU_TBOX_VAP_SessionState "Dh";
BA_ "GenSigTimeoutTime_ALL" SG_ 650 ADCU_TBOX_VAP_SessionState 100;
BA_ "InvalidValue" SG_ 650 ADCU_TBOX_VAP_SessionResp "Fh";
BA_ "GenSigTimeoutTime_ALL" SG_ 650 ADCU_TBOX_VAP_SessionResp 100;
BA_ "InvalidValue" SG_ 650 ADCU_TBOX_VAP_RejectCode "Fh";
BA_ "GenSigTimeoutTime_ALL" SG_ 650 ADCU_TBOX_VAP_RejectCode 100;
BA_ "InvalidValue" SG_ 650 ADCU_TBOX_VAP_SessionProgress "FFh";
BA_ "GenSigTimeoutTime_ALL" SG_ 650 ADCU_TBOX_VAP_SessionProgress 100;
BA_ "InvalidValue" SG_ 650 ADCU_TBOX_VAP_SessionDTS "FFh";
BA_ "GenSigTimeoutTime_ALL" SG_ 650 ADCU_TBOX_VAP_SessionDTS 100;
BA_ "InvalidValue" SG_ 650 ADCU_TBOX_VAP_SlotSuggestion "FFh";
BA_ "GenSigTimeoutTime_ALL" SG_ 650 ADCU_TBOX_VAP_SlotSuggestion 100;
BA_ "InvalidValue" SG_ 650 ADCU_TBOX_VAP_NoseDir "3h";
BA_ "GenSigTimeoutTime_ALL" SG_ 650 ADCU_TBOX_VAP_NoseDir 100;
BA_ "InvalidValue" SG_ 650 ADCU_TBOX_VAP_ParkAngle "0h";
BA_ "GenSigTimeoutTime_ALL" SG_ 650 ADCU_TBOX_VAP_ParkAngle 100;
BA_ "InvalidValue" SG_ 650 ADCU_TBOX_VAP_History_ParkIn "3h";
BA_ "GenSigTimeoutTime_ALL" SG_ 650 ADCU_TBOX_VAP_History_ParkIn 100;
BA_ "InvalidValue" SG_ 650 ADCU_TBOX_VAP_History_NoseDir "3h";
BA_ "GenSigTimeoutTime_ALL" SG_ 650 ADCU_TBOX_VAP_History_NoseDir 100;
BA_ "InvalidValue" SG_ 650 ADCU_TBOX_VAP_History_ParkAngle "0h";
BA_ "GenSigTimeoutTime_ALL" SG_ 650 ADCU_TBOX_VAP_History_ParkAngle 100;
BA_ "InvalidValue" SG_ 650 ADCU_TBOX_VAP_Available "1h";
BA_ "GenSigTimeoutTime_ALL" SG_ 650 ADCU_TBOX_VAP_Available 100;
BA_ "GenSigTimeoutTime_ALL" SG_ 652 CRC_ADCU_MHU_VPARK 1000;
BA_ "InvalidValue" SG_ 652 ALIVE_ADCU_MHU_VPARK "Fh";
BA_ "GenSigTimeoutTime_ALL" SG_ 652 ALIVE_ADCU_MHU_VPARK 1000;
BA_ "GenSigTimeoutTime_ALL" SG_ 652 ADCU_MHU_VPARK_MHU_Txt1_Notif 1000;
BA_ "GenSigTimeoutTime_ALL" SG_ 652 ADCU_MHU_VPARK_MHU_Txt2_Notif 1000;
BA_ "GenSigTimeoutTime_ALL" SG_ 652 ADCU_MHU_VPARK_MHU_Txt3_Notif 1000;
BA_ "GenSigTimeoutTime_ALL" SG_ 652 ADCU_MHU_VPARK_MHU_Txt4_Notif 1000;
BA_ "GenSigTimeoutTime_ALL" SG_ 652 ADCU_MHU_VPARK_CAPP_Txt1_Notif 1000;
BA_ "GenSigTimeoutTime_ALL" SG_ 652 ADCU_MHU_VPARK_CAPP_Txt2_Notif 1000;
BA_ "GenSigTimeoutTime_ALL" SG_ 652 ADCU_MHU_VPARK_CAPP_Txt3_Notif 1000;
BA_ "GenSigTimeoutTime_ALL" SG_ 652 ADCU_MHU_VPARK_CAPP_Txt4_Notif 1000;
BA_ "GenSigTimeoutTime_ALL" SG_ 913 CRC_ADCU_TO_SRR_Front 200;
BA_ "InvalidValue" SG_ 913 ALIVE_ADCU_TO_SRR_Front "Fh";
BA_ "GenSigTimeoutTime_ALL" SG_ 913 ALIVE_ADCU_TO_SRR_Front 200;
BA_ "InvalidValue" SG_ 913 ADCU_TO_SRR_Front_DEFAULT "0h";
BA_ "GenSigTimeoutTime_ALL" SG_ 913 ADCU_TO_SRR_Front_DEFAULT 1000;
BA_ "GenSigTimeoutTime_ALL" SG_ 914 CRC_ADCU_TO_SRR_Rear 200;
BA_ "InvalidValue" SG_ 914 ALIVE_AADCU_TO_SRR_Rear "Fh";
BA_ "GenSigTimeoutTime_ALL" SG_ 914 ALIVE_AADCU_TO_SRR_Rear 200;
BA_ "InvalidValue" SG_ 914 ADCU_TO_SRR_Rear_DEFAULT "0h";
BA_ "GenSigTimeoutTime_ALL" SG_ 914 ADCU_TO_SRR_Rear_DEFAULT 1000;
BA_ "GenSigTimeoutTime_ALL" SG_ 1041 CRC_ADCU_DCM 200;
BA_ "InvalidValue" SG_ 1041 ALIVE_ADCU_DCM "Fh";
BA_ "GenSigTimeoutTime_ALL" SG_ 1041 ALIVE_ADCU_DCM 200;
BA_ "InvalidValue" SG_ 1041 ADCU_DCM_Status "0h";
BA_ "GenSigTimeoutTime_ALL" SG_ 1041 ADCU_DCM_Status 200;
BA_ "InvalidValue" SG_ 1041 ADCU_DashCam_Status "3h";
VAL_ 1866 FCAM_Arbitration_Log_Result 0 "NA" 1 "AACC" 2 "AEB" 3 "FCTB" 4 "ACPE" 5 "Reserved" 6 "Reserved" 7 "Reserved" 8 "Reserved" 9 "Reserved" 10 "Reserved" 11 "Reserved" 12 "Reserved" 13 "Reserved" 14 "Reserved" 15 "Invalid" ;
VAL_ 1866 FCAM_Arbitration_Lat_Result 0 "NA" 1 "LCC" 2 "NOP" 3 "HWA_L2+" 4 "LKA" 5 "LKA" 6 "ELKA" 7 "ESA" 8 "Reserved" 9 "Reserved" 10 "Reserved" 11 "Reserved" 12 "Reserved" 13 "Reserved" 14 "Reserved" 15 "Invalid" ;
VAL_ 1866 FCAM_Arbi_Fb 0 "state 0" 1 "state 1" 2 "state 2" 3 "state 3" 4 "state 4" 5 "state 5" 6 "state 6" 7 "state 7" 8 "state 8" 9 "state 9" 10 "state 10" 11 "state 11" 12 "state 12" 13 "state 13" 14 "state 14" 15 "state 15" ;
VAL_ 1866 FCAM_Acore_Diag 0 "diag 0" 1 "diag 1" 2 "diag 2" 3 "diag 3" 4 "diag 4" 5 "diag 5" 6 "diag 6" 7 "diag 7" 8 "diag 8" 9 "diag 9" 10 "diag 10" 11 "diag 11" 12 "diag 12" 13 "diag 13" 14 "diag 14" 15 "diag 15" ;
VAL_ 1866 FCAM_Rcore_Diag 0 "diag 0" 1 "diag 1" 2 "diag 2" 3 "diag 3" 4 "diag 4" 5 "diag 5" 6 "diag 6" 7 "diag 7" 8 "diag 8" 9 "diag 9" 10 "diag 10" 11 "diag 11" 12 "diag 12" 13 "diag 13" 14 "diag 14" 15 "diag 15" ;
VAL_ 1866 FCAM_Feature_Diag 0 "diag 0" 1 "diag 1" 2 "diag 2" 3 "diag 3" 4 "diag 4" 5 "diag 5" 6 "diag 6" 7 "diag 7" 8 "diag 8" 9 "diag 9" 10 "diag 10" 11 "diag 11" 12 "diag 12" 13 "diag 13" 14 "diag 14" 15 "diag 15" ;
VAL_ 1866 FCAM_ErrFCAM_SnSr_Diag 0 "diag 0" 1 "diag 1" 2 "diag 2" 3 "diag 3" 4 "diag 4" 5 "diag 5" 6 "diag 6" 7 "diag 7" 8 "diag 8" 9 "diag 9" 10 "diag 10" 11 "diag 11" 12 "diag 12" 13 "diag 13" 14 "diag 14" 15 "diag 15" ;
VAL_ 1866 FCAM_ErrFCAM_Feature_Diag 0 "diag 0" 1 "diag 1" 2 "diag 2" 3 "diag 3" 4 "diag 4" 5 "diag 5" 6 "diag 6" 7 "diag 7" 8 "diag 8" 9 "diag 9" 10 "diag 10" 11 "diag 11" 12 "diag 12" 13 "diag 13" 14 "diag 14" 15 "diag 15" ;
VAL_ 1866 FCAM_AACC_Arbitrator_Result 0 "No Control Command Output" 1 "Output Control Command" ;
VAL_ 1866 FCAM_AEB_Arbitrator_Result 0 "No Control Command Output" 1 "Output Control Command" ;
VAL_ 1866 FCAM_FCTB_Arbitrator_Result 0 "No Control Command Output" 1 "Output Control Command" ;
VAL_ 1866 FCAM_ACPE_Arbitrator_Result 0 "No Control Command Output" 1 "Output Control Command" ;
VAL_ 1866 FCAM_LCC_Arbitrator_Result 0 "No Control Command Output" 1 "Output Control Command" ;
VAL_ 1866 FCAM_NOP_Arbitrator_Result 0 "No Control Command Output" 1 "Output Control Command" ;
VAL_ 1866 FCAM_HWAPlus_Arbitrator_Result 0 "No Control Command Output" 1 "Output Control Command" ;
VAL_ 1866 FCAM_LKA_Arbitrator_Result 0 "No Control Command Output" 1 "Output Control Command" ;
VAL_ 1866 FCAM_ELKA_Arbitrator_Result 0 "No Control Command Output" 1 "Output Control Command" ;
VAL_ 1866 FCAM_ESA_Arbitrator_Result 0 "No Control Command Output" 1 "Output Control Command" ;
VAL_ 1866 FCAM_Arbitrator_Reserve_1 0 "No Control Command Output" 1 "Output Control Command" ;
VAL_ 1866 FCAM_Arbitrator_Reserve_2 0 "No Control Command Output" 1 "Output Control Command" ;
VAL_ 656 FCAM_ADCU_NOPHWAPlus_ClusterFaul 0 "no failure" 1 "failure" 3 "invalid" ;
VAL_ 468 MRR_check 0 "Available" 1 "Temporarily not available" 2 "Permanently not available" ;
VAL_ 468 MRR_Radar_Cal_Status 0 "No Calib" 1 "Calib OK" ;
VAL_ 468 MRR_Radar_Block_Status 0 "No Block" 1 "Blocked" ;
VAL_ 468 MRR_Radar_StaticCal_Status 0 "Calibration is in progress" 1 "The absolute value of calibration angle is greater than 6 degrees" ;
VAL_ 634 MRR_TimeSynchronization_Status 0 "Sync successful" 1 "failing" 2 "Syncing in progress" 3 "Unsync" 4 "Reserved" ;
VAL_ 635 SRR_RL_TimeSynchronization_Statu 0 "Sync successful" 1 "failing" 2 "Syncing in progress" 3 "Unsync" 4 "Reserved" ;
VAL_ 831 RL_Ob1j_DynProp 0 "moving" 1 "stationary" 2 "oncoming" 3 "stationary candidate" 4 "unknown" 5 "crossing stationary" 6 "crossing moving" 7 "stopped" ;
VAL_ 831 RL_Obj1_MeasState 0 "Deleted" 1 "New" 2 "Measured" 3 "Predicted" 4 "Deleted for merge" 5 "New from merge" 6 "Reserved" 7 "Invalid" ;
VAL_ 831 RL_Obj1_ProbOfExist 0 "Invalid" 1 "<25%" 2 " <50%" 3 "<75%" 4 "<90%" 5 "<99%" 6 "<99.9%" 7 "<=100%" ;
VAL_ 831 RL_Obj1j_Class 0 "unknown" 1 "big car" 2 " small car" 3 "two wheels" 4 "pedestrian" 5 "Reserved" 6 "Reserved" 7 "Invalid" ;
VAL_ 831 RL_Obj2_DynProp 0 "moving" 1 "stationary" 2 "oncoming" 3 "stationary candidate" 4 "unknown" 5 "crossing stationary" 6 "crossing moving" 7 "stopped" ;
VAL_ 831 RL_Obj2_MeasState 0 "Deleted" 1 "New" 2 "Measured" 3 "Predicted" 4 "Deleted for merge" 5 "New from merge" 6 "Reserved" 7 "Invalid" ;
VAL_ 831 RL_Obj2_ProbOfExist 0 "Invalid" 1 "<25%" 2 " <50%" 3 "<75%" 4 "<90%" 5 "<99%" 6 "<99.9%" 7 "<=100%" ;
VAL_ 831 RL_Obj2j_Class 0 "unknown" 1 "big car" 2 " small car" 3 "two wheels" 4 "pedestrian" 5 "Reserved" 6 "Reserved" 7 "Invalid" ;
VAL_ 831 RL_Obj3_DynProp 0 "moving" 1 "stationary" 2 "oncoming" 3 "stationary candidate" 4 "unknown" 5 "crossing stationary" 6 "crossing moving" 7 "stopped" ;
VAL_ 831 RL_Obj3_MeasState 0 "Deleted" 1 "New" 2 "Measured" 3 "Predicted" 4 "Deleted for merge" 5 "New from merge" 6 "Reserved" 7 "Invalid" ;
VAL_ 831 RL_Obj3_ProbOfExist 0 "Invalid" 1 "<25%" 2 " <50%" 3 "<75%" 4 "<90%" 5 "<99%" 6 "<99.9%" 7 "<=100%" ;
VAL_ 831 RL_Obj3j_Class 0 "unknown" 1 "big car" 2 " small car" 3 "two wheels" 4 "pedestrian" 5 "Reserved" 6 "Reserved" 7 "Invalid" ;
VAL_ 831 RL_Obj4_DynProp 0 "moving" 1 "stationary" 2 "oncoming" 3 "stationary candidate" 4 "unknown" 5 "crossing stationary" 6 "crossing moving" 7 "stopped" ;
VAL_ 831 RL_Obj4_MeasState 0 "Deleted" 1 "New" 2 "Measured" 3 "Predicted" 4 "Deleted for merge" 5 "New from merge" 6 "Reserved" 7 "Invalid" ;
VAL_ 831 RL_Obj4_ProbOfExist 0 "Invalid" 1 "<25%" 2 " <50%" 3 "<75%" 4 "<90%" 5 "<99%" 6 "<99.9%" 7 "<=100%" ;
VAL_ 831 RL_Obj4j_Class 0 "unknown" 1 "big car" 2 " small car" 3 "two wheels" 4 "pedestrian" 5 "Reserved" 6 "Reserved" 7 "Invalid" ;
VAL_ 307 SRR_RR_BSD_check 0 "Available" 1 "Temporarily not available" 2 "Permanently not available" ;
VAL_ 307 SRR_RR_BSD_state 0 "OFF State" 1 "Stand by state" 2 "Armed state" 3 "Static Warning" 4 "Flashing Warning" 5 "Malfunction stage" 6 "Reserved" 7 "Invalid" ;
VAL_ 307 SRR_RR_BSD_AudChime_Feed 0 "Off" 1 "On" ;
VAL_ 307 SRR_RR_BSD_IndLeft 0 "Indicator output off" 1 "Indicator On(warning stage - 1)" 2 "Indicator flashing(warning stage - 2)" 3 "Sensor Fault" ;
VAL_ 307 SRR_RR_BSD_IndRight 0 "Indicator output off" 1 "Indicator On(warning stage - 1)" 2 "Indicator flashing(warning stage - 2)" 3 "Sensor Fault" ;
VAL_ 307 SRR_RR_BSD_SndWarn 0 "Sound Warning disable" 1 "Left Sound Warning enable" 2 "Right Sound Warning enable" 3 "Left and Right Sound Warning enable" ;
VAL_ 307 SRR_RR_BSD_Mode_Feed 0 "Off" 1 "On" ;
VAL_ 307 SRR_RR_BSD_sens_Feed 0 "Early" 1 "Normal" 2 "Late" 3 "Reserved" ;
VAL_ 307 SRR_RR_RCTA_IndRight 0 "Indicator output off" 1 "Indicator On(warning stage - 1)" 2 "Indicator flashing(warning stage - 2)" 3 "Reserved" ;
VAL_ 307 SRR_RR_RCTA_IndLeft 0 "Indicator output off" 1 "Indicator On(warning stage - 1)" 2 "Indicator flashing(warning stage - 2)" 3 "Reserved" ;
VAL_ 307 SRR_RR_RCTA_sens_Feed 0 "Early" 1 "Normal" 2 "Late" 3 "Reserved" ;
VAL_ 307 SRR_RR_RCTA_state 0 "OFF State" 1 "Stand by state" 2 "Armed state" 3 "Warning stage" 4 "Malfunction Stage" ;
VAL_ 307 SRR_RR_RCTA_SndWarn 0 "Sound Warning disable" 1 "Left Sound Warning enable" 2 "Right Sound Warning enable" 3 "Left and Right Sound Warning enable" ;
VAL_ 307 SRR_RR_RCTA_Mode_Feed 0 "Off'" 1 "On" 2 "Reserved" ;
VAL_ 307 SRR_RR_RCTA_check 0 "Available" 1 "Temporarily not available" 2 "Permanently not available" ;
VAL_ 307 SRR_RR_DOW_SndWarn 0 "Sound Warning disable" 1 "Left Sound Warning enable" 2 "Right Sound Warning enable" 3 "Left and Right Sound Warning enable" ;
VAL_ 307 SRR_RR_DOW_WarnRight 0 "No warning" 1 "Warning Level 1" 2 "Warning Level 2" 3 "Reserved" ;
VAL_ 307 SRR_RR_DOW_WarnLeft 0 "No warning" 1 "Warning Level 1" 2 "Warning Level 2" 3 "Reserved" ;
VAL_ 307 SRR_RR_DOW_check 0 "Available" 1 "Temporarily not available" 2 "Permanently not available" ;
VAL_ 307 SRR_RR_DOW_state 0 "OFF State" 1 "Stand by state" 2 "Armed state" 3 "Warning stage" 4 "Malfunction stage" ;
VAL_ 307 SRR_RR_DOW_Mode_Feed 0 "Off" 1 "Warning Only" 2 "Warning/Door Lock both" 3 "Reserved" ;
VAL_ 307 SRR_RR_Right_block 0 "No Blockage" 1 "Blockaged" ;
VAL_ 307 SRR_RR_Left_block 0 "No Blockage" 1 "Blockaged" ;
VAL_ 307 Obj_Class_RL 0 "unknown" 1 "big car" 2 "small car" 3 "two wheels" 4 "pedestrain" 5 "Reserved" 6 "Reserved" 7 "Reserved" ;
VAL_ 307 Obj_Class_RR 0 "unknown" 1 "big car" 2 "small car" 3 "two wheels" 4 "pedestrain" 5 "Reserved" 6 "Reserved" 7 "Reserved" ;
VAL_ 307 SRR_RR_RCTB_Mode_Feed 0 "Off" 1 "On" ;
VAL_ 307 SRR_RR_RCTB_State 0 "OFF State" 1 "Stand by state" 2 "Armed state" 3 "Warning stage" 4 "Malfunction stage" ;
VAL_ 307 SRR_RR_RCTB_Check 0 "Available" 1 "Temporarily not available" 2 "Permanently not available" ;
VAL_ 307 SRR_RR_RCTB_Braking_Flag 0 "No brake request" 1 "Pre-fill request" 2 "Brake request" ;
VAL_ 826 SRR_RR_RadarRight_Cal_Status 0 "No Calib" 1 "Calib OK" ;
VAL_ 826 SRR_RR_MasterSRR_check 0 "Available" 1 "Temporarily not available" 2 "Permanently not available" ;
VAL_ 826 SRR_RR_RadarRight_DynaCal_Status 0 "Calibration is in progress" 1 "The absolute value of calibration angle is greater than 6 degrees" ;
VAL_ 826 SRR_RR_RadarLeft_Cal_Status 0 "No Calib" 1 "Calib OK" ;
VAL_ 826 SRR_RR_RadarLeft_DynaCal_Status 0 "Calibration is in progress" 1 "The absolute value of calibration angle is greater than 6 degrees" ;
VAL_ 826 SRR_RR_SlaveSRR_check 0 "Available" 1 "Temporarily not available" 2 "Permanently not available" ;
VAL_ 826 SRR_RR_Warning_Flag_21 0 "No Error" 1 "Error" ;
VAL_ 826 SRR_RR_Warning_Flag_22 0 "No Error" 1 "Error" ;
VAL_ 826 SRR_RR_Warning_Flag_23 0 "No Error" 1 "Error" ;
VAL_ 826 SRR_RR_Warning_Flag_24 0 "No Error" 1 "Error" ;
VAL_ 636 SRR_RR_TimeSynchronization_Statu 0 "Sync successful" 1 "failing" 2 "Syncing in progress" 3 "Unsync" 4 "Reserved" ;
VAL_ 827 SRR_RR_CDS_BSD 0 "Unsupported" 1 "Without" 2 " With" 3 "Invalid" ;
VAL_ 827 SRR_RR_CDS_DOW 0 "Unsupported" 1 "Without" 2 " With" 3 "Invalid" ;
VAL_ 827 SRR_RR_CDS_RCTA 0 "Unsupported" 1 "Without" 2 " With" 3 "Invalid" ;
VAL_ 830 RR_Obj1_DynProp 0 "moving" 1 "stationary" 2 "oncoming" 3 "stationary candidate" 4 "unknown" 5 "crossing stationary" 6 "crossing moving" 7 "stopped" ;
VAL_ 830 RR_Obj1_MeasState 0 "Deleted" 1 "New" 2 "Measured" 3 "Predicted" 4 "Deleted for merge" 5 "New from merge" 6 "Reserved" 7 "Invalid" ;
VAL_ 830 RR_Obj1_ProbOfExist 0 "Invalid" 1 "<25%" 2 " <50%" 3 "<75%" 4 "<90%" 5 "<99%" 6 "<99.9%" 7 "<=100%" ;
VAL_ 830 RR_Obj1j_Class 0 "unknown" 1 "big car" 2 " small car" 3 "two wheels" 4 "pedestrian" 5 "Reserved" 6 "Reserved" 7 "Invalid" ;
VAL_ 830 RR_Obj2_DynProp 0 "moving" 1 "stationary" 2 "oncoming" 3 "stationary candidate" 4 "unknown" 5 "crossing stationary" 6 "crossing moving" 7 "stopped" ;
VAL_ 830 RR_Obj2_MeasState 0 "Deleted" 1 "New" 2 "Measured" 3 "Predicted" 4 "Deleted for merge" 5 "New from merge" 6 "Reserved" 7 "Invalid" ;
VAL_ 830 RR_Obj2_ProbOfExist 0 "Invalid" 1 "<25%" 2 " <50%" 3 "<75%" 4 "<90%" 5 "<99%" 6 "<99.9%" 7 "<=100%" ;
VAL_ 830 RR_Obj2j_Class 0 "unknown" 1 "big car" 2 " small car" 3 "two wheels" 4 "pedestrian" 5 "Reserved" 6 "Reserved" 7 "Invalid" ;
VAL_ 830 RR_Obj3_DynProp 0 "moving" 1 "stationary" 2 "oncoming" 3 "stationary candidate" 4 "unknown" 5 "crossing stationary" 6 "crossing moving" 7 "stopped" ;
VAL_ 830 RR_Obj3_MeasState 0 "Deleted" 1 "New" 2 "Measured" 3 "Predicted" 4 "Deleted for merge" 5 "New from merge" 6 "Reserved" 7 "Invalid" ;
VAL_ 830 RR_Obj3_ProbOfExist 0 "Invalid" 1 "<25%" 2 " <50%" 3 "<75%" 4 "<90%" 5 "<99%" 6 "<99.9%" 7 "<=100%" ;
VAL_ 830 RR_Obj3j_Class 0 "unknown" 1 "big car" 2 " small car" 3 "two wheels" 4 "pedestrian" 5 "Reserved" 6 "Reserved" 7 "Invalid" ;
VAL_ 830 RR_Obj4_DynProp 0 "moving" 1 "stationary" 2 "oncoming" 3 "stationary candidate" 4 "unknown" 5 "crossing stationary" 6 "crossing moving" 7 "stopped" ;
VAL_ 830 RR_Obj4_MeasState 0 "Deleted" 1 "New" 2 "Measured" 3 "Predicted" 4 "Deleted for merge" 5 "New from merge" 6 "Reserved" 7 "Invalid" ;
VAL_ 830 RR_Obj4_ProbOfExist 0 "Invalid" 1 "<25%" 2 " <50%" 3 "<75%" 4 "<90%" 5 "<99%" 6 "<99.9%" 7 "<=100%" ;
VAL_ 830 RR_Obj4j_Class 0 "unknown" 1 "big car" 2 " small car" 3 "two wheels" 4 "pedestrian" 5 "Reserved" 6 "Reserved" 7 "Invalid" ;
VAL_ 637 SRR_FL_TimeSynchronization_Statu 0 "Sync successful" 1 "failing" 2 "Syncing in progress" 3 "Unsync" 4 "Reserved" ;
VAL_ 638 SRR_FR_TimeSynchronization_Statu 0 "Sync successful" 1 "failing" 2 "Syncing in progress" 3 "Unsync" 4 "Reserved" ;
VAL_ 315 SRR_FR_IA_Mode_Feed 0 "Off" 1 "ON" ;
VAL_ 315 SRR_FR_IA_State 0 "OFF state" 1 "Stand by state" 2 "Armed state" 3 "Warning state" 4 "Malfunction state" ;
VAL_ 315 SRR_FR_IA_Check 0 "Available" 1 "Temporarily not available" 2 "Permanently not available" ;
VAL_ 315 SRR_FR_FCTB_Braking_Flag 0 "No brake request" 1 "Pre-fill request" 2 "Brake request" ;
VAL_ 315 SRR_FR_FCTB_Mode_Feed 0 "Off" 1 "ON" ;
VAL_ 315 SRR_FR_FCTB_State 0 "OFF state" 1 "Stand by state" 2 "Armed state" 3 "Warning state" 4 "Malfunction state" ;
VAL_ 315 SRR_FR_FCTB_Check 0 "Available" 1 "Temporarily not available" 2 "Permanently not available" ;
VAL_ 315 SRR_FR_IA_Left_Warning 0 "No Warning" 1 "warning stage-1" 2 " warning stage-2" 3 "warning stage-3" ;
VAL_ 315 SRR_FR_IA_Right_Warning 0 "No Warning" 1 "warning stage-1" 2 " warning stage-2" 3 "warning stage-3" ;
VAL_ 828 SRR_FR_RadarRight_Cal_Status 0 "No Calib" 1 "Calib OK" ;
VAL_ 828 SRR_FR_MasterSRR_check 0 "Available" 1 "Temporarily not available" 2 "Permanently not available" ;
VAL_ 828 SRR_FR_RadarRight_DynaCal_Status 0 "Calibration is in progress" 1 "The absolute value of calibration angle is greater than 6 degrees" ;
VAL_ 828 SRR_FR_RadarLeft_Cal_Status 0 "No Calib" 1 "Calib OK" ;
VAL_ 828 SRR_FR_RadarLeft_DynaCal_Status 0 "Calibration is in progress" 1 "The absolute value of calibration angle is greater than 6 degrees" ;
VAL_ 828 SRR_FR_SlaveSRR_check 0 "Available" 1 "Temporarily not available" 2 "Permanently not available" ;
VAL_ 639 ADCU_TimeSynchronization_Status 0 "Sync successful" 1 "failing" 2 "Syncing in progress" 3 "Unsync" 4 "Reserved" ;
VAL_ 543 ADCU_AEB_Warning 0 "No warning" 1 "Braking" 2 "Post Feedback" ;
VAL_ 543 ADCU_AEB_State 0 "OFF State" 1 "Stand by Mode" 2 "Active Mode" 3 "Hold Mode" 4 "Suppressed" 5 "Fault" ;
VAL_ 543 ADCU_AEB_Mode_Feed 0 "Off" 1 "ON" ;
VAL_ 543 ADCU_AEB_check 0 "Available" 1 "Temporarily not available" 2 "Permanently not available" ;
VAL_ 543 ADCU_FCW_Mode_Feed 0 "Off" 1 "ON" ;
VAL_ 543 ADCU_FCW_Sens_Feed 0 "Early" 1 "Normal" 2 "Late" 3 "Reserved" ;
VAL_ 543 ADCU_FCW_state 0 "OFF State" 1 "Stand by state" 2 "Active state" 3 "reserve" ;
VAL_ 543 ADCU_FCW_check 0 "Available" 1 "Temporarily not available" 2 "Permanently not available" ;
VAL_ 543 ADCU_FCW_warning 0 "No Warning" 1 "warning stage-1" 2 "warning stage-2" 3 "warning stage-3" ;
VAL_ 543 ADCU_CV_AEB_Alert 0 "No AEB (Fusion)" 1 "AEB active (Fusion)" ;
VAL_ 543 ADCU_CV_FCW_Alert 0 "No FCW (Fusion)" 1 "FCW active (Fusion)" ;
VAL_ 543 ADCU_CV_PartialAEB_Alert 0 "No partial AEB (Fusion)" 1 "Partial AEB active (Fusion)" ;
VAL_ 543 ADCU_CV_PreFill_Alert 0 "No Prefill (Fusion)" 1 "Prefill active (Fusion)" ;
VAL_ 543 ADCU_VD_AEB_Alert 0 "No AEB (Fusion)" 1 "AEB active (Fusion)" ;
VAL_ 543 ADCU_VD_DBS_Alert 0 "No DBS (Vision)" 1 "DBS active (Vision)" ;
VAL_ 543 ADCU_VD_EGOTAP_AEB_Alert 0 "No AEB for tap (Vision)" 1 "AEB active for tap (Vision)" ;
VAL_ 543 ADCU_VD_FCW_Alert 0 "No FCW for C2C/ C2M (Vision)" 1 "FCW active C2C/ C2M (Vision)" ;
VAL_ 543 ADCU_VD_HeadOn_AEB_Alert 0 "No AEB for head on (Vision) " 1 "AEB active for head on (Vision)" ;
VAL_ 543 ADCU_VD_PartialAEB_Alert 0 "No partial AEB for C2C/C2M (Vision)" 1 "Partial AEB active for C2C/C2M (Vision)" ;
VAL_ 543 ADCU_VD_Prefill_Alert 0 "No Prefill for C2C/C2M (Vision)" 1 "Prefill active for C2C/C2M (Vision)'" ;
VAL_ 543 ADCU_VRU_AEB_Alert 0 "No AEB for VRU (Vision)" 1 "AEB active for VRU (Vision)" ;
VAL_ 543 ADCU_VRU_FCW_Alert 0 "No FCW for VRU (Vision)" 1 "FCW active for VRU (VIsion)" ;
VAL_ 543 ADCU_VRU_PreFill_Alert 0 "No Prefill for VRU (Vision)" 1 "Prefill active for VRU (Vision)" ;
VAL_ 543 ADCU_AEB_Trigger_Source 0 "None" 1 "Vsion Only" 2 "Fusion Only" 3 "Both" ;
VAL_ 543 ADCU_FCW_Trigger_Source 0 "None" 1 "Vsion Only" 2 "Fusion Only" 3 "Both" ;
VAL_ 551 ADCU_AESA_AAESA_Status 0 "Not active" 1 "Decelerating" 2 "Target following" 3 "Lane Changes" 4 "reserved" ;
VAL_ 551 ADCU_AESA_AAESA_ECALLReq 0 "No request" 1 "Requested" ;
VAL_ 551 ADCU_AESA_AAESA_DoorUnlockReq 0 "No request" 1 "Requested" ;
VAL_ 552 ESA_Freespace 0 "No Freespace available" 1 "Left Freespace available" 2 "Right Freespace available" 3 "Both side Freespace available" ;
VAL_ 556 ADCU_FCAM_ALCA_state 0 "Passive" 1 "Standby" 2 "LC start" 3 "LC Ongoing" 4 "LC finishing" 5 "Suspend" 6 "Abort" 7 "Fault" ;
VAL_ 556 ADCU_NOP_check 0 "Available" 1 "Temporary fault" 2 "Permanent Fault" 3 "Invalid" ;
VAL_ 556 ADCU_NOP_state 0 "Off" 1 "Standby" 2 "Active" 3 "Override" 4 "Passive" 5 "Downgrade to HWA_ALCA" 6 "MRM" 7 "Fault" 8 "Downgrade to ACC" 9 "Reserve" 10 "Reserve" 11 "Reserve" 12 "Reserve" 13 "Reserve" 14 "Reserve" 15 "Reserve" ;
VAL_ 556 ADCU_NOP_ICON_Feed 0 "No icon" 1 "Gray ICON" 2 "Purple ICON" 3 "White ICON" 4 "Yellow ICON" 5 "Red ICON" 7 "Invalid" ;
VAL_ 556 ADCU_NOP_txtpopup 0 "OFF" 1 "NOP initial activation" 2 "Manual Cancel warning" 3 "Downgrade to HWA ahead" 4 "Activation Rejected" 5 "Sensors / System fault" 6 "Notification Change Lane Left Navigation Only" 7 "Notification Change Lane Right Navigation Only" 8 "Overtaking suggestion" 9 "Leaving ODD" 10 "Temporary function suspension - construction zones, tunnels, adverse conditions" 11 "Sharp curve ahead" 12 "Resume rejected. NOP not activated" 13 "Destination reached" 14 "Unprotected intersection ahead" 15 "Vehicle low speed ahead" 16 "Take Over control" 17 "Ambulance / Emergency vehicle detected" 18 "text_popup_18" 19 "text_popup_19" 20 "text_popup_20" 21 "text_popup_21" 22 "text_popup_22" 23 "text_popup_23" 24 "text_popup_24" 25 "text_popup_25" 26 "text_popup_26" 27 "text_popup_27" 28 "text_popup_28" 29 "text_popup_29" 30 "text_popup_30" 31 "text_popup_31" ;
VAL_ 556 ADCU_NOP_Warning 0 "No Request" 1 "Audible Warning" 2 "Reserved" 3 "Invalid" ;
VAL_ 556 ADCU_NOP_AAESA_textpopup 0 "No txt" 1 "text 1" 2 "text 2" 3 "text 3" 4 "text 4" 5 "text 5" 6 "text 6" 7 "reserved" ;
VAL_ 556 ADCU_NOP_TOR 0 "No txt" 1 "text 1" 2 "text 2" 3 "text 3" 4 "text 4" 5 "text 5" 6 "text 6" 7 "reserved" ;
VAL_ 556 ADCU_eyesoff_Warning_Mode_2 0 "No Warning!" 1 "Level 1" 2 "Level 2" 3 "Level 3" 4 "reserved" 5 "reserved" 6 "reserved" 7 "reserved" ;
VAL_ 556 ADCU_EOD 0 "Eyes On" 1 "Eyes Off" ;
VAL_ 556 ADCU_NOP_Mode_Feed 0 "OFF" 1 "ON" 2 "Reserved" 3 "Reserved" ;
VAL_ 556 ADCU_NOP_Type_Feed 0 "Init" 1 "HWA" 2 "NOP" 3 "Reserved" ;
VAL_ 556 ADCU_DCA_Alert 0 "ON" 1 "OFF" 2 "reserved" 3 "reserved" 4 "reserved" 5 "reserved" 6 "reserved" 7 "reserved" ;
VAL_ 556 ADCU_AAESA_Status 0 "Not active" 1 "Decelerating" 2 "Target following" 3 "Reserved" 4 "Reserved" 5 "Reserved" 6 "Reserved" 7 "Reserved" ;
VAL_ 556 ADCU_HWA_ALCA_Status 0 "Off" 1 "Stand_by" 2 "Active" 3 "Rejected" 4 "Passive" 5 "Finished" 6 "Fault" 7 "Abort" 8 "Reserved" 9 "Reserved" 10 "Reserved" ;
VAL_ 556 ADCU_NOP_ALCA_Status 0 "Off" 1 "Stand_by" 2 "Active" 3 "Rejected" 4 "Passive" 5 "Finished" 6 "Fault" 7 "Abort" 8 "Reserved" 9 "Reserved" 10 "Reserved" ;
VAL_ 556 ADCU_ALC_Mode_feed 0 "OFF" 1 "ON" 2 "Reserved" 3 "Reserved" ;
VAL_ 556 ADCU_ALC_txtpopup 0 "No popup" 1 "Left ALC initiated by driver" 2 "Right ALC initated by driver" 3 "Left ALC recommended" 4 "Right ALC recommended" 5 "Left ALC start manoeuvre" 6 "Right ALC start manoeuvre" 7 "ALC request rejected when user initiate" 8 "ALC canceled because timeout after x sec trying to start manoeuvre" 9 "ALC canceled manually by user" 10 "ALC canceled by system before PONR. Able to resume HWA" 11 "ALC canceled by system after PONR. Able to resume HWA" 12 "ALC cancel because of handsoff + Need user takeover" 13 "ALC canceled by system + Need user takeover" 14 "Reserve" 15 "Reserve" ;
VAL_ 556 ADCU_AESA_popup 0 "None" 1 "Takeover-AESA Activate" 2 "Post AESA - AESA complete" 3 "Post AESA - AESA cancelled due to user intervention" 4 "Reserved" 5 "Reserved" 6 "Reserved" 7 "Reserved" ;
VAL_ 556 ADCU_ALC_Mode_Gaze_Feed 0 "OFF" 1 "ON" 2 "Reserved" 3 "Reserved" ;
VAL_ 556 ADCU_ALC_Mode_Recommend_Feed 0 "OFF" 1 "ON" 2 "Reserved" 3 "Reserved" ;
VAL_ 556 ADCU_ALC_ICON_Feed 0 "No Icon" 1 "Passive" 2 "Standby Left only" 3 "Standby Right only" 4 "Standby both sides" 5 "Active Left initiate" 6 "Active Right initiate" 7 "Active Left manoeuvre" 8 "Active Right manoeuvre" ;
VAL_ 556 ADCU_FCAM_NOP_ODD_Sts 0 "None" 1 "NOP will deactivate in XXXm" 2 "Inside NOP ODD" 3 "Outside NOP ODD" ;
VAL_ 556 ADCU_FCAM_ALCA_TurnIndicatorReq 0 "None" 1 "Request Left on" 2 "Request Right on" 3 "Request off" 4 "Invalid" ;
VAL_ 556 ADCU_FCAM_ALCA_textpopup 0 "None" 1 "LC ongoing" 2 "LC has finished" 3 "LC has been aborted" 4 "Please cofirm the LC" ;
VAL_ 577 ADCU_PA_AutoOn_Feed 0 "OFF" 1 "ON" ;
VAL_ 577 ADCU_FPA_State 0 "Standby" 1 "Active" 2 "Error" 3 "Invalid" ;
VAL_ 577 ADCU_RPA_State 0 "Standby" 1 "Active" 2 "Error" 3 "Invalid" ;
VAL_ 577 ADCU_SPA_State 0 "Standby" 1 "Active" 2 "Error" 3 "Invalid" ;
VAL_ 577 ADCU_RPA_Available 0 "without RPA" 1 "with RPA" ;
VAL_ 577 ADCU_NSPA_Available 0 "without NSPA" 1 "with NSPA" ;
VAL_ 577 ADCU_FPA_Available 0 "without FPA" 1 "with FPA" ;
VAL_ 577 ADCU_FPA_Check 0 "Available" 1 "Temporary fault" 2 "Permanent fault" 3 "Invalid" ;
VAL_ 577 ADCU_RPA_Check 0 "Available" 1 "Temporary fault" 2 "Permanent fault" 3 "Invalid" ;
VAL_ 577 ADCU_NSPA_Check 0 "Available" 1 "Temporary fault" 2 "Permanent fault" 3 "Invalid" ;
VAL_ 579 ADCU_FPA_AlertFIL 0 "No warning" 1 "Warning level 1" 2 "Warning level 2" 3 "Warning level 3" 4 "Warning level 4" 5 "Warning level 5" 6 "Inhibited" 7 "Invalid" ;
VAL_ 579 ADCU_FPA_AlertFOL 0 "No warning" 1 "Warning level 1" 2 "Warning level 2" 3 "Warning level 3" 4 "Warning level 4" 5 "Warning level 5" 6 "Inhibited" 7 "Invalid" ;
VAL_ 579 ADCU_FPA_AlertFIR 0 "No warning" 1 "Warning level 1" 2 "Warning level 2" 3 "Warning level 3" 4 "Warning level 4" 5 "Warning level 5" 6 "Inhibited" 7 "Invalid" ;
VAL_ 579 ADCU_FPA_AlertFOR 0 "No warning" 1 "Warning level 1" 2 "Warning level 2" 3 "Warning level 3" 4 "Warning level 4" 5 "Warning level 5" 6 "Inhibited" 7 "Invalid" ;
VAL_ 579 ADCU_FPA_AlertFSL 0 "No warning" 1 "Warning level 1" 2 "Warning level 2" 3 "Warning level 3" 4 "Warning level 4" 5 "Warning level 5" 6 "Inhibited" 7 "Invalid" ;
VAL_ 579 ADCU_FPA_AlertFSR 0 "No warning" 1 "Warning level 1" 2 "Warning level 2" 3 "Warning level 3" 4 "Warning level 4" 5 "Warning level 5" 6 "Inhibited" 7 "Invalid" ;
VAL_ 579 ADCU_FPA_ChimeReqFIL 0 "No Request" 1 "Chime Request" ;
VAL_ 579 ADCU_FPA_ChimeReqFOL 0 "No Request" 1 "Chime Request" ;
VAL_ 579 ADCU_FPA_ChimeReqFIR 0 "No Request" 1 "Chime Request" ;
VAL_ 579 ADCU_FPA_ChimeReqFOR 0 "No Request" 1 "Chime Request" ;
VAL_ 579 ADCU_FPA_ChimeReqFSL 0 "No Request" 1 "Chime Request" ;
VAL_ 579 ADCU_FPA_ChimeReqFSR 0 "No Request" 1 "Chime Request" ;
VAL_ 580 ADCU_RPA_AlertRIL 0 "No warning" 1 "Warning level 1" 2 "Warning level 2" 3 "Warning level 3" 4 "Warning level 4" 5 "Warning level 5" 6 "Inhibited" 7 "Invalid" ;
VAL_ 580 ADCU_RPA_AlertROL 0 "No warning" 1 "Warning level 1" 2 "Warning level 2" 3 "Warning level 3" 4 "Warning level 4" 5 "Warning level 5" 6 "Inhibited" 7 "Invalid" ;
VAL_ 580 ADCU_RPA_AlertRIR 0 "No warning" 1 "Warning level 1" 2 "Warning level 2" 3 "Warning level 3" 4 "Warning level 4" 5 "Warning level 5" 6 "Inhibited" 7 "Invalid" ;
VAL_ 580 ADCU_RPA_AlertROR 0 "No warning" 1 "Warning level 1" 2 "Warning level 2" 3 "Warning level 3" 4 "Warning level 4" 5 "Warning level 5" 6 "Inhibited" 7 "Invalid" ;
VAL_ 580 ADCU_RPA_AlertRSL 0 "No warning" 1 "Warning level 1" 2 "Warning level 2" 3 "Warning level 3" 4 "Warning level 4" 5 "Warning level 5" 6 "Inhibited" 7 "Invalid" ;
VAL_ 580 ADCU_RPA_AlertRSR 0 "No warning" 1 "Warning level 1" 2 "Warning level 2" 3 "Warning level 3" 4 "Warning level 4" 5 "Warning level 5" 6 "Inhibited" 7 "Invalid" ;
VAL_ 580 ADCU_RPA_ChimeReqRIL 0 "No Request" 1 "Chime Request" ;
VAL_ 580 ADCU_RPA_ChimeReqROL 0 "No Request" 1 "Chime Request" ;
VAL_ 580 ADCU_RPA_ChimeReqRIR 0 "No Request" 1 "Chime Request" ;
VAL_ 580 ADCU_RPA_ChimeReqROR 0 "No Request" 1 "Chime Request" ;
VAL_ 580 ADCU_RPA_ChimeReqRSL 0 "No Request" 1 "Chime Request" ;
VAL_ 580 ADCU_RPA_ChimeReqRSR 0 "No Request" 1 "Chime Request" ;
VAL_ 582 ADCU_NSPA_AlertFSL1 0 "No warning" 1 "Warning level 1" 2 "Warning level 2" 3 "Warning level 3" 4 "Warning level 4" 5 "Warning level 5" 6 "Inhibited" 7 "Invalid" ;
VAL_ 582 ADCU_NSPA_AlertFSL2 0 "No warning" 1 "Warning level 1" 2 "Warning level 2" 3 "Warning level 3" 4 "Warning level 4" 5 "Warning level 5" 6 "Inhibited" 7 "Invalid" ;
VAL_ 582 ADCU_NSPA_AlertFSR1 0 "No warning" 1 "Warning level 1" 2 "Warning level 2" 3 "Warning level 3" 4 "Warning level 4" 5 "Warning level 5" 6 "Inhibited" 7 "Invalid" ;
VAL_ 582 ADCU_NSPA_AlertFSR2 0 "No warning" 1 "Warning level 1" 2 "Warning level 2" 3 "Warning level 3" 4 "Warning level 4" 5 "Warning level 5" 6 "Inhibited" 7 "Invalid" ;
VAL_ 582 ADCU_NSPA_AlertRSL1 0 "No warning" 1 "Warning level 1" 2 "Warning level 2" 3 "Warning level 3" 4 "Warning level 4" 5 "Warning level 5" 6 "Inhibited" 7 "Invalid" ;
VAL_ 582 ADCU_NSPA_AlertRSL2 0 "No warning" 1 "Warning level 1" 2 "Warning level 2" 3 "Warning level 3" 4 "Warning level 4" 5 "Warning level 5" 6 "Inhibited" 7 "Invalid" ;
VAL_ 582 ADCU_NSPA_AlertRSR1 0 "No warning" 1 "Warning level 1" 2 "Warning level 2" 3 "Warning level 3" 4 "Warning level 4" 5 "Warning level 5" 6 "Inhibited" 7 "Invalid" ;
VAL_ 582 ADCU_NSPA_AlertRSR2 0 "No warning" 1 "Warning level 1" 2 "Warning level 2" 3 "Warning level 3" 4 "Warning level 4" 5 "Warning level 5" 6 "Inhibited" 7 "Invalid" ;
VAL_ 582 ADCU_NSPA_ChimeReqFSL1 0 "No Request" 1 "Chime Request" ;
VAL_ 582 ADCU_NSPA_ChimeReqFSL2 0 "No Request" 1 "Chime Request" ;
VAL_ 582 ADCU_NSPA_ChimeReqFSR1 0 "No Request" 1 "Chime Request" ;
VAL_ 582 ADCU_NSPA_ChimeReqFSR2 0 "No Request" 1 "Chime Request" ;
VAL_ 582 ADCU_NSPA_ChimeReqRSL1 0 "No Request" 1 "Chime Request" ;
VAL_ 582 ADCU_NSPA_ChimeReqRSL2 0 "No Request" 1 "Chime Request" ;
VAL_ 582 ADCU_NSPA_ChimeReqRSR1 0 "No Request" 1 "Chime Request" ;
VAL_ 582 ADCU_NSPA_ChimeReqRSR2 0 "No Request" 1 "Chime Request" ;
VAL_ 583 ADCU_RAEB_State 0 "Off" 1 "Inactive" 2 "Ready" 3 "PreFill" 4 "AEB Active" 5 "Post-RAEB Brake" 6 "Error" 7 "Invalid" ;
VAL_ 583 ADCU_RAEB_Check 0 "Available" 1 "Degraded" 2 "Temporarily not available" 3 "Permanently not available" 4 "RAEB Inhibited" 5 "Reserved" 6 "Initializing" 7 "Invalid" ;
VAL_ 583 ADCU_RAEB_Mode_Feed 0 "OFF" 1 "ON" 2 "Reserved" 3 "Invalid" ;
VAL_ 583 ADCU_RAEB_Warning 0 "No Request" 1 "Braking" 2 "Postfeedback" 3 "Display Prompt to turn OFF RAEB" 4 "Reserved" 5 "Reserved" 6 "Reserved" 7 "Invalid" ;
VAL_ 583 ADCU_RAEB_BrakeReq_Source 0 "None" 1 "RAEB request" 2 "Rear ACPE Request" 3 "RCTB - by Radar Rear crossing obj" 4 "Reserved" 5 "Reserved" 6 "Reserved" 7 "Invalid" ;
VAL_ 605 ADCU_Driving_Parking_state 0 "Manual Driving Hybrid Mode" 1 "Manual Driving state" 2 "Auto Parking" 3 "Auto Driving" 4 "Manual Driving Hybrid Mode Inprocess" 5 "Manual Driving state Inprocess" 6 "Auto Parking Inprocess" 7 "Auto Driving Inprocess" ;
VAL_ 664 ADCU_ACC_Input_State 0 "no failure" 1 "failure" 3 "invalid" ;
VAL_ 664 ADCU_TSR_Input_State 0 "no failure" 1 "failure" 3 "invalid" ;
VAL_ 664 ADCU_ESA_Input_State 0 "no failure" 1 "failure" 3 "invalid" ;
VAL_ 563 ADAS_Sentry_Mode_Stat 0 "OFF" 1 "ON" 2 "Reserved" 3 "Invalid" ;
VAL_ 705 ADCU_MHU_DNS_Warning 0 "not active" 1 "active" 2 "reserved" 3 "invalid" ;
VAL_ 586 ADCU_ACPE_PowerCommand 0 "No Request" 1 "ACPE Armed-cut-off power" 2 "ACPE Armed-Limit power" 3 "ACPE intervene cut-off power" 4 "ACPE intervene limit power" 5 "ACPE Disengaging" 6 "Reserved" 7 "Invalid" ;
VAL_ 586 ADCU_ACPE_BrakeCommand 0 "No Request'" 1 "Front ACPE Brake request" 2 "Rear ACPE Brake Request" 3 "Invalid" ;
VAL_ 586 ADCU_ACPE_Available 0 "No support'" 1 "without ACPE" 2 "with ACPE" 3 "Invalid" ;
VAL_ 586 ADCU_ACPE_FuncActive 0 "Not Active" 1 "Active" ;
VAL_ 586 ADCU_ACPE_HMICommand 0 "No Request" 1 "ACPE Intervene Alert" 2 "Display prompt offer turn off ACPE" 3 "Reserved" 4 "Reserved" 5 "Reserved" 6 "Reserved" 7 "Invalid" ;
VAL_ 586 ADCU_ACPE_State 0 "Off" 1 "Inactive" 2 "Ready" 3 "Armed" 4 "ACPE Active" 5 "ACPE Inhibited" 6 "Error" 7 "Invalid" ;
VAL_ 586 ADCU_ACPE_Setting_Feed 0 "ACPE Off" 1 "ACPE ON" 2 "Reserved" 3 "Invalid" ;
VAL_ 586 ADCU_ACPE_Sens_Feed 0 "Normal'" 1 "Plus" 2 "Reserved" 3 "Invalid" ;
VAL_ 586 ADCU_ACPE_Check 0 "Available" 1 "Degraded" 2 "Temporarily not available" 3 "Permanently not available" 4 "Inhibited" 5 "Reserved" 6 "Initializing" 7 "Invalid" ;
VAL_ 586 ACPE_FrontControler_Operate 0 "Off" 1 "Inactive" 2 "Ready" 3 "Armed" 4 "ACPE Active" 5 "ACPE Inhibited" 6 "Error" 7 "Invalid" ;
VAL_ 586 ACPE_RearControler_Operate 0 "Off" 1 "Inactive" 2 "Ready" 3 "Armed" 4 "ACPE Active" 5 "ACPE Inhibited" 6 "Error" 7 "Invalid" ;
VAL_ 588 ADCU_SVM_Guideline_Feed 0 "OFF" 1 "ON" 2 "Reserved" 3 "Invalid" ;
VAL_ 588 ADCU_SVM_ObjOverlay_Feed 0 "OFF" 1 "ON" 2 "Reserved" 3 "Invalid" ;
VAL_ 588 ADCU_SVM_TrailerGuideline_Feed 0 "OFF" 1 "ON" 2 "Reserved" 3 "Invalid" ;
VAL_ 588 ADCU_SVM_MaxDoorOverlay_Feed 0 "OFF" 1 "ON" 2 "Reserved" 3 "Invalid" ;
VAL_ 588 ADCU_SVM_Transparency_Feed 0 "OFF" 1 "ON" 2 "Reserved" 3 "Invalid" ;
VAL_ 588 ADCU_SVM_BlindSpotView_Feed 0 "OFF" 1 "ON" 2 "Reserved" 3 "Invalid" ;
VAL_ 588 ADCU_SVM_BlindspotView 0 "OFF" 1 "'Left Blindspot camera showing" 2 "Right Blindspot camera showing" 3 "Invalid" ;
VAL_ 588 ADCU_SVM_ShowAVMReq 0 "No Request" 1 "Show SVM Req" 2 "Hide SVM Req" 3 "Reserved" 4 "Reserved" 5 "Reserved" 6 "Reserved" 7 "Invalid" ;
VAL_ 588 ADCU_SVM_View_Status 0 "No Request" 1 "Front View" 2 "Front Junction View" 3 "Rear View" 4 "Rear Junction View" 5 "3D View'" 6 "3D - Left Tire View" 7 "3D- Right Tire View" 8 "3D- Frunk View" 9 "3D- Trunk View" 10 "3D- Globe View" 31 "Invalid" ;
VAL_ 588 ADCU_SVM_Status_Signal 0 "OFF" 1 "STANDBY" 2 "ACTIVE" 3 "FAULT" 4 "Reserved" 5 "Reserved" 6 "Reserved" 7 "Invalid" ;
VAL_ 588 ADCU_Early_RVC_Status_Signal 0 "OFF" 1 "STANDBY" 2 "ACTIVE" 3 "FAULT" 4 "Reserved" 5 "Reserved" 6 "Reserved" 7 "Invalid" ;
VAL_ 602 ADCU_SVM_FrontCam_Check 0 "Available" 1 "Sensor dirty/blockage" 2 "Sensor not available/Failure" 3 "Invalid" ;
VAL_ 602 ADCU_SVM_RearCam_Check 0 "Available" 1 "Sensor dirty/blockage" 2 "Sensor not available/Failure" 3 "Invalid" ;
VAL_ 602 ADCU_SVM_LeftCamera_Check 0 "Available" 1 "Sensor dirty/blockage" 2 "Sensor not available/Failure" 3 "Invalid" ;
VAL_ 602 ADCU_SVM_RightCamera_Check 0 "Available" 1 "Sensor dirty/blockage" 2 "Sensor not available/Failure" 3 "Invalid" ;
VAL_ 602 ADCU_TopRearCamera_Check 0 "Available" 1 "Sensor dirty/blockage" 2 "Sensor not available/Failure" 3 "Invalid" ;
VAL_ 602 ADCU_USS_FIL_Check 0 "Available" 1 "Sensor dirty/blockage" 2 "Sensor not available/Failure" 3 "Invalid" ;
VAL_ 602 ADCU_USS_FIR_Check 0 "Available" 1 "Sensor dirty/blockage" 2 "Sensor not available/Failure" 3 "Invalid" ;
VAL_ 602 ADCU_USS_FOL_Check 0 "Available" 1 "Sensor dirty/blockage" 2 "Sensor not available/Failure" 3 "Invalid" ;
VAL_ 602 ADCU_USS_FOR_Check 0 "Available" 1 "Sensor dirty/blockage" 2 "Sensor not available/Failure" 3 "Invalid" ;
VAL_ 602 ADCU_USS_FSL_Check 0 "Available" 1 "Sensor dirty/blockage" 2 "Sensor not available/Failure" 3 "Invalid" ;
VAL_ 602 ADCU_USS_FSR_Check 0 "Available" 1 "Sensor dirty/blockage" 2 "Sensor not available/Failure" 3 "Invalid" ;
VAL_ 602 ADCU_USS_RIL_Check 0 "Available" 1 "Sensor dirty/blockage" 2 "Sensor not available/Failure" 3 "Invalid" ;
VAL_ 602 ADCU_USS_RIR_Check 0 "Available" 1 "Sensor dirty/blockage" 2 "Sensor not available/Failure" 3 "Invalid" ;
VAL_ 602 ADCU_USS_ROL_Check 0 "Available" 1 "Sensor dirty/blockage" 2 "Sensor not available/Failure" 3 "Invalid" ;
VAL_ 602 ADCU_USS_ROR_Check 0 "Available" 1 "Sensor dirty/blockage" 2 "Sensor not available/Failure" 3 "Invalid" ;
VAL_ 602 ADCU_USS_RSL_Check 0 "Available" 1 "Sensor dirty/blockage" 2 "Sensor not available/Failure" 3 "Invalid" ;
VAL_ 602 ADCU_USS_RSR_Check 0 "Available" 1 "Sensor dirty/blockage" 2 "Sensor not available/Failure" 3 "Invalid" ;
VAL_ 602 ADCU_SVM_GMSL_Check 0 "Available" 1 "GMSL Link failure" 2 "Reserved" 3 "Invalid" ;
VAL_ 602 ADCU_OS_Check 0 "Shutdown" 1 "Booting" 2 "Ready" 3 "Reboot" 4 "ADCU Hang" 5 "Failed safe state" 7 "Invalid" ;
VAL_ 602 ADCU_ErrFCAM_SnSr_Diag 0 "state 0" 1 "state 1" 2 "state 2" 3 "state 3" 4 "state 4" 5 "state 5" 6 "state 6" 7 "state 7" 8 "state 8" 9 "state 9" 10 "state 10" 11 "state 11" 12 "state 12" 13 "state 13" 14 "state 14" 15 "state 15" ;
VAL_ 602 ADCU_ErrFCAM_Feature_Diag 0 "state 0" 1 "state 1" 2 "state 2" 3 "state 3" 4 "state 4" 5 "state 5" 6 "state 6" 7 "state 7" 8 "state 8" 9 "state 9" 10 "state 10" 11 "state 11" 12 "state 12" 13 "state 13" 14 "state 14" 15 "state 15" ;
VAL_ 549 ADCU_TLD_state 0 "Inactive" 1 "Active" 2 "Fault" 3 "Invalid" ;
VAL_ 549 ADCU_TLD_light_color 0 "None" 1 "Red" 2 "Green" 3 "Yellow" 4 "Yellow Blink" 5 "Suspend" 6 "Abort" 7 "Fault" ;
VAL_ 549 ADCU_TLD_light_lane 0 "value 0" 1 "value 1" 2 "value 2" 3 "value 3" ;
VAL_ 648 ADCU_MHU_VAP_SessionMode 0 "Init" 1 "Park In via MHU" 2 "Park In continue Remote" 3 "Comfort Park In via MHU" 4 "Comfort Park In Continue Remote" 5 "Park Out via MHU" 6 "Park Out via Remote" 7 "Comfort Park Out via MHU" 8 "Comfort Park Out via Remote" 9 "Reverse Forward via MHU" 10 "Reverse Forward via Remote" 11 "Reverse Backward via MHU" 12 "Straight Parking" ;
VAL_ 648 ADCU_MHU_VAP_SessionState 0 "OFF" 1 "Init" 2 "Disable" 3 "Load" 4 "Standby/Idle" 5 "Prepare" 6 "Handshake" 7 "Active" 8 "Completed/Finished" 9 "Suspend/Pause" 10 "Abort" 11 "Degraded" 12 "FailSafe" 13 "Error" 14 "Failure/Fata" 15 "Cancel" ;
VAL_ 648 ADCU_MHU_VAP_NoseDir 0 "Init" 1 "Nose Out" 2 "Nose In" 3 "Reserve" ;
VAL_ 648 ADCU_MHU_VAP_ParkAngle 0 "0 deg" 1 "'Angled 45deg" 2 "90deg" 3 "Angled 135deg" ;
VAL_ 648 ADCU_MHU_VAP_History_ParkIn 0 "None" 1 "Park In" 2 "Comfort Park In" ;
VAL_ 648 ADCU_MHU_VAP_History_NoseDir 0 "Init" 1 "Nose Out" 2 "Nose In" 3 "Reserve" ;
VAL_ 648 ADCU_MHU_VAP_History_ParkAngle 0 "0 deg" 1 "'Angled 45deg" 2 "90deg" 3 "Angled 135deg" ;
VAL_ 648 ADCU_MHU_VAP_Available 0 "Available" 1 "Busy" ;
VAL_ 650 ADCU_TBOX_VAP_SessionMode 0 "Init" 1 "Park In via MHU" 2 "Park In continue Remote" 3 "Comfort Park In via MHU" 4 "Comfort Park In Continue Remote" 5 "Park Out via MHU" 6 "Park Out via Remote" 7 "Comfort Park Out via MHU" 8 "Comfort Park Out via Remote" 9 "Reverse Forward via MHU" 10 "Reverse Forward via Remote" 11 "Reverse Backward via MHU" 12 "Straight Parking" ;
VAL_ 650 ADCU_TBOX_VAP_SessionState 0 "OFF" 1 "Init" 2 "Disable" 3 "Load" 4 "Standby/Idle" 5 "Prepare" 6 "Handshake" 7 "Active" 8 "Completed/Finished" 9 "Suspend/Pause" 10 "Abort" 11 "Degraded" 12 "FailSafe" 13 "Error" 14 "Failure/Fata" 15 "Cancel" ;
VAL_ 650 ADCU_TBOX_VAP_NoseDir 0 "Init" 1 "Nose Out" 2 "Nose In" 3 "Reserve" ;
VAL_ 650 ADCU_TBOX_VAP_ParkAngle 0 "0 deg" 1 "'Angled 45deg" 2 "90deg" 3 "Angled 135deg" ;
VAL_ 650 ADCU_TBOX_VAP_History_ParkIn 0 "None" 1 "Park In" 2 "Comfort Park In" ;
VAL_ 650 ADCU_TBOX_VAP_History_NoseDir 0 "Init" 1 "Nose Out" 2 "Nose In" 3 "Reserve" ;
VAL_ 650 ADCU_TBOX_VAP_History_ParkAngle 0 "0 deg" 1 "'Angled 45deg" 2 "90deg" 3 "Angled 135deg" ;
VAL_ 650 ADCU_TBOX_VAP_Available 0 "Available" 1 "Busy" ;
VAL_ 652 ADCU_MHU_VPARK_MHU_Txt1_Notif 0 "No_Request" 1 "PAS internal failure" 2 "Related external ECU failure" 3 "Conflict with other functions" 4 "Door Opening Status" 5 "Rear Trunk" 6 "TPMS Tire Pressure" 7 "Trailer Connection" 8 "Charging Plug Connected stat" 9 "Outside Rearview Mirror (folding status)" 10 "EPB Applied" 11 "Over Speed" 12 "Remote device connected" 13 "Suspension height configuration" ;
VAL_ 652 ADCU_MHU_VPARK_MHU_Txt2_Notif 0 "No request" 1 "Doors Opening stat" 2 "Rear Trunk" 3 "Slow Down" 4 "User distance is too far from the selected spot" 5 "Pedestrian Crossing within path (lines) - RESERVED" ;
VAL_ 652 ADCU_MHU_VPARK_MHU_Txt3_Notif 0 "No request" 1 "Doors Opening stat" 2 "Rear Trunk" 3 "Frunk (hood, front trunk, bonnet)" 4 "Charging Port Opening stat" 5 "Outside Rearview Mirror (folding status)" 6 "Steering Wheel Drive Torque Detection" 7 "Seatbelts buckle" 8 "Driver Occupancy Monitoring (to ensure a driver)" 9 "Passenger Occupancy (Seat Occupancy)" 10 "Child Presence Detection" 11 "Remote device connected" 12 "Remote device in range 6m" 13 "Remote device in range 15m" 14 "Remote device in range 30m" 15 "Remote device in range 40m" 16 "Pause Button Pressed" 17 "Brake Pedal Pressed (soft press)" 18 "Obstacle Detected >3s" 19 "CAPP Button Depressed" 20 "Pedestrian Crossing within path (lines)" 21 "Pause Condition Resolved - Resume Available " ;
VAL_ 652 ADCU_MHU_VPARK_MHU_Txt4_Notif 0 "No Request" 1 "TPMS Tire Pressure" 2 "Trailer Connection" 3 "Charging Plug Connected stat" 4 "Airbag Health SCM" 5 "Throttle (acc pedal pressed)" 6 "Slope / inclination" 7 "EPB Applied" 8 "Ego braked (main braked - hard brake)" 9 "Over Speed" 10 "PAS internal failure" 11 "Related external ECU failure" 12 "Conflict with other functions (ACC/HWA/NOP)" 13 "Soft Brake for RP" 14 "Pause Timeout" 15 "Small Spot" 16 "MHU Cancel Button Pressed" 17 "CAPP Cancel Button Pressed" 18 "Remote Device Failure" 19 "Remote Connection Overtime out" 20 "Attempts Exceeded" 21 "Moving Control Timeout" 22 "Input at PRDN Stalk" 23 "Lane validation / Free Space" 24 "max distance reached" 25 "previous trajectory not retrieved" 26 "keyfob" ;
VAL_ 652 ADCU_MHU_VPARK_CAPP_Txt1_Notif 0 "No_Request" 1 "PAS internal failure" 2 "Related external ECU failure" 3 "Conflict with other functions" 4 "Door Opening Status" 5 "Rear Trunk" 6 "TPMS Tire Pressure" 7 "Trailer Connection" 8 "Charging Plug Connected stat" 9 "Outside Rearview Mirror (folding status)" 10 "EPB Applied" 11 "Over Speed" 12 "Remote device connected" 13 "Suspension height configuration" ;
VAL_ 652 ADCU_MHU_VPARK_CAPP_Txt2_Notif 0 "No request" 1 "Doors Opening stat" 2 "Rear Trunk" 3 "Slow Down" 4 "User distance is too far from the selected spot" 5 "Pedestrian Crossing within path (lines) - RESERVED" ;
VAL_ 652 ADCU_MHU_VPARK_CAPP_Txt3_Notif 0 "No request" 1 "Doors Opening stat" 2 "Rear Trunk" 3 "Frunk (hood, front trunk, bonnet)" 4 "Charging Port Opening stat" 5 "Outside Rearview Mirror (folding status)" 6 "Steering Wheel Drive Torque Detection" 7 "Seatbelts buckle" 8 "Driver Occupancy Monitoring (to ensure a driver)" 9 "Passenger Occupancy (Seat Occupancy)" 10 "Child Presence Detection" 11 "Remote device connected" 12 "Remote device in range 6m" 13 "Remote device in range 15m" 14 "Remote device in range 30m" 15 "Remote device in range 40m" 16 "Pause Button Pressed" 17 "Brake Pedal Pressed (soft press)" 18 "Obstacle Detected >3s" 19 "CAPP Button Depressed" 20 "Pedestrian Crossing within path (lines)" 21 "Pause Condition Resolved - Resume Available " ;
VAL_ 652 ADCU_MHU_VPARK_CAPP_Txt4_Notif 0 "TPMS Tire Pressure" 1 "Trailer Connection" 2 "Charging Plug Connected stat" 3 "Airbag Health SCM" 4 "Throttle (acc pedal pressed)" 5 "Slope / inclination" 6 "EPB Applied" 7 "Ego braked (main braked - hard brake)" 8 "Over Speed" 9 "PAS internal failure" 10 "Related external ECU failure" 11 "Conflict with other functions (ACC/HWA/NOP)" 12 "Soft Brake for RP" 13 "Pause Timeout" 14 "Small Spot" 15 "MHU Cancel Button Pressed" 16 "CAPP Cancel Button Pressed" 17 "Remote Device Failure (Reserved)" 18 "Remote Connection Overtime out" 19 "Attempts Exceeded" 20 "Moving Control Timeout" 21 "Input at PRDN Stalk" 22 "Lane validation / Free Space" 23 "max distance reached" 24 "previous trajectory not retrieved" 25 "keyfob" ;
VAL_ 1041 ADCU_DCM_Status 0 "Normal" 1 "Fault" 2 "Reserved" ;
VAL_ 1041 ADCU_DashCam_Status 0 "TransferMode" 1 "TransferAborted" 2 "Reserved" 3 "Signal invalid" ;
